VERSION "dbc-export 1 2026.26.6.5"

NS_ :

BS_:

BU_: APB APP APS DAS EPAS3S ESP GTW IBST PARK RADC RCM TPMS TRCM USM

BO_ 921 DAS_status: 8 DAS
 SG_ DAS_autopilotState : 0|4@1+ (1,0) [0|14] "" Vector__XXX
 SG_ DAS_blindSpotRearLeft : 4|2@1+ (1,0) [0|2] "" Vector__XXX
 SG_ DAS_blindSpotRearRight : 6|2@1+ (1,0) [0|2] "" Vector__XXX
 SG_ DAS_fusedSpeedLimit : 8|5@1+ (5,0) [5|150] "kph/mph" Vector__XXX
 SG_ DAS_suppressSpeedWarning : 13|1@1+ (1,0) [0|1] "" Vector__XXX
 SG_ DAS_summonObstacle : 14|1@1+ (1,0) [0|1] "" Vector__XXX
 SG_ DAS_summonClearedGate : 15|1@1+ (1,0) [0|1] "" Vector__XXX
 SG_ DAS_visionOnlySpeedLimit : 16|5@1+ (5,0) [5|150] "kph/mph" Vector__XXX
 SG_ DAS_heaterState : 21|1@1+ (1,0) [0|1] "" Vector__XXX
 SG_ DAS_forwardCollisionWarning : 22|2@1+ (1,0) [0|2] "" Vector__XXX
 SG_ DAS_autoparkReady : 24|1@1+ (1,0) [0|1] "" Vector__XXX
 SG_ DAS_autoParked : 25|1@1+ (1,0) [0|1] "" Vector__XXX
 SG_ DAS_autoparkActive : 26|1@1+ (1,0) [0|1] "" Vector__XXX
 SG_ DAS_summonFwdLeashReached : 27|1@1+ (1,0) [0|1] "" Vector__XXX
 SG_ DAS_summonRvsLeashReached : 28|1@1+ (1,0) [0|1] "" Vector__XXX
 SG_ DAS_lssState : 29|3@1+ (1,0) [0|7] "" Vector__XXX
 SG_ DAS_sideCollisionAvoid : 32|2@1+ (1,0) [0|2] "" Vector__XXX
 SG_ DAS_sideCollisionWarning : 34|2@1+ (1,0) [0|3] "" Vector__XXX
 SG_ DAS_sideCollisionInhibit : 36|1@1+ (1,0) [0|1] "" Vector__XXX
 SG_ DAS_laneDepartureWarning : 37|3@1+ (1,0) [0|7] "" Vector__XXX
 SG_ DAS_fleetSpeedState : 40|2@1+ (1,0) [0|3] "" Vector__XXX
 SG_ DAS_autopilotHandsOnState : 42|4@1+ (1,0) [0|14] "" Vector__XXX
 SG_ DAS_autoLaneChangeState : 46|5@1+ (1,0) [0|30] "" Vector__XXX
 SG_ DAS_summonAvailable : 51|1@1+ (1,0) [0|1] "" Vector__XXX
 SG_ DAS_statusCounter : 52|4@1+ (1,0) [0|15] "" Vector__XXX
 SG_ DAS_statusChecksum : 56|8@1+ (1,0) [0|255] "" Vector__XXX

BO_ 905 DAS_status2: 8 DAS
 SG_ DAS_accSpeedLimit : 0|9@1+ (0.4,0) [0|200] "mph" Vector__XXX
 SG_ DAS_versionIdentifier : 9|1@1+ (1,0) [0|1] "" Vector__XXX
 SG_ DAS_pmmObstacleSeverity : 10|3@1+ (1,0) [0|6] "" Vector__XXX
 SG_ DAS_pmmLoggingRequest : 13|1@1+ (1,0) [0|1] "" Vector__XXX
 SG_ DAS_activationFailureStatus : 14|2@1+ (1,0) [0|3] "" Vector__XXX
 SG_ DAS_pmmUltrasonicsFaultReason : 16|3@1+ (1,0) [0|7] "" Vector__XXX
 SG_ DAS_pmmRadarFaultReason : 19|2@1+ (1,0) [0|3] "" Vector__XXX
 SG_ DAS_pmmSysFaultReason : 21|3@1+ (1,0) [0|7] "" Vector__XXX
 SG_ DAS_pmmCameraFaultReason : 24|2@1+ (1,0) [0|3] "" Vector__XXX
 SG_ DAS_ACC_report : 26|5@1+ (1,0) [0|31] "" Vector__XXX
 SG_ DAS_relaxCruiseLimits : 31|1@1+ (1,0) [0|1] "" Vector__XXX
 SG_ DAS_csaState : 32|2@1+ (1,0) [0|3] "" Vector__XXX
 SG_ DAS_radarTelemetry : 34|2@1+ (1,0) [0|3] "" Vector__XXX
 SG_ DAS_robState : 36|2@1+ (1,0) [0|3] "" Vector__XXX
 SG_ DAS_driverInteractionLevel : 38|2@1+ (1,0) [0|3] "" Vector__XXX
 SG_ DAS_ppOffsetDesiredRamp : 40|8@1+ (0.01,-1.28) [-1.28|1.27] "m" Vector__XXX
 SG_ DAS_longCollisionWarning : 48|4@1+ (1,0) [0|14] "" Vector__XXX
 SG_ DAS_status2Counter : 52|4@1+ (1,0) [0|15] "" Vector__XXX
 SG_ DAS_status2Checksum : 56|8@1+ (1,0) [0|255] "" Vector__XXX

BO_ 586 DAS_visualDebug: 8 DAS
 SG_ DAS_autosteerVehiclesUsage : 4|2@1+ (1,0) [0|3] "" Vector__XXX
 SG_ DAS_autosteerHPPUsage : 6|2@1+ (1,0) [0|3] "" Vector__XXX
 SG_ DAS_autosteerNavigationUsage : 8|2@1+ (1,0) [0|3] "" Vector__XXX
 SG_ DAS_autosteerModelUsage : 10|2@1+ (1,0) [0|3] "" Vector__XXX
 SG_ DAS_autosteerBottsDotsUsage : 12|2@1+ (1,0) [0|3] "" Vector__XXX
 SG_ DAS_offsetSide : 14|2@1+ (1,0) [0|3] "" Vector__XXX
 SG_ DAS_roadSurfaceType : 16|2@1+ (1,0) [1|3] "" Vector__XXX
 SG_ DAS_autosteerHealthAnomalyLevel : 18|3@1+ (1,0) [0|7] "" Vector__XXX
 SG_ DAS_autosteerHealthState : 21|3@1+ (1,0) [0|7] "" Vector__XXX
 SG_ DAS_lastLinePreferenceReason : 24|4@1+ (1,0) [0|15] "" Vector__XXX
 SG_ DAS_plannerState : 28|4@1+ (1,0) [0|15] "" Vector__XXX
 SG_ DAS_lastAutosteerAbortReason : 32|6@1+ (1,0) [0|63] "" Vector__XXX
 SG_ DAS_devAppInterfaceEnabled : 38|1@1+ (1,0) [0|1] "" Vector__XXX
 SG_ DAS_navAvailable : 39|1@1+ (1,0) [0|1] "" Vector__XXX
 SG_ DAS_navDistance : 40|8@1+ (100,0) [0|25500] "km" Vector__XXX
 SG_ DAS_accSmartSpeedActive : 48|1@1+ (1,0) [0|1] "" Vector__XXX
 SG_ DAS_accSmartSpeedState : 49|3@1+ (1,0) [0|6] "" Vector__XXX
 SG_ DAS_ulcInProgress : 52|1@1+ (1,0) [0|1] "" Vector__XXX
 SG_ DAS_trafficAwareSetSpeedInUse : 53|1@1+ (1,0) [0|1] "" Vector__XXX
 SG_ DAS_isaSystemState : 54|2@1+ (1,0) [0|3] "" Vector__XXX
 SG_ DAS_behaviorType : 56|2@1+ (1,0) [0|3] "" Vector__XXX
 SG_ DAS_ulcType : 58|2@1+ (1,0) [0|3] "" Vector__XXX
 SG_ DAS_rearVehDetectedThisCycle : 60|1@1+ (1,0) [0|1] "" Vector__XXX
 SG_ DAS_rearLeftVehDetectedCurrent : 61|1@1+ (1,0) [0|1] "" Vector__XXX
 SG_ DAS_rearRightVehDetectedTrip : 62|1@1+ (1,0) [0|1] "" Vector__XXX
 SG_ DAS_rearLeftVehDetectedTrip : 63|1@1+ (1,0) [0|1] "" Vector__XXX

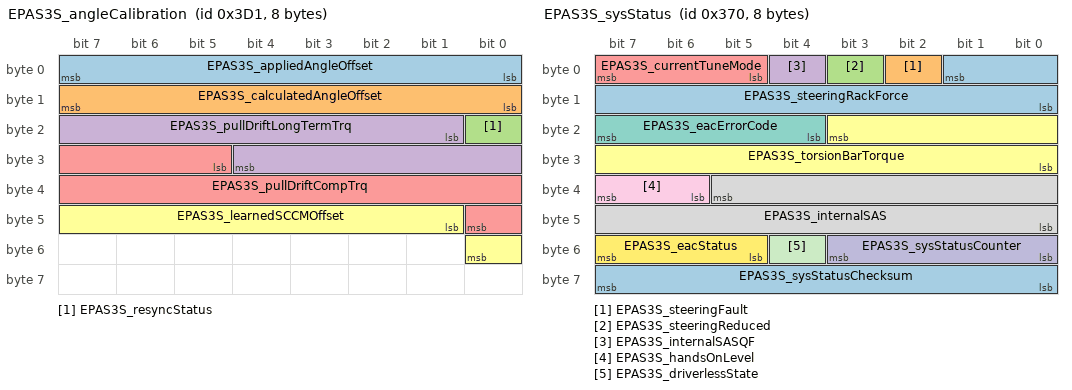
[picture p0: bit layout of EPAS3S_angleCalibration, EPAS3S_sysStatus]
BO_ 977 EPAS3S_angleCalibration: 8 EPAS3S
 SG_ EPAS3S_appliedAngleOffset : 0|8@1+ (0.1,-12.8) [-12.8|12.7] "deg" Vector__XXX
 SG_ EPAS3S_calculatedAngleOffset : 8|8@1+ (0.1,-12.8) [-12.8|12.7] "deg" Vector__XXX
 SG_ EPAS3S_resyncStatus : 16|1@1+ (1,0) [0|1] "" Vector__XXX
 SG_ EPAS3S_pullDriftLongTermTrq : 17|12@1+ (0.01,-10) [-10|10] "Nm" Vector__XXX
 SG_ EPAS3S_pullDriftCompTrq : 29|12@1+ (0.01,-10) [-10|10] "Nm" Vector__XXX
 SG_ EPAS3S_learnedSCCMOffset : 41|8@1+ (0.1,-12.8) [-12.8|12.7] "deg" Vector__XXX

BO_ 785 EPAS3S_info: 8 EPAS3S
 SG_ EPAS3S_infoIndex M : 0|8@1+ (1,0) [0|255] "" Vector__XXX
 SG_ EPAS3S_infoBuildType m10 : 8|8@1+ (1,0) [0|255] "" Vector__XXX
 SG_ EPAS3S_infoComponentID m10 : 48|16@1+ (1,0) [0|65535] "" Vector__XXX
 SG_ EPAS3S_infoPcbaID m11 : 16|8@1+ (1,0) [0|255] "" Vector__XXX
 SG_ EPAS3S_infoAssemblyID m11 : 24|8@1+ (1,0) [0|255] "" Vector__XXX
 SG_ EPAS3S_infoUsageID m11 : 32|16@1+ (1,0) [0|65535] "" Vector__XXX
 SG_ EPAS3S_infoApplicationCRC m13 : 32|32@1+ (1,0) [0|4294967295] "" Vector__XXX
 SG_ EPAS3S_infoBootUdsProtoVersion m20 : 8|8@1+ (1,0) [0|255] "" Vector__XXX
 SG_ EPAS3S_infoBootloaderCRC m20 : 32|32@1+ (1,0) [0|4294967295] "" Vector__XXX
 SG_ EPAS3S_infoSubcomponent2 m23 : 32|32@1+ (1,0) [0|4294967295] "" Vector__XXX

BO_ 880 EPAS3S_sysStatus: 8 EPAS3S
 SG_ EPAS3S_steeringRackForce : 1|10@0+ (50,-25575) [-25575|25525] "N" Vector__XXX
 SG_ EPAS3S_steeringFault : 2|1@1+ (1,0) [0|1] "" Vector__XXX
 SG_ EPAS3S_steeringReduced : 3|1@1+ (1,0) [0|1] "" Vector__XXX
 SG_ EPAS3S_internalSASQF : 4|1@1+ (1,0) [0|1] "" Vector__XXX
 SG_ EPAS3S_currentTuneMode : 5|3@1+ (1,0) [0|7] "" Vector__XXX
 SG_ EPAS3S_torsionBarTorque : 19|12@0+ (0.01,-20.5) [-20.5|20.44] "Nm" Vector__XXX
 SG_ EPAS3S_eacErrorCode : 20|4@1+ (1,0) [0|14] "" Vector__XXX
 SG_ EPAS3S_internalSAS : 37|14@0+ (0.1,-819.2) [-819.2|819] "deg" Vector__XXX
 SG_ EPAS3S_handsOnLevel : 38|2@1+ (1,0) [0|3] "" Vector__XXX
 SG_ EPAS3S_sysStatusCounter : 48|4@1+ (1,0) [0|15] "" Vector__XXX
 SG_ EPAS3S_driverlessState : 52|1@1+ (1,0) [0|1] "" Vector__XXX
 SG_ EPAS3S_eacStatus : 53|3@1+ (1,0) [0|7] "" Vector__XXX
 SG_ EPAS3S_sysStatusChecksum : 56|8@1+ (1,0) [0|255] "" Vector__XXX

BO_ 805 ESP_info: 8 ESP
 SG_ ESP_infoIndex M : 0|8@1+ (1,0) [0|255] "" Vector__XXX
 SG_ ESP_infoBuildType m10 : 8|8@1+ (1,0) [0|255] "" Vector__XXX
 SG_ ESP_infoComponentID m10 : 48|16@1+ (1,0) [0|65535] "" Vector__XXX
 SG_ ESP_infoPcbaID m11 : 16|8@1+ (1,0) [0|255] "" Vector__XXX
 SG_ ESP_infoAssemblyID m11 : 24|8@1+ (1,0) [0|255] "" Vector__XXX
 SG_ ESP_infoUsageID m11 : 32|16@1+ (1,0) [0|65535] "" Vector__XXX
 SG_ ESP_infoSubUsageID m11 : 48|16@1+ (1,0) [0|65535] "" Vector__XXX
 SG_ ESP_infoApplicationCRC m13 : 39|32@0+ (1,0) [0|4294967295] "" Vector__XXX
 SG_ ESP_infoVehicleVariant m16 : 16|8@1+ (1,0) [0|255] "" Vector__XXX
 SG_ ESP_infoSubcomponent1 m16 : 32|32@1+ (1,0) [0|4294967295] "" Vector__XXX
 SG_ ESP_infoBootUdsProtoVersion m20 : 8|8@1+ (1,0) [0|255] "" Vector__XXX
 SG_ ESP_infoBootloaderCRC m20 : 32|32@1+ (1,0) [0|4294967295] "" Vector__XXX
 SG_ ESP_infoVariantCRC m22 : 39|32@0+ (1,0) [0|4294967295] "" Vector__XXX

BO_ 813 IBST_info: 8 IBST
 SG_ IBST_infoIndex M : 0|8@1+ (1,0) [0|255] "" Vector__XXX
 SG_ IBST_infoBuildType m10 : 8|8@1+ (1,0) [0|255] "" Vector__XXX
 SG_ IBST_infoComponentID m10 : 55|16@0+ (1,0) [0|65535] "" Vector__XXX
 SG_ IBST_infoPcbaID m11 : 16|8@1+ (1,0) [0|255] "" Vector__XXX
 SG_ IBST_infoAssemblyID m11 : 24|8@1+ (1,0) [0|255] "" Vector__XXX
 SG_ IBST_infoUsageID m11 : 32|16@1+ (1,0) [0|65535] "" Vector__XXX
 SG_ IBST_infoSubUsageID m11 : 48|16@1+ (1,0) [0|65535] "" Vector__XXX
 SG_ IBST_infoApplicationCRC m13 : 32|32@1+ (1,0) [0|4294967295] "" Vector__XXX
 SG_ IBST_infoBootUdsProtoVersion m20 : 8|8@1+ (1,0) [0|255] "" Vector__XXX
 SG_ IBST_infoBootloaderCRC m20 : 32|32@1+ (1,0) [0|4294967295] "" Vector__XXX
 SG_ IBST_infoVariantCRC m22 : 32|32@1+ (1,0) [0|4294967295] "" Vector__XXX

BO_ 806 PARK_info: 8 PARK
 SG_ PARK_infoIndex M : 0|8@1+ (1,0) [0|255] "" Vector__XXX
 SG_ PARK_infoBuildType m10 : 8|8@1+ (1,0) [0|255] "" Vector__XXX
 SG_ PARK_infoComponentID m10 : 48|16@1+ (1,0) [0|65535] "" Vector__XXX
 SG_ PARK_infoPcbaID m11 : 16|8@1+ (1,0) [0|255] "" Vector__XXX
 SG_ PARK_infoAssemblyID m11 : 24|8@1+ (1,0) [0|255] "" Vector__XXX
 SG_ PARK_infoUsageID m11 : 32|16@1+ (1,0) [0|65535] "" Vector__XXX
 SG_ PARK_infoApplicationCRC m13 : 32|32@1+ (1,0) [0|4294967295] "" Vector__XXX
 SG_ PARK_infoBootUdsProtoVersion m20 : 8|8@1+ (1,0) [0|255] "" Vector__XXX
 SG_ PARK_infoBootloaderCRC m20 : 32|32@1+ (1,0) [0|4294967295] "" Vector__XXX

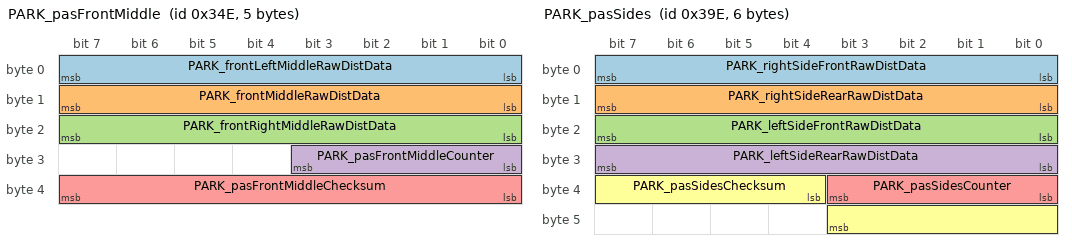
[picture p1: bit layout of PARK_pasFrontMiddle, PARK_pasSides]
BO_ 846 PARK_pasFrontMiddle: 5 PARK
 SG_ PARK_frontLeftMiddleRawDistData : 0|8@1+ (1,0) [0|254] "cm" Vector__XXX
 SG_ PARK_frontMiddleRawDistData : 8|8@1+ (1,0) [0|254] "cm" Vector__XXX
 SG_ PARK_frontRightMiddleRawDistData : 16|8@1+ (1,0) [0|254] "cm" Vector__XXX
 SG_ PARK_pasFrontMiddleCounter : 24|4@1+ (1,0) [0|15] "" Vector__XXX
 SG_ PARK_pasFrontMiddleChecksum : 32|8@1+ (1,0) [0|255] "" Vector__XXX

BO_ 926 PARK_pasSides: 6 PARK
 SG_ PARK_rightSideFrontRawDistData : 0|8@1+ (1,0) [0|254] "cm" Vector__XXX
 SG_ PARK_rightSideRearRawDistData : 8|8@1+ (1,0) [0|254] "cm" Vector__XXX
 SG_ PARK_leftSideFrontRawDistData : 16|8@1+ (1,0) [0|254] "cm" Vector__XXX
 SG_ PARK_leftSideRearRawDistData : 24|8@1+ (1,0) [0|254] "cm" Vector__XXX
 SG_ PARK_pasSidesCounter : 32|4@1+ (1,0) [0|15] "" Vector__XXX
 SG_ PARK_pasSidesChecksum : 36|8@1+ (1,0) [0|255] "" Vector__XXX

BO_ 606 PARK_pscEnvSlot: 8 PARK
 SG_ PARK_pscEnvSlotType M : 0|2@1+ (1,0) [0|3] "" Vector__XXX
 SG_ PARK_pscLeftParallelObj1X m0 : 3|11@1+ (2,-2048) [-2048|2044] "cm" Vector__XXX
 SG_ PARK_pscLeftParallelObj1Y m0 : 14|11@1+ (2,-2048) [-2048|2044] "cm" Vector__XXX
 SG_ PARK_pscLeftParallelObj1Alpha m0 : 25|7@1+ (2,-128) [-128|124] "deg" Vector__XXX
 SG_ PARK_pscLeftParallelObj2Y m0 : 35|11@1+ (2,-2048) [-2048|2044] "cm" Vector__XXX
 SG_ PARK_pscLeftParallelObj2X m0 : 46|11@1+ (2,-2048) [-2048|2044] "cm" Vector__XXX
 SG_ PARK_pscLeftParallelObj2Alpha m0 : 57|7@1+ (2,-128) [-128|124] "deg" Vector__XXX
 SG_ PARK_pscLeftCrossObj1X m1 : 3|11@1+ (2,-2048) [-2048|2044] "cm" Vector__XXX
 SG_ PARK_pscLeftCrossObj1Y m1 : 14|11@1+ (2,-2048) [-2048|2044] "cm" Vector__XXX
 SG_ PARK_pscLeftCrossObj1Alpha m1 : 25|7@1+ (2,-128) [-128|124] "deg" Vector__XXX
 SG_ PARK_pscLeftCrossObj2Y m1 : 35|11@1+ (2,-2048) [-2048|2044] "cm" Vector__XXX
 SG_ PARK_pscLeftCrossObj2X m1 : 46|11@1+ (2,-2048) [-2048|2044] "cm" Vector__XXX
 SG_ PARK_pscLeftCrossObj2Alpha m1 : 57|7@1+ (2,-128) [-128|124] "deg" Vector__XXX
 SG_ PARK_pscRightParallelObj1X m2 : 3|11@1+ (2,-2048) [-2048|2044] "cm" Vector__XXX
 SG_ PARK_pscRightParallelObj1Y m2 : 14|11@1+ (2,-2048) [-2048|2044] "cm" Vector__XXX
 SG_ PARK_pscRightParallelObj1Alpha m2 : 25|7@1+ (2,-128) [-128|124] "deg" Vector__XXX
 SG_ PARK_pscRightParallelObj2Y m2 : 35|11@1+ (2,-2048) [-2048|2044] "cm" Vector__XXX
 SG_ PARK_pscRightParallelObj2X m2 : 46|11@1+ (2,-2048) [-2048|2044] "cm" Vector__XXX
 SG_ PARK_pscRightParallelObj2Alpha m2 : 57|7@1+ (2,-128) [-128|124] "deg" Vector__XXX
 SG_ PARK_pscRightCrossObj1X m3 : 3|11@1+ (2,-2048) [-2048|2044] "cm" Vector__XXX
 SG_ PARK_pscRightCrossObj1Y m3 : 14|11@1+ (2,-2048) [-2048|2044] "cm" Vector__XXX
 SG_ PARK_pscRightCrossObj1Alpha m3 : 25|7@1+ (2,-128) [-128|124] "deg" Vector__XXX
 SG_ PARK_pscRightCrossObj2Y m3 : 35|11@1+ (2,-2048) [-2048|2044] "cm" Vector__XXX
 SG_ PARK_pscRightCrossObj2X m3 : 46|11@1+ (2,-2048) [-2048|2044] "cm" Vector__XXX
 SG_ PARK_pscRightCrossObj2Alpha m3 : 57|7@1+ (2,-128) [-128|124] "deg" Vector__XXX

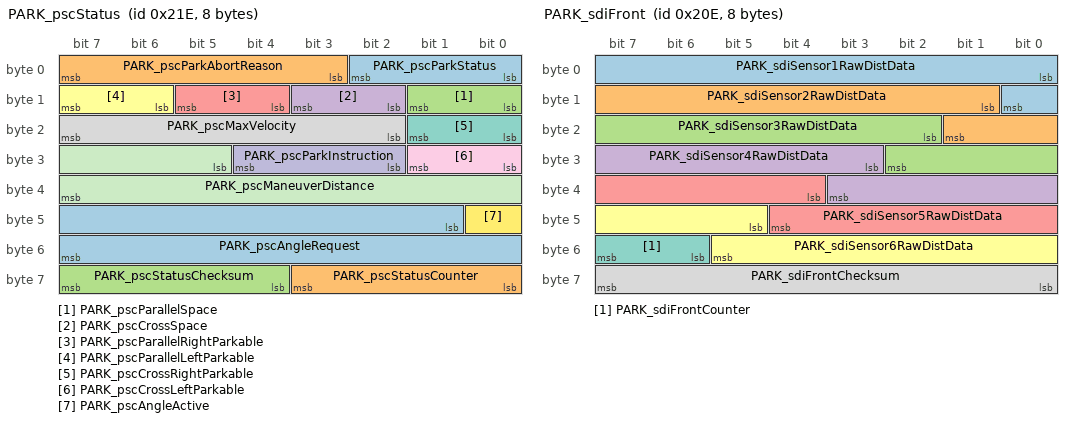
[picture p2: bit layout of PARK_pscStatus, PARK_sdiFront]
BO_ 542 PARK_pscStatus: 8 PARK
 SG_ PARK_pscParkStatus : 0|3@1+ (1,0) [0|6] "" Vector__XXX
 SG_ PARK_pscParkAbortReason : 3|5@1+ (1,0) [0|30] "" Vector__XXX
 SG_ PARK_pscParallelSpace : 8|2@1+ (1,0) [0|3] "" Vector__XXX
 SG_ PARK_pscCrossSpace : 10|2@1+ (1,0) [0|3] "" Vector__XXX
 SG_ PARK_pscParallelRightParkable : 12|2@1+ (1,0) [0|2] "" Vector__XXX
 SG_ PARK_pscParallelLeftParkable : 14|2@1+ (1,0) [0|2] "" Vector__XXX
 SG_ PARK_pscCrossRightParkable : 16|2@1+ (1,0) [0|2] "" Vector__XXX
 SG_ PARK_pscMaxVelocity : 18|6@1+ (0.1,0) [0|6.2] "kph" Vector__XXX
 SG_ PARK_pscCrossLeftParkable : 24|2@1+ (1,0) [0|2] "" Vector__XXX
 SG_ PARK_pscParkInstruction : 26|3@1+ (1,0) [0|6] "" Vector__XXX
 SG_ PARK_pscManeuverDistance : 29|11@1+ (1,0) [0|2046] "cm" Vector__XXX
 SG_ PARK_pscAngleActive : 40|1@1+ (1,0) [0|1] "" Vector__XXX
 SG_ PARK_pscAngleRequest : 41|15@1+ (0.1,-1638.4) [-1638.4|1638.3] "deg" Vector__XXX
 SG_ PARK_pscStatusCounter : 56|4@1+ (1,0) [0|15] "" Vector__XXX
 SG_ PARK_pscStatusChecksum : 60|4@1+ (1,0) [0|15] "" Vector__XXX

BO_ 590 PARK_pscVehSlot: 8 PARK
 SG_ PARK_pscVehSlotType M : 0|2@1+ (1,0) [0|3] "" Vector__XXX
 SG_ PARK_pscLeftParallelVehX m0 : 5|11@1+ (2,-2048) [-2048|2044] "cm" Vector__XXX
 SG_ PARK_pscLeftParallelVehY m0 : 16|11@1+ (2,-2048) [-2048|2044] "cm" Vector__XXX
 SG_ PARK_pscLeftParallelPsi m0 : 32|13@1+ (0.0009765625,0) [0|7.998046875] "radians" Vector__XXX
 SG_ PARK_pscLeftParallelSizeX m0 : 48|8@1+ (4,0) [0|1016] "cm" Vector__XXX
 SG_ PARK_pscLeftParallelSizeY m0 : 56|8@1+ (4,0) [0|1016] "cm" Vector__XXX
 SG_ PARK_pscLeftCrossVehX m1 : 5|11@1+ (2,-2048) [-2048|2044] "cm" Vector__XXX
 SG_ PARK_pscLeftCrossVehY m1 : 16|11@1+ (2,-2048) [-2048|2044] "cm" Vector__XXX
 SG_ PARK_pscLeftCrossPsi m1 : 32|13@1+ (0.0009765625,0) [0|7.998046875] "radians" Vector__XXX
 SG_ PARK_pscLeftCrossSizeX m1 : 48|8@1+ (4,0) [0|1016] "cm" Vector__XXX
 SG_ PARK_pscLeftCrossSizeY m1 : 56|8@1+ (4,0) [0|1016] "cm" Vector__XXX
 SG_ PARK_pscRightParallelVehX m2 : 5|11@1+ (2,-2048) [-2048|2044] "cm" Vector__XXX
 SG_ PARK_pscRightParallelVehY m2 : 16|11@1+ (2,-2048) [-2048|2044] "cm" Vector__XXX
 SG_ PARK_pscRightParallelPsi m2 : 32|13@1+ (0.0009765625,0) [0|7.998046875] "radians" Vector__XXX
 SG_ PARK_pscRightParallelSizeX m2 : 48|8@1+ (4,0) [0|1016] "cm" Vector__XXX
 SG_ PARK_pscRightParallelSizeY m2 : 56|8@1+ (4,0) [0|1016] "cm" Vector__XXX
 SG_ PARK_pscRightCrossVehX m3 : 5|11@1+ (2,-2048) [-2048|2044] "cm" Vector__XXX
 SG_ PARK_pscRightCrossVehY m3 : 16|11@1+ (2,-2048) [-2048|2044] "cm" Vector__XXX
 SG_ PARK_pscRightCrossPsi m3 : 32|13@1+ (0.0009765625,0) [0|7.998046875] "radians" Vector__XXX
 SG_ PARK_pscRightCrossSizeX m3 : 48|8@1+ (4,0) [0|1016] "cm" Vector__XXX
 SG_ PARK_pscRightCrossSizeY m3 : 56|8@1+ (4,0) [0|1016] "cm" Vector__XXX

BO_ 526 PARK_sdiFront: 8 PARK
 SG_ PARK_sdiSensor1RawDistData : 0|9@1+ (1,0) [0|510] "cm" Vector__XXX
 SG_ PARK_sdiSensor2RawDistData : 9|9@1+ (1,0) [0|510] "cm" Vector__XXX
 SG_ PARK_sdiSensor3RawDistData : 18|9@1+ (1,0) [0|510] "cm" Vector__XXX
 SG_ PARK_sdiSensor4RawDistData : 27|9@1+ (1,0) [0|510] "cm" Vector__XXX
 SG_ PARK_sdiSensor5RawDistData : 36|9@1+ (1,0) [0|510] "cm" Vector__XXX
 SG_ PARK_sdiSensor6RawDistData : 45|9@1+ (1,0) [0|510] "cm" Vector__XXX
 SG_ PARK_sdiFrontCounter : 54|2@1+ (1,0) [0|3] "" Vector__XXX
 SG_ PARK_sdiFrontChecksum : 56|8@1+ (1,0) [0|255] "" Vector__XXX

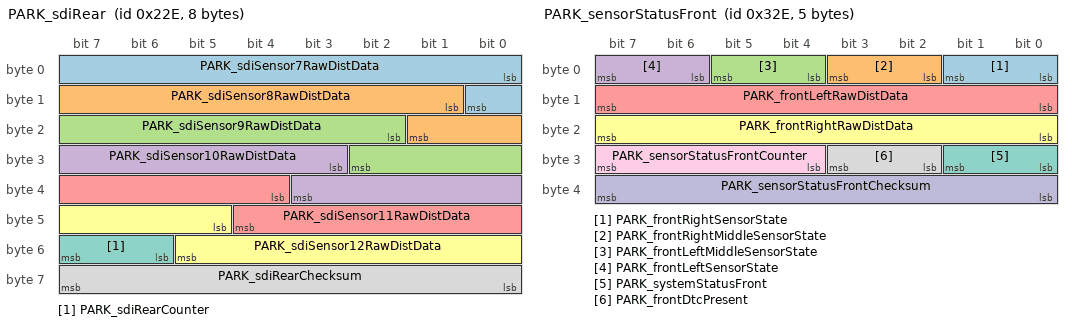
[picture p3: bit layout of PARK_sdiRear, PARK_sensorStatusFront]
BO_ 558 PARK_sdiRear: 8 PARK
 SG_ PARK_sdiSensor7RawDistData : 0|9@1+ (1,0) [0|510] "cm" Vector__XXX
 SG_ PARK_sdiSensor8RawDistData : 9|9@1+ (1,0) [0|510] "cm" Vector__XXX
 SG_ PARK_sdiSensor9RawDistData : 18|9@1+ (1,0) [0|510] "cm" Vector__XXX
 SG_ PARK_sdiSensor10RawDistData : 27|9@1+ (1,0) [0|510] "cm" Vector__XXX
 SG_ PARK_sdiSensor11RawDistData : 36|9@1+ (1,0) [0|510] "cm" Vector__XXX
 SG_ PARK_sdiSensor12RawDistData : 45|9@1+ (1,0) [0|510] "cm" Vector__XXX
 SG_ PARK_sdiRearCounter : 54|2@1+ (1,0) [0|3] "" Vector__XXX
 SG_ PARK_sdiRearChecksum : 56|8@1+ (1,0) [0|255] "" Vector__XXX

BO_ 814 PARK_sensorStatusFront: 5 PARK
 SG_ PARK_frontRightSensorState : 0|2@1+ (1,0) [0|2] "" Vector__XXX
 SG_ PARK_frontRightMiddleSensorState : 2|2@1+ (1,0) [0|2] "" Vector__XXX
 SG_ PARK_frontLeftMiddleSensorState : 4|2@1+ (1,0) [0|2] "" Vector__XXX
 SG_ PARK_frontLeftSensorState : 6|2@1+ (1,0) [0|2] "" Vector__XXX
 SG_ PARK_frontLeftRawDistData : 8|8@1+ (1,0) [0|254] "cm" Vector__XXX
 SG_ PARK_frontRightRawDistData : 16|8@1+ (1,0) [0|254] "cm" Vector__XXX
 SG_ PARK_systemStatusFront : 24|2@1+ (1,0) [0|2] "" Vector__XXX
 SG_ PARK_frontDtcPresent : 26|2@1+ (1,0) [0|2] "" Vector__XXX
 SG_ PARK_sensorStatusFrontCounter : 28|4@1+ (1,0) [0|15] "" Vector__XXX
 SG_ PARK_sensorStatusFrontChecksum : 32|8@1+ (1,0) [0|255] "" Vector__XXX

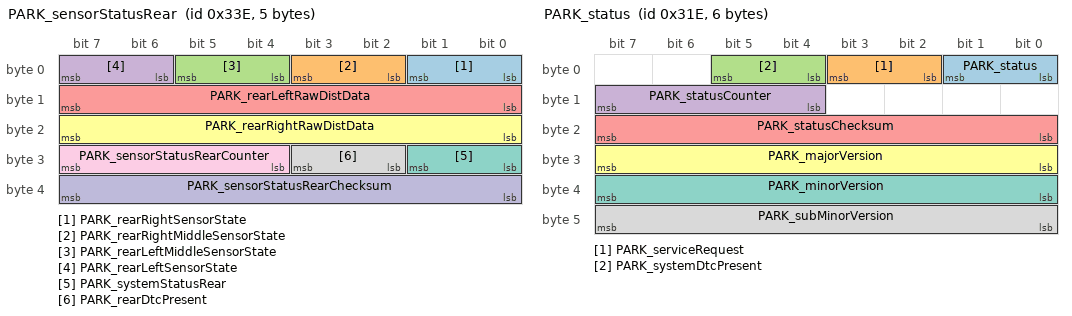
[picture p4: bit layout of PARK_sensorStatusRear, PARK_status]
BO_ 830 PARK_sensorStatusRear: 5 PARK
 SG_ PARK_rearRightSensorState : 0|2@1+ (1,0) [0|2] "" Vector__XXX
 SG_ PARK_rearRightMiddleSensorState : 2|2@1+ (1,0) [0|2] "" Vector__XXX
 SG_ PARK_rearLeftMiddleSensorState : 4|2@1+ (1,0) [0|2] "" Vector__XXX
 SG_ PARK_rearLeftSensorState : 6|2@1+ (1,0) [0|2] "" Vector__XXX
 SG_ PARK_rearLeftRawDistData : 8|8@1+ (1,0) [0|254] "cm" Vector__XXX
 SG_ PARK_rearRightRawDistData : 16|8@1+ (1,0) [0|254] "cm" Vector__XXX
 SG_ PARK_systemStatusRear : 24|2@1+ (1,0) [0|2] "" Vector__XXX
 SG_ PARK_rearDtcPresent : 26|2@1+ (1,0) [0|2] "" Vector__XXX
 SG_ PARK_sensorStatusRearCounter : 28|4@1+ (1,0) [0|15] "" Vector__XXX
 SG_ PARK_sensorStatusRearChecksum : 32|8@1+ (1,0) [0|255] "" Vector__XXX

BO_ 798 PARK_status: 6 PARK
 SG_ PARK_status : 0|2@1+ (1,0) [0|2] "" Vector__XXX
 SG_ PARK_serviceRequest : 2|2@1+ (1,0) [0|2] "" Vector__XXX
 SG_ PARK_systemDtcPresent : 4|2@1+ (1,0) [0|2] "" Vector__XXX
 SG_ PARK_statusCounter : 12|4@1+ (1,0) [0|15] "" Vector__XXX
 SG_ PARK_statusChecksum : 16|8@1+ (1,0) [0|255] "" Vector__XXX
 SG_ PARK_majorVersion : 24|8@1+ (1,0) [0|254] "" Vector__XXX
 SG_ PARK_minorVersion : 32|8@1+ (1,0) [0|254] "" Vector__XXX
 SG_ PARK_subMinorVersion : 40|8@1+ (1,0) [0|254] "" Vector__XXX

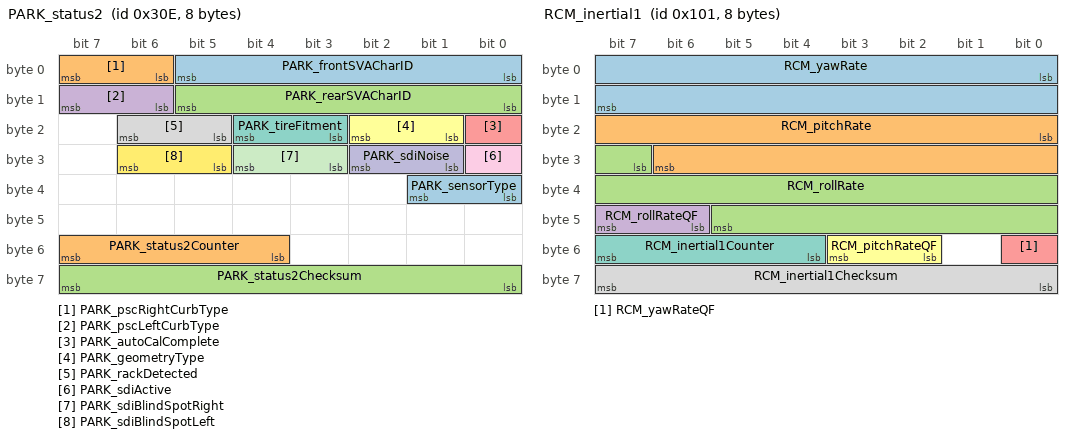
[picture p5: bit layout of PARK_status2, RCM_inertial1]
BO_ 782 PARK_status2: 8 PARK
 SG_ PARK_frontSVACharID : 0|6@1+ (1,0) [0|63] "" Vector__XXX
 SG_ PARK_pscRightCurbType : 6|2@1+ (1,0) [0|3] "" Vector__XXX
 SG_ PARK_rearSVACharID : 8|6@1+ (1,0) [0|63] "" Vector__XXX
 SG_ PARK_pscLeftCurbType : 14|2@1+ (1,0) [0|3] "" Vector__XXX
 SG_ PARK_autoCalComplete : 16|1@1+ (1,0) [0|1] "" Vector__XXX
 SG_ PARK_geometryType : 17|2@1+ (1,0) [0|3] "" Vector__XXX
 SG_ PARK_tireFitment : 19|2@1+ (1,0) [0|2] "" Vector__XXX
 SG_ PARK_rackDetected : 21|2@1+ (1,0) [0|2] "" Vector__XXX
 SG_ PARK_sdiActive : 24|1@1+ (1,0) [0|1] "" Vector__XXX
 SG_ PARK_sdiNoise : 25|2@1+ (1,0) [0|2] "" Vector__XXX
 SG_ PARK_sdiBlindSpotRight : 27|2@1+ (1,0) [0|2] "" Vector__XXX
 SG_ PARK_sdiBlindSpotLeft : 29|2@1+ (1,0) [0|2] "" Vector__XXX
 SG_ PARK_sensorType : 32|2@1+ (1,0) [0|2] "" Vector__XXX
 SG_ PARK_status2Counter : 52|4@1+ (1,0) [0|15] "" Vector__XXX
 SG_ PARK_status2Checksum : 56|8@1+ (1,0) [0|255] "" Vector__XXX

BO_ 1329 RADC_info: 8 RADC
 SG_ RADC_infoIndex M : 0|8@1+ (1,0) [0|255] "" Vector__XXX
 SG_ RADC_infoBuildType m10 : 8|8@1+ (1,0) [0|255] "" Vector__XXX
 SG_ RADC_infoBuildConfigID m10 : 16|16@1+ (1,0) [0|65535] "" Vector__XXX
 SG_ RADC_infoHardwareID m10 : 32|16@1+ (1,0) [0|65535] "" Vector__XXX
 SG_ RADC_infoComponentID m10 : 48|16@1+ (1,0) [0|65535] "" Vector__XXX
 SG_ RADC_infoPcbaID m11 : 16|8@1+ (1,0) [0|255] "" Vector__XXX
 SG_ RADC_infoAssemblyID m11 : 24|8@1+ (1,0) [0|255] "" Vector__XXX
 SG_ RADC_infoUsageID m11 : 32|16@1+ (1,0) [0|65535] "" Vector__XXX
 SG_ RADC_infoSubUsageID m11 : 48|16@1+ (1,0) [0|65535] "" Vector__XXX
 SG_ RADC_infoApplicationCRC m13 : 32|32@1+ (1,0) [0|4294967295] "" Vector__XXX
 SG_ RADC_infoPlatformType m19 : 8|8@1+ (1,0) [0|255] "" Vector__XXX
 SG_ RADC_infoMajorVersion m19 : 16|8@1+ (1,0) [0|255] "" Vector__XXX
 SG_ RADC_infoBranchOrigin m19 : 24|8@1+ (1,0) [0|255] "" Vector__XXX
 SG_ RADC_infoMaturity m19 : 32|8@1+ (1,0) [0|255] "" Vector__XXX
 SG_ RADC_infoHardwareRevision m19 : 40|8@1+ (1,0) [0|255] "" Vector__XXX
 SG_ RADC_infoBootUdsProtoVersion m20 : 8|8@1+ (1,0) [0|255] "" Vector__XXX
 SG_ RADC_infoBootloaderCRC m20 : 32|32@1+ (1,0) [0|4294967295] "" Vector__XXX

BO_ 257 RCM_inertial1: 8 RCM
 SG_ RCM_yawRate : 0|16@1- (0.0001,0) [-3.2766|3.2766] "rad/s" Vector__XXX
 SG_ RCM_pitchRate : 16|15@1- (0.00025,0) [-4.096|4.09575] "rad/s" Vector__XXX
 SG_ RCM_rollRate : 31|15@1- (0.00025,0) [-4.096|4.09575] "rad/s" Vector__XXX
 SG_ RCM_rollRateQF : 46|2@1+ (1,0) [0|3] "" Vector__XXX
 SG_ RCM_yawRateQF : 48|1@1+ (1,0) [0|1] "" Vector__XXX
 SG_ RCM_pitchRateQF : 50|2@1+ (1,0) [0|3] "" Vector__XXX
 SG_ RCM_inertial1Counter : 52|4@1+ (1,0) [0|15] "" Vector__XXX
 SG_ RCM_inertial1Checksum : 56|8@1+ (1,0) [0|255] "" Vector__XXX

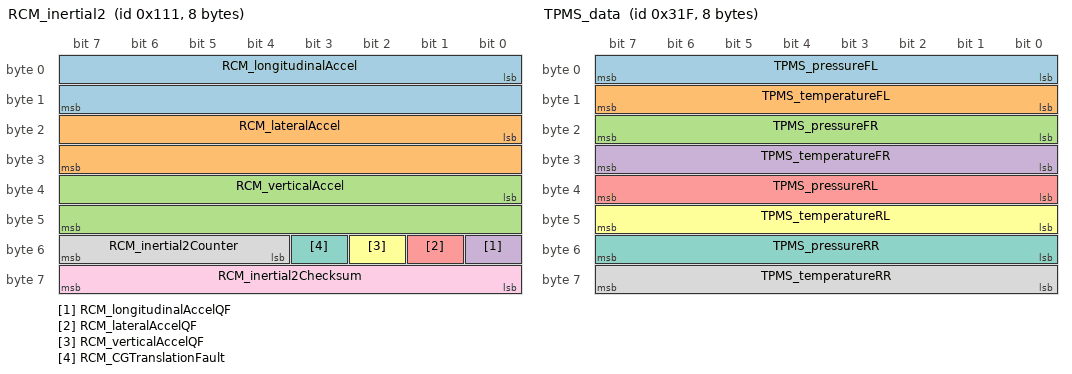
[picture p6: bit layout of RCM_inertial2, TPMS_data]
BO_ 273 RCM_inertial2: 8 RCM
 SG_ RCM_longitudinalAccel : 0|16@1- (0.00125,0) [-40.9575|40.9575] "m/s^2" Vector__XXX
 SG_ RCM_lateralAccel : 16|16@1- (0.00125,0) [-40.9575|40.9575] "m/s^2" Vector__XXX
 SG_ RCM_verticalAccel : 32|16@1- (0.00125,0) [-40.9575|39.2] "m/s^2" Vector__XXX
 SG_ RCM_longitudinalAccelQF : 48|1@1+ (1,0) [0|1] "" Vector__XXX
 SG_ RCM_lateralAccelQF : 49|1@1+ (1,0) [0|1] "" Vector__XXX
 SG_ RCM_verticalAccelQF : 50|1@1+ (1,0) [0|1] "" Vector__XXX
 SG_ RCM_CGTranslationFault : 51|1@1+ (1,0) [0|1] "" Vector__XXX
 SG_ RCM_inertial2Counter : 52|4@1+ (1,0) [0|15] "" Vector__XXX
 SG_ RCM_inertial2Checksum : 56|8@1+ (1,0) [0|255] "" Vector__XXX

BO_ 849 RCM_info: 8 RCM
 SG_ RCM_infoIndex M : 0|8@1+ (1,0) [0|255] "" Vector__XXX
 SG_ RCM_infoBuildType m10 : 8|8@1+ (1,0) [0|255] "" Vector__XXX
 SG_ RCM_infoComponentID m10 : 48|16@1+ (1,0) [0|65535] "" Vector__XXX
 SG_ RCM_infoPcbaID m11 : 16|8@1+ (1,0) [0|255] "" Vector__XXX
 SG_ RCM_infoAssemblyID m11 : 24|8@1+ (1,0) [0|255] "" Vector__XXX
 SG_ RCM_infoUsageID m11 : 32|16@1+ (1,0) [0|65535] "" Vector__XXX
 SG_ RCM_infoApplicationCRC m13 : 32|32@1+ (1,0) [0|4294967295] "" Vector__XXX
 SG_ RCM_infoBootUdsProtoVersion m20 : 8|8@1+ (1,0) [0|255] "" Vector__XXX
 SG_ RCM_infoBootloaderCRC m20 : 32|32@1+ (1,0) [0|4294967295] "" Vector__XXX
 SG_ RCM_infoAlgoCalID m22 : 8|8@1+ (1,0) [0|255] "" Vector__XXX
 SG_ RCM_infoVariantCRC m22 : 32|32@1+ (1,0) [0|4294967295] "" Vector__XXX

BO_ 529 RCM_status: 6 RCM
 SG_ RCM_statusChecksum : 0|8@1+ (1,0) [0|255] "" Vector__XXX
 SG_ RCM_statusCounter : 8|4@1+ (1,0) [0|15] "" Vector__XXX
 SG_ RCM_armStatus : 12|2@1+ (1,0) [0|2] "" Vector__XXX
 SG_ RCM_warningIndicatorState : 14|2@1+ (1,0) [0|2] "" Vector__XXX
 SG_ RCM_passAirbagIndicatorRequest : 16|2@1+ (1,0) [0|2] "" Vector__XXX
 SG_ RCM_airbagCutoffStatus : 18|2@1+ (1,0) [0|2] "" Vector__XXX
 SG_ RCM_alrSwitchStatus : 20|2@1+ (1,0) [0|2] "" Vector__XXX
 SG_ RCM_vinLearnFlag : 22|2@1+ (1,0) [0|2] "" Vector__XXX
 SG_ RCM_seatTrackPositionDrvr : 24|2@1+ (1,0) [0|2] "" Vector__XXX
 SG_ RCM_seatTrackPositionPass : 26|2@1+ (1,0) [0|2] "" Vector__XXX
 SG_ RCM_edr1State : 28|2@1+ (1,0) [0|3] "" Vector__XXX
 SG_ RCM_edr2State : 30|2@1+ (1,0) [0|3] "" Vector__XXX
 SG_ RCM_keepPowerReason : 32|4@1+ (1,0) [0|15] "" Vector__XXX
 SG_ RCM_imuOffsetLearnState : 36|2@1+ (1,0) [0|3] "" Vector__XXX
 SG_ RCM_edr3State : 38|2@1+ (1,0) [0|3] "" Vector__XXX
 SG_ RCM_driverOrientationInitStatus : 40|3@1+ (1,0) [0|6] "" Vector__XXX
 SG_ RCM_occupantClassificationSource : 43|1@1+ (1,0) [0|1] "" Vector__XXX
 SG_ RCM_pedProEDR1State : 44|2@1+ (1,0) [0|3] "" Vector__XXX
 SG_ RCM_pedProEDR2State : 46|2@1+ (1,0) [0|3] "" Vector__XXX

BO_ 879 TPMS_StatusC: 8 TPMS
 SG_ TPMS_c_globalHardWarning : 0|1@1+ (1,0) [0|1] "" Vector__XXX
 SG_ TPMS_c_globalSoftWarning : 1|1@1+ (1,0) [0|1] "" Vector__XXX
 SG_ TPMS_systemMalfunction : 2|1@1+ (1,0) [0|1] "" Vector__XXX
 SG_ TPMS_WA_version : 3|1@1+ (1,0) [0|1] "" Vector__XXX
 SG_ TPMS_globalDeltaPressure : 4|1@1+ (1,0) [0|1] "" Vector__XXX
 SG_ TPMS_newSensorLearnt : 5|3@1+ (1,0) [0|7] "" Vector__XXX
 SG_ TPMS_softWarningRR : 8|1@1+ (1,0) [0|1] "" Vector__XXX
 SG_ TPMS_hardWarningRR : 9|1@1+ (1,0) [0|1] "" Vector__XXX
 SG_ TPMS_softWarningRL : 10|1@1+ (1,0) [0|1] "" Vector__XXX
 SG_ TPMS_hardWarningRL : 11|1@1+ (1,0) [0|1] "" Vector__XXX
 SG_ TPMS_softWarningFR : 12|1@1+ (1,0) [0|1] "" Vector__XXX
 SG_ TPMS_hardWarningFR : 13|1@1+ (1,0) [0|1] "" Vector__XXX
 SG_ TPMS_softWarningFL : 14|1@1+ (1,0) [0|1] "" Vector__XXX
 SG_ TPMS_hardWarningFL : 15|1@1+ (1,0) [0|1] "" Vector__XXX
 SG_ TPMS_learningStatus : 16|2@1+ (1,0) [0|3] "" Vector__XXX
 SG_ TPMS_localisationStatus : 18|2@1+ (1,0) [0|3] "" Vector__XXX
 SG_ TPMS_deltaPressWarningFL : 20|1@1+ (1,0) [0|1] "" Vector__XXX
 SG_ TPMS_deltaPressWarningFR : 21|1@1+ (1,0) [0|1] "" Vector__XXX
 SG_ TPMS_deltaPressWarningRL : 22|1@1+ (1,0) [0|1] "" Vector__XXX
 SG_ TPMS_deltaPressWarningRR : 23|1@1+ (1,0) [0|1] "" Vector__XXX
 SG_ TPMS_sensorNoResponseFL : 24|1@1+ (1,0) [0|1] "" Vector__XXX
 SG_ TPMS_sensorNoResponseFR : 25|1@1+ (1,0) [0|1] "" Vector__XXX
 SG_ TPMS_sensorNoResponseRL : 26|1@1+ (1,0) [0|1] "" Vector__XXX
 SG_ TPMS_sensorNoResponseRR : 27|1@1+ (1,0) [0|1] "" Vector__XXX
 SG_ TPMS_sensorThermShutdownFL : 28|1@1+ (1,0) [0|1] "" Vector__XXX
 SG_ TPMS_sensorThermShutdownFR : 29|1@1+ (1,0) [0|1] "" Vector__XXX
 SG_ TPMS_sensorThermShutdownRL : 30|1@1+ (1,0) [0|1] "" Vector__XXX
 SG_ TPMS_sensorThermShutdownRR : 31|1@1+ (1,0) [0|1] "" Vector__XXX
 SG_ TPMS_sensorBatteryLowFL : 32|1@1+ (1,0) [0|1] "" Vector__XXX
 SG_ TPMS_sensorBatteryLowFR : 33|1@1+ (1,0) [0|1] "" Vector__XXX
 SG_ TPMS_sensorBatteryLowRL : 34|1@1+ (1,0) [0|1] "" Vector__XXX
 SG_ TPMS_sensorBatteryLowRR : 35|1@1+ (1,0) [0|1] "" Vector__XXX
 SG_ TPMS_sensorDefectiveFL : 36|1@1+ (1,0) [0|1] "" Vector__XXX
 SG_ TPMS_sensorDefectiveFR : 37|1@1+ (1,0) [0|1] "" Vector__XXX
 SG_ TPMS_sensorDefectiveRL : 38|1@1+ (1,0) [0|1] "" Vector__XXX
 SG_ TPMS_sensorDefectiveRR : 39|1@1+ (1,0) [0|1] "" Vector__XXX
 SG_ TPMS_ecuUnderVoltage : 40|1@1+ (1,0) [0|1] "" Vector__XXX
 SG_ TPMS_ecuOverVoltage : 41|1@1+ (1,0) [0|1] "" Vector__XXX
 SG_ TPMS_ecuRamRomNvMFail : 42|1@1+ (1,0) [0|1] "" Vector__XXX
 SG_ TPMS_rfReceiverFail : 43|1@1+ (1,0) [0|1] "" Vector__XXX
 SG_ TPMS_wheelPulseMissing : 44|1@1+ (1,0) [0|1] "" Vector__XXX
 SG_ TPMS_vehicleSpeedFail : 45|1@1+ (1,0) [0|1] "" Vector__XXX
 SG_ TPMS_externalTemperatureFail : 46|1@1+ (1,0) [0|1] "" Vector__XXX
 SG_ TPMS_eolNotCompleted : 47|1@1+ (1,0) [0|1] "" Vector__XXX
 SG_ TPMS_rcpFront : 48|8@1+ (0.025,0) [0|6.375] "bar" Vector__XXX
 SG_ TPMS_rcpRear : 56|8@1+ (0.025,0) [0|6.375] "bar" Vector__XXX

BO_ 799 TPMS_data: 8 TPMS
 SG_ TPMS_pressureFL : 0|8@1+ (0.025,0) [0|6.35] "bar" Vector__XXX
 SG_ TPMS_temperatureFL : 8|8@1+ (1,-40) [-40|214] "degC" Vector__XXX
 SG_ TPMS_pressureFR : 16|8@1+ (0.025,0) [0|6.35] "bar" Vector__XXX
 SG_ TPMS_temperatureFR : 24|8@1+ (1,-40) [-40|214] "degC" Vector__XXX
 SG_ TPMS_pressureRL : 32|8@1+ (0.025,0) [0|6.35] "bar" Vector__XXX
 SG_ TPMS_temperatureRL : 40|8@1+ (1,-40) [-40|214] "degC" Vector__XXX
 SG_ TPMS_pressureRR : 48|8@1+ (0.025,0) [0|6.35] "bar" Vector__XXX
 SG_ TPMS_temperatureRR : 56|8@1+ (1,-40) [-40|214] "degC" Vector__XXX

BO_ 1519 TPMS_info: 8 TPMS
 SG_ TPMS_infoIndex M : 0|8@1+ (1,0) [0|255] "" Vector__XXX
 SG_ TPMS_infoComponentID m10 : 48|16@1+ (1,0) [0|65535] "" Vector__XXX
 SG_ TPMS_infoPcbaID m11 : 16|8@1+ (1,0) [0|255] "" Vector__XXX
 SG_ TPMS_infoAssemblyID m11 : 24|8@1+ (1,0) [0|255] "" Vector__XXX
 SG_ TPMS_infoUsageID m11 : 32|16@1+ (1,0) [0|65535] "" Vector__XXX
 SG_ TPMS_infoApplicationCRC m13 : 32|32@1+ (1,0) [0|4294967295] "" Vector__XXX
 SG_ TPMS_infoBootUdsProtoVersion m20 : 8|8@1+ (1,0) [0|255] "" Vector__XXX
 SG_ TPMS_infoBootloaderCRC m20 : 32|32@1+ (1,0) [0|4294967295] "" Vector__XXX

BO_ 850 TRCM_info: 8 TRCM
 SG_ TRCM_infoIndex M : 0|8@1+ (1,0) [0|255] "" Vector__XXX
 SG_ TRCM_infoBuildType m10 : 8|8@1+ (1,0) [0|255] "" Vector__XXX
 SG_ TRCM_infoBuildConfigId m10 : 16|16@1+ (1,0) [0|65535] "" Vector__XXX
 SG_ TRCM_infoHardwareId m10 : 32|16@1+ (1,0) [0|65535] "" Vector__XXX
 SG_ TRCM_infoComponentId m10 : 48|16@1+ (1,0) [0|65535] "" Vector__XXX
 SG_ TRCM_infoPcbaId m11 : 8|8@1+ (1,0) [0|255] "" Vector__XXX
 SG_ TRCM_infoAssemblyId m11 : 16|8@1+ (1,0) [0|254] "" Vector__XXX
 SG_ TRCM_infoUsageId m11 : 24|16@1+ (1,0) [0|65535] "" Vector__XXX
 SG_ TRCM_infoSubUsageId m11 : 40|16@1+ (1,0) [0|65535] "" Vector__XXX
 SG_ TRCM_infoAppCrc m13 : 8|32@1+ (1,0) [0|4294967295] "" Vector__XXX
 SG_ TRCM_infoAppGitHash m17 : 8|56@1+ (1,0) [0|7.20575940379e+16] "" Vector__XXX
 SG_ TRCM_infoBootGitHash m18 : 8|56@1+ (1,0) [0|7.20575940379e+16] "" Vector__XXX
 SG_ TRCM_infoBootUdsProtoVersion m20 : 8|8@1+ (1,0) [0|255] "" Vector__XXX
 SG_ TRCM_infoBootCrc m20 : 24|32@1+ (1,0) [0|4294967295] "" Vector__XXX

BO_ 1021 UI_autopilotControl: 8 GTW
 SG_ UI_autopilotControlIndex M : 0|3@1+ (1,0) [0|7] "" Vector__XXX
 SG_ UI_hovEnabled m0 : 3|1@1+ (1,0) [0|1] "" Vector__XXX
 SG_ UI_smartSetSpeedOffset m0 : 25|6@1+ (1,-30) [-30|33] "%" Vector__XXX
 SG_ UI_smartSetSpeedOffsetType m0 : 31|1@1+ (1,0) [0|1] "" Vector__XXX
 SG_ UI_fsdStopsControlEnabled m0 : 38|1@1+ (1,0) [0|1] "" Vector__XXX
 SG_ UI_smartSetSpeed m0 : 40|1@1+ (1,0) [0|1] "" Vector__XXX
 SG_ UI_automaticSetSpeedOffset m0 : 41|1@1+ (1,0) [0|1] "" Vector__XXX
 SG_ UI_enableFullSelfDriving m0 : 46|1@1+ (1,0) [0|1] "" Vector__XXX
 SG_ UI_hasFullSelfDriving m0 : 47|1@1+ (1,0) [0|1] "" Vector__XXX
 SG_ UI_autosteerActivation m0 : 48|1@1+ (1,0) [0|1] "" Vector__XXX
 SG_ UI_fsdBetaRequest m0 : 51|1@1+ (1,0) [0|1] "" Vector__XXX
 SG_ UI_fullSelfDrivingSuspended m0 : 52|1@1+ (1,0) [0|1] "" Vector__XXX
 SG_ UI_disableOptionalLaneChanges m0 : 53|1@1+ (1,0) [0|1] "" Vector__XXX
 SG_ UI_applyADDWWarnings m0 : 62|1@1+ (1,0) [0|1] "" Vector__XXX
 SG_ UI_selectableCameraRequest m1 : 8|4@1+ (1,0) [0|14] "" Vector__XXX
 SG_ UI_driverMonitorConfirmation m1 : 17|1@1+ (1,0) [0|1] "" Vector__XXX
 SG_ UI_parkAssistUseVision m1 : 18|1@1+ (1,0) [0|1] "" Vector__XXX
 SG_ UI_noStalkConfirmAlertHaptic m1 : 32|1@1+ (1,0) [0|1] "" Vector__XXX
 SG_ UI_noStalkConfirmAlertChime m1 : 37|1@1+ (1,0) [0|1] "" Vector__XXX
 SG_ UI_factorySummonEnable m1 : 39|1@1+ (1,0) [0|1] "" Vector__XXX
 SG_ UI_enableCabinCamera m1 : 43|1@1+ (1,0) [0|1] "" Vector__XXX
 SG_ UI_enableAutopilotStopWarning m1 : 44|1@1+ (1,0) [0|1] "" Vector__XXX
 SG_ UI_enableVisionSpeedControl m1 : 49|1@1+ (1,0) [0|1] "" Vector__XXX
 SG_ UI_enableTeslaAutopark m1 : 51|1@1+ (1,0) [0|1] "" Vector__XXX
 SG_ UI_autoTurnSignalMode m1 : 52|1@1+ (1,0) [0|1] "" Vector__XXX
 SG_ UI_enableCabinAudioRecording m1 : 59|1@1+ (1,0) [0|1] "" Vector__XXX
 SG_ UI_autopilotDrivingProfile m2 : 60|3@1+ (1,0) [0|7] "" Vector__XXX

BO_ 659 UI_chassisControl: 8 GTW
 SG_ UI_steeringTuneRequest : 0|2@1+ (1,0) [0|3] "" Vector__XXX
 SG_ UI_tractionControlMode : 2|3@1+ (1,0) [0|7] "" Vector__XXX
 SG_ UI_parkBrakeRequest : 5|2@1+ (1,0) [0|2] "" Vector__XXX
 SG_ UI_winchModeRequest : 8|2@1+ (1,0) [0|3] "" Vector__XXX
 SG_ UI_trailerMode : 12|1@1+ (1,0) [0|1] "" Vector__XXX
 SG_ UI_accOvertakeEnable : 16|2@1+ (1,0) [0|2] "" Vector__XXX
 SG_ UI_aebEnable : 18|2@1+ (1,0) [0|2] "" Vector__XXX
 SG_ UI_aesEnable : 20|2@1+ (1,0) [0|2] "" Vector__XXX
 SG_ UI_ahlbEnable : 22|2@1+ (1,0) [0|2] "" Vector__XXX
 SG_ UI_autoLaneChangeEnable : 24|2@1+ (1,0) [0|2] "" Vector__XXX
 SG_ UI_winchProxUserOverride : 26|1@1+ (1,0) [0|1] "" Vector__XXX
 SG_ UI_autoParkRequest : 28|4@1+ (1,0) [0|14] "" Vector__XXX
 SG_ UI_bsdEnable : 32|2@1+ (1,0) [0|2] "" Vector__XXX
 SG_ UI_fcwEnable : 34|2@1+ (1,0) [0|2] "" Vector__XXX
 SG_ UI_fcwSensitivity : 36|2@1+ (1,0) [0|2] "" Vector__XXX
 SG_ UI_latControlEnable : 38|2@1+ (1,0) [0|2] "" Vector__XXX
 SG_ UI_ldwEnable : 40|2@1+ (1,0) [0|2] "" Vector__XXX

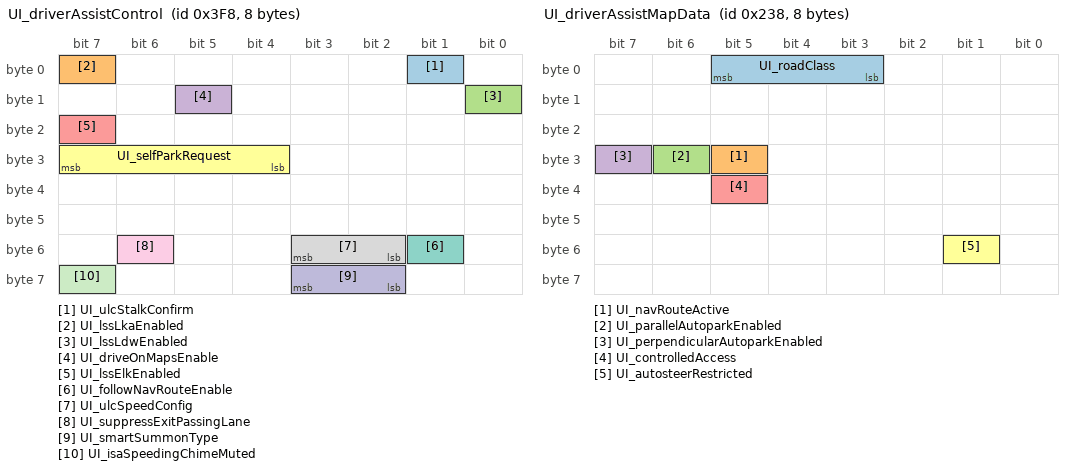
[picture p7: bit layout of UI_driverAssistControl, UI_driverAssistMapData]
BO_ 1016 UI_driverAssistControl: 8 GTW
 SG_ UI_ulcStalkConfirm : 1|1@1+ (1,0) [0|1] "" Vector__XXX
 SG_ UI_lssLkaEnabled : 7|1@1+ (1,0) [0|1] "" Vector__XXX
 SG_ UI_lssLdwEnabled : 8|1@1+ (1,0) [0|1] "" Vector__XXX
 SG_ UI_driveOnMapsEnable : 13|1@1+ (1,0) [0|1] "" Vector__XXX
 SG_ UI_lssElkEnabled : 23|1@1+ (1,0) [0|1] "" Vector__XXX
 SG_ UI_selfParkRequest : 28|4@1+ (1,0) [0|14] "" Vector__XXX
 SG_ UI_followNavRouteEnable : 49|1@1+ (1,0) [0|1] "" Vector__XXX
 SG_ UI_ulcSpeedConfig : 50|2@1+ (1,0) [0|3] "" Vector__XXX
 SG_ UI_suppressExitPassingLane : 54|1@1+ (1,0) [0|1] "" Vector__XXX
 SG_ UI_smartSummonType : 58|2@1+ (1,0) [0|3] "" Vector__XXX
 SG_ UI_isaSpeedingChimeMuted : 63|1@1+ (1,0) [0|1] "" Vector__XXX

BO_ 568 UI_driverAssistMapData: 8 GTW
 SG_ UI_roadClass : 3|3@1+ (1,0) [1|7] "" Vector__XXX
 SG_ UI_navRouteActive : 29|1@1+ (1,0) [0|1] "" Vector__XXX
 SG_ UI_parallelAutoparkEnabled : 30|1@1+ (1,0) [0|1] "" Vector__XXX
 SG_ UI_perpendicularAutoparkEnabled : 31|1@1+ (1,0) [0|1] "" Vector__XXX
 SG_ UI_controlledAccess : 37|1@1+ (1,0) [0|1] "" Vector__XXX
 SG_ UI_autosteerRestricted : 49|1@1+ (1,0) [0|1] "" Vector__XXX

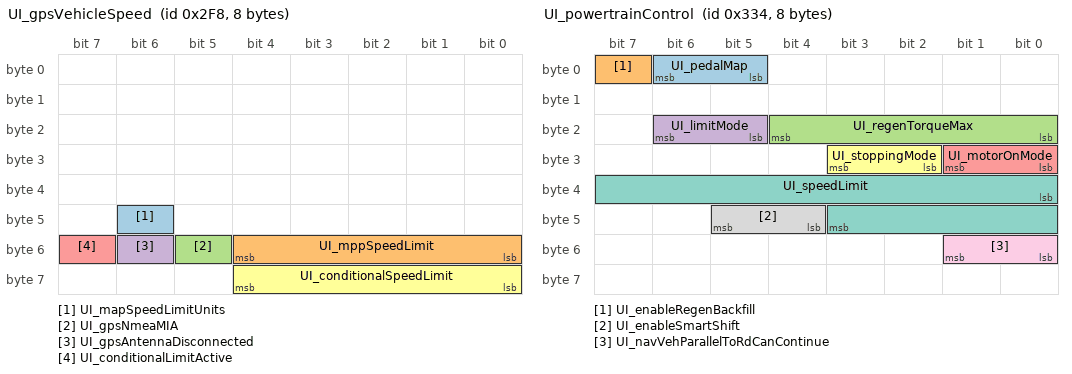
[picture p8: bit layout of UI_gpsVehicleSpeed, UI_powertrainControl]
BO_ 760 UI_gpsVehicleSpeed: 8 GTW
 SG_ UI_mapSpeedLimitUnits : 46|1@1+ (1,0) [0|1] "" Vector__XXX
 SG_ UI_mppSpeedLimit : 48|5@1+ (5,0) [0|155] "kph/mph" Vector__XXX
 SG_ UI_gpsNmeaMIA : 53|1@1+ (1,0) [0|1] "" Vector__XXX
 SG_ UI_gpsAntennaDisconnected : 54|1@1+ (1,0) [0|1] "" Vector__XXX
 SG_ UI_conditionalLimitActive : 55|1@1+ (1,0) [0|1] "" Vector__XXX
 SG_ UI_conditionalSpeedLimit : 56|5@1+ (5,0) [0|150] "kph/mph" Vector__XXX

BO_ 1011 UI_odo: 3 GTW
 SG_ UI_odometer : 0|24@1+ (0.1,0) [0|1677721.4] "km" Vector__XXX

BO_ 820 UI_powertrainControl: 8 GTW
 SG_ UI_pedalMap : 5|2@1+ (1,0) [0|3] "" Vector__XXX
 SG_ UI_enableRegenBackfill : 7|1@1+ (1,0) [0|1] "" Vector__XXX
 SG_ UI_regenTorqueMax : 16|5@1+ (5,0) [0|100] "%" Vector__XXX
 SG_ UI_limitMode : 21|2@1+ (1,0) [0|3] "" Vector__XXX
 SG_ UI_motorOnMode : 24|2@1+ (1,0) [0|3] "" Vector__XXX
 SG_ UI_stoppingMode : 26|2@1+ (1,0) [0|3] "" Vector__XXX
 SG_ UI_speedLimit : 32|12@1+ (0.1,0) [0|335] "kph" Vector__XXX
 SG_ UI_enableSmartShift : 44|2@1+ (1,0) [0|3] "" Vector__XXX
 SG_ UI_navVehParallelToRdCanContinue : 48|2@1+ (1,0) [1|3] "" Vector__XXX

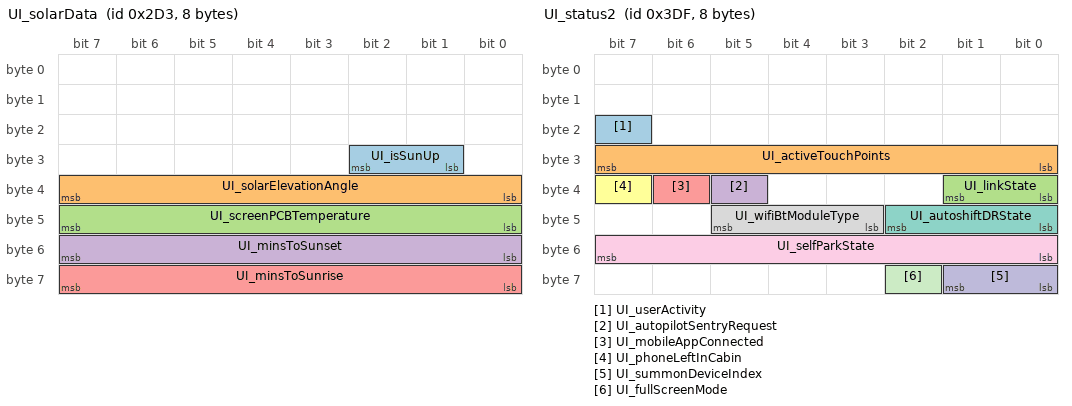
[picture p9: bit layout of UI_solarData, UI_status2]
BO_ 723 UI_solarData: 8 GTW
 SG_ UI_isSunUp : 25|2@1+ (1,0) [0|2] "" Vector__XXX
 SG_ UI_solarElevationAngle : 32|8@1- (1,0) [-128|126] "degrees" Vector__XXX
 SG_ UI_screenPCBTemperature : 40|8@1- (0.5,40) [-20|100] "degC" Vector__XXX
 SG_ UI_minsToSunset : 48|8@1+ (10,0) [0|2550] "min" Vector__XXX
 SG_ UI_minsToSunrise : 56|8@1+ (10,0) [0|2550] "min" Vector__XXX

BO_ 851 UI_status: 8 GTW
 SG_ UI_touchActive : 0|1@1+ (1,0) [0|1] "" Vector__XXX
 SG_ UI_audioActive : 1|1@1+ (1,0) [0|1] "" Vector__XXX
 SG_ UI_cellActive : 3|1@1+ (1,0) [0|1] "" Vector__XXX
 SG_ UI_displayReady : 4|1@1+ (1,0) [0|1] "" Vector__XXX
 SG_ UI_displayOn : 5|1@1+ (1,0) [0|1] "" Vector__XXX
 SG_ UI_wifiActive : 6|1@1+ (1,0) [0|1] "" Vector__XXX
 SG_ UI_wifiConnected : 7|1@1+ (1,0) [0|1] "" Vector__XXX
 SG_ UI_readyForDrive : 9|1@1+ (1,0) [0|1] "" Vector__XXX
 SG_ UI_cellConnected : 10|1@1+ (1,0) [0|1] "" Vector__XXX
 SG_ UI_vpnActive : 11|1@1+ (1,0) [0|1] "" Vector__XXX
 SG_ UI_factoryReset : 14|2@1+ (1,0) [1|3] "" Vector__XXX
 SG_ UI_gpsActive : 16|1@1+ (1,0) [0|1] "" Vector__XXX
 SG_ UI_cellNetworkTechnology : 19|4@1+ (1,0) [0|14] "" Vector__XXX
 SG_ UI_falseTouchCounter : 32|8@1+ (1,0) [0|255] "1" Vector__XXX
 SG_ UI_cellSignalBars : 42|3@1+ (1,0) [0|6] "" Vector__XXX
 SG_ UI_trailerModeTelltale : 45|2@1+ (1,0) [0|3] "" Vector__XXX
 SG_ UI_pcbTemperature : 48|8@1- (1,40) [-20|100] "degC" Vector__XXX
 SG_ UI_cpuTemperature : 56|8@1- (1,40) [-20|100] "degC" Vector__XXX

BO_ 991 UI_status2: 8 GTW
 SG_ UI_userActivity : 23|1@1+ (1,0) [0|1] "" Vector__XXX
 SG_ UI_activeTouchPoints : 24|8@1+ (1,0) [0|255] "1" Vector__XXX
 SG_ UI_linkState : 32|2@1+ (1,0) [0|3] "" Vector__XXX
 SG_ UI_autopilotSentryRequest : 37|1@1+ (1,0) [0|1] "" Vector__XXX
 SG_ UI_mobileAppConnected : 38|1@1+ (1,0) [0|1] "" Vector__XXX
 SG_ UI_phoneLeftInCabin : 39|1@1+ (1,0) [0|1] "" Vector__XXX
 SG_ UI_autoshiftDRState : 40|3@1+ (1,0) [0|7] "" Vector__XXX
 SG_ UI_wifiBtModuleType : 43|3@1+ (1,0) [0|7] "" Vector__XXX
 SG_ UI_selfParkState : 48|8@1+ (1,0) [0|254] "" Vector__XXX
 SG_ UI_summonDeviceIndex : 56|2@1+ (1,0) [0|3] "" Vector__XXX
 SG_ UI_fullScreenMode : 58|1@1+ (1,0) [0|1] "" Vector__XXX

BO_ 952 UI_tpmsRCPsetting: 4 GTW
 SG_ UI_sendCalibrateTireRequest : 7|1@1+ (1,0) [0|1] "" Vector__XXX

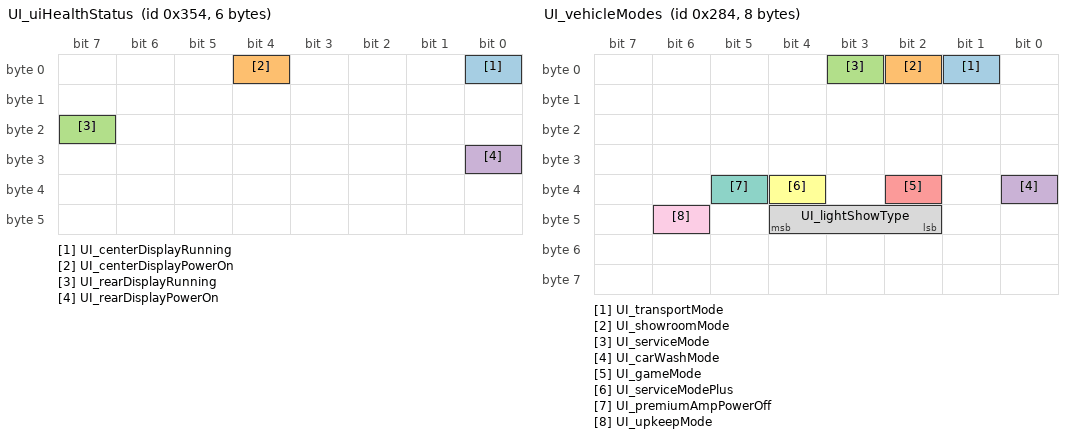
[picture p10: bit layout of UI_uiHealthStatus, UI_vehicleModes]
BO_ 852 UI_uiHealthStatus: 6 GTW
 SG_ UI_centerDisplayRunning : 0|1@1+ (1,0) [0|1] "" Vector__XXX
 SG_ UI_centerDisplayPowerOn : 4|1@1+ (1,0) [0|1] "" Vector__XXX
 SG_ UI_rearDisplayRunning : 23|1@1+ (1,0) [0|1] "" Vector__XXX
 SG_ UI_rearDisplayPowerOn : 24|1@1+ (1,0) [0|1] "" Vector__XXX

BO_ 947 UI_vehicleControl2: 8 GTW
 SG_ UI_gloveboxRequest : 0|1@1+ (1,0) [0|1] "" Vector__XXX
 SG_ UI_trunkRequest : 1|1@1+ (1,0) [0|1] "" Vector__XXX
 SG_ UI_PINToDriveEnabled : 6|1@1+ (1,0) [0|1] "" Vector__XXX
 SG_ UI_PINToDrivePassed : 7|1@1+ (1,0) [0|1] "" Vector__XXX
 SG_ UI_disableMirrorAutoDim : 8|1@1+ (1,0) [0|1] "" Vector__XXX
 SG_ UI_lightSwitch : 9|3@1+ (1,0) [0|7] "" Vector__XXX
 SG_ UI_readyToAddKey : 12|1@1+ (1,0) [0|1] "" Vector__XXX
 SG_ UI_alarmTriggerRequest : 13|1@1+ (1,0) [0|1] "" Vector__XXX
 SG_ UI_displayOnForUser : 18|1@1+ (1,0) [0|1] "" Vector__XXX
 SG_ UI_BLEPushNotificationRequest : 20|1@1+ (1,0) [0|1] "" Vector__XXX
 SG_ UI_keepAutopilotAwake : 22|1@1+ (1,0) [0|1] "" Vector__XXX
 SG_ UI_batteryPreconditioningRequest : 23|1@1+ (1,0) [0|1] "" Vector__XXX
 SG_ UI_autopilotPowerStateRequest : 25|2@1+ (1,0) [0|3] "" Vector__XXX
 SG_ UI_autoRollWindowsOnLockEnable : 29|1@1+ (1,0) [0|1] "" Vector__XXX
 SG_ UI_steeringWheelHeatReq : 33|1@1+ (1,0) [0|1] "" Vector__XXX
 SG_ UI_disableHorn : 34|1@1+ (1,0) [0|1] "" Vector__XXX
 SG_ UI_frontLeftSeatFanReq : 37|2@1+ (1,0) [0|3] "" Vector__XXX
 SG_ UI_frontRightSeatAutoClimateReq : 39|1@1+ (1,0) [0|1] "" Vector__XXX
 SG_ UI_frontRightSeatFanReq : 40|2@1+ (1,0) [0|3] "" Vector__XXX
 SG_ UI_frontLeftSeatAutoClimateReq : 56|1@1+ (1,0) [0|1] "" Vector__XXX
 SG_ UI_wiperHeaterReq : 57|1@1+ (1,0) [0|1] "" Vector__XXX
 SG_ UI_silentAlarm : 61|1@1+ (1,0) [0|1] "" Vector__XXX

BO_ 644 UI_vehicleModes: 8 GTW
 SG_ UI_transportMode : 1|1@1+ (1,0) [0|1] "" Vector__XXX
 SG_ UI_showroomMode : 2|1@1+ (1,0) [0|1] "" Vector__XXX
 SG_ UI_serviceMode : 3|1@1+ (1,0) [0|1] "" Vector__XXX
 SG_ UI_carWashMode : 32|1@1+ (1,0) [0|1] "" Vector__XXX
 SG_ UI_gameMode : 34|1@1+ (1,0) [0|1] "" Vector__XXX
 SG_ UI_serviceModePlus : 36|1@1+ (1,0) [0|1] "" Vector__XXX
 SG_ UI_premiumAmpPowerOff : 37|1@1+ (1,0) [0|1] "" Vector__XXX
 SG_ UI_lightShowType : 42|3@1+ (1,0) [0|7] "" Vector__XXX
 SG_ UI_upkeepMode : 46|1@1+ (1,0) [0|1] "" Vector__XXX

BO_ 807 USM_info: 8 USM
 SG_ USM_infoIndex M : 0|8@1+ (1,0) [0|255] "" Vector__XXX
 SG_ USM_infoBuildType m10 : 8|3@1+ (1,0) [0|7] "" Vector__XXX
 SG_ USM_infoBuildConfigId m10 : 16|16@1+ (1,0) [0|65535] "" Vector__XXX
 SG_ USM_infoHardwareId m10 : 32|16@1+ (1,0) [0|65535] "" Vector__XXX
 SG_ USM_infoComponentId m10 : 48|16@1+ (1,0) [0|65535] "" Vector__XXX
 SG_ USM_infoPcbaId m11 : 8|8@1+ (1,0) [0|255] "" Vector__XXX
 SG_ USM_infoAssemblyId m11 : 16|8@1+ (1,0) [0|254] "" Vector__XXX
 SG_ USM_infoUsageId m11 : 24|16@1+ (1,0) [0|65535] "" Vector__XXX
 SG_ USM_infoSubUsageId m11 : 40|16@1+ (1,0) [0|65535] "" Vector__XXX
 SG_ USM_infoAppCrc m13 : 8|32@1+ (1,0) [0|4294967295] "" Vector__XXX

BO_TX_BU_ 921 : DAS;
BO_TX_BU_ 905 : DAS;
BO_TX_BU_ 586 : DAS;
BO_TX_BU_ 977 : EPAS3S;
BO_TX_BU_ 785 : EPAS3S;
BO_TX_BU_ 880 : EPAS3S;
BO_TX_BU_ 805 : ESP;
BO_TX_BU_ 813 : IBST;
BO_TX_BU_ 806 : PARK;
BO_TX_BU_ 846 : PARK;
BO_TX_BU_ 926 : PARK;
BO_TX_BU_ 606 : PARK;
BO_TX_BU_ 542 : PARK;
BO_TX_BU_ 590 : PARK;
BO_TX_BU_ 526 : PARK;
BO_TX_BU_ 558 : PARK;
BO_TX_BU_ 814 : PARK;
BO_TX_BU_ 830 : PARK;
BO_TX_BU_ 798 : PARK;
BO_TX_BU_ 782 : PARK;
BO_TX_BU_ 1329 : RADC;
BO_TX_BU_ 257 : RCM;
BO_TX_BU_ 273 : RCM;
BO_TX_BU_ 849 : RCM;
BO_TX_BU_ 529 : RCM;
BO_TX_BU_ 879 : TPMS;
BO_TX_BU_ 799 : TPMS;
BO_TX_BU_ 1519 : TPMS;
BO_TX_BU_ 850 : TRCM;
BO_TX_BU_ 1021 : GTW;
BO_TX_BU_ 659 : GTW;
BO_TX_BU_ 1016 : GTW;
BO_TX_BU_ 568 : GTW;
BO_TX_BU_ 760 : GTW;
BO_TX_BU_ 1011 : GTW;
BO_TX_BU_ 820 : GTW;
BO_TX_BU_ 723 : GTW;
BO_TX_BU_ 851 : GTW;
BO_TX_BU_ 991 : GTW;
BO_TX_BU_ 952 : GTW;
BO_TX_BU_ 852 : GTW;
BO_TX_BU_ 947 : GTW;
BO_TX_BU_ 644 : GTW;
BO_TX_BU_ 807 : USM;
CM_ BO_ 921 "Driver assistance computer message: status";
CM_ SG_ 921 DAS_autopilotState "Reports the high level autopilot state.; raw 15 = signal not available (SNA)";
CM_ SG_ 921 DAS_blindSpotRearLeft "Reports rear left blind spot warning level.; raw 3 = signal not available (SNA)";
CM_ SG_ 921 DAS_blindSpotRearRight "Reports rear right blind spot warning level.; raw 3 = signal not available (SNA)";
CM_ SG_ 921 DAS_fusedSpeedLimit "Driver assistance computer: fused speed limit; raw 0 = signal not available (SNA)";
CM_ SG_ 921 DAS_suppressSpeedWarning "Driver assistance computer: suppress speed warning";
CM_ SG_ 921 DAS_summonObstacle "Driver assistance computer: summon obstacle";
CM_ SG_ 921 DAS_summonClearedGate "Driver assistance computer: summon cleared gate";
CM_ SG_ 921 DAS_visionOnlySpeedLimit "Driver assistance computer: vision only speed limit; raw 0 = signal not available (SNA)";
CM_ SG_ 921 DAS_heaterState "The state of the app which runs the front glass heater.; raw 0 = signal not available (SNA)";
CM_ SG_ 921 DAS_forwardCollisionWarning "Driver assistance computer: forward collision warning; raw 3 = signal not available (SNA)";
CM_ SG_ 921 DAS_autoparkReady "Indicates if all the conditions for Autopark are met.";
CM_ SG_ 921 DAS_autoParked "Driver assistance computer: auto parked";
CM_ SG_ 921 DAS_autoparkActive "Reports whether Autopark is currently active.";
CM_ SG_ 921 DAS_summonFwdLeashReached "Driver assistance computer: summon fwd leash reached";
CM_ SG_ 921 DAS_summonRvsLeashReached "Driver assistance computer: summon rvs leash reached";
CM_ SG_ 921 DAS_lssState "Tracks lane support system state and whether it is controlling steering angle requests for LKA / ELKA.";
CM_ SG_ 921 DAS_sideCollisionAvoid "Reports if the side collision avoidance function is active on the left or right.; raw 3 = signal not available (SNA)";
CM_ SG_ 921 DAS_sideCollisionWarning "Reports if the side collision warning function is active in the left or right.";
CM_ SG_ 921 DAS_sideCollisionInhibit "Driver assistance computer: side collision inhibit";
CM_ SG_ 921 DAS_laneDepartureWarning "Driver assistance computer: lane departure warning; raw 5 = signal not available (SNA)";
CM_ SG_ 921 DAS_fleetSpeedState "The state of the fleet speed algorithm.";
CM_ SG_ 921 DAS_autopilotHandsOnState "Reports the state of the hands on state machine.; raw 15 = signal not available (SNA)";
CM_ SG_ 921 DAS_autoLaneChangeState "Reports the legacy Automatic Lane Change (ALC) state used to drive the instrument cluster User Interface (UI).; raw 31 = signal not available (SNA)";
CM_ SG_ 921 DAS_summonAvailable "Driver assistance computer: summon available";
CM_ SG_ 921 DAS_statusCounter "Driver assistance computer: status counter";
CM_ SG_ 921 DAS_statusChecksum "Driver assistance computer: status checksum";
CM_ BO_ 905 "Driver assistance computer message: status2";
CM_ SG_ 905 DAS_accSpeedLimit "Reports the Adaptive Cruise Control (ACC) speed limit, which is derived from speed limits embedded in maps.; raw 511 = signal not available (SNA)";
CM_ SG_ 905 DAS_versionIdentifier "Driver assistance computer: version identifier";
CM_ SG_ 905 DAS_pmmObstacleSeverity "Detects the output of the Pedal Misapplication Mitigation (PMM) function, which limits torque or applies the brake.; raw 7 = signal not available (SNA)";
CM_ SG_ 905 DAS_pmmLoggingRequest "Driver assistance computer: pmm logging request";
CM_ SG_ 905 DAS_activationFailureStatus "Driver assistance computer: activation failure status";
CM_ SG_ 905 DAS_pmmUltrasonicsFaultReason "Reports if there is a reason Pedal Misapplication Mitigation (PMM) is disabled due to a condition with the ultrasonics.";
CM_ SG_ 905 DAS_pmmRadarFaultReason "Reports if there is a reason Pedal Misapplication Mitigation (PMM) is disabled due to a radar issue.";
CM_ SG_ 905 DAS_pmmSysFaultReason "Reports if there is a reason Pedal Misapplication Mitigation (PMM) is disabled due to a system malfunction.";
CM_ SG_ 905 DAS_pmmCameraFaultReason "Reports if there is a reason Pedal Misapplication Mitigation (PMM) is disabled due to camera issues.";
CM_ SG_ 905 DAS_ACC_report "Indicates what control target Traffic-Aware Cruise Control (TACC) is controlling for. Only relevant during TACC (not Autosteer).";
CM_ SG_ 905 DAS_relaxCruiseLimits "Indicates whether DI should relax accel limits";
CM_ SG_ 905 DAS_csaState "Reports the state of the curve speed adaption algorithm.";
CM_ SG_ 905 DAS_radarTelemetry "Driver assistance computer: radar telemetry";
CM_ SG_ 905 DAS_robState "Driver assistance computer: rob state";
CM_ SG_ 905 DAS_driverInteractionLevel "Driver assistance computer: driver interaction level";
CM_ SG_ 905 DAS_ppOffsetDesiredRamp "Driver assistance computer: pp offset desired ramp";
CM_ SG_ 905 DAS_longCollisionWarning "Driver assistance computer: long collision warning; raw 15 = signal not available (SNA)";
CM_ SG_ 905 DAS_status2Counter "Driver assistance computer: status2 counter";
CM_ SG_ 905 DAS_status2Checksum "Driver assistance computer: status2 checksum";
CM_ BO_ 586 "Driver assistance computer message: visual debug";
CM_ SG_ 586 DAS_autosteerVehiclesUsage "Driver assistance computer: autosteer vehicles usage";
CM_ SG_ 586 DAS_autosteerHPPUsage "Driver assistance computer: autosteer HPP usage";
CM_ SG_ 586 DAS_autosteerNavigationUsage "Driver assistance computer: autosteer navigation usage";
CM_ SG_ 586 DAS_autosteerModelUsage "Driver assistance computer: autosteer model usage";
CM_ SG_ 586 DAS_autosteerBottsDotsUsage "Driver assistance computer: autosteer botts dots usage";
CM_ SG_ 586 DAS_offsetSide "Driver assistance computer: offset side";
CM_ SG_ 586 DAS_roadSurfaceType "Driver assistance computer: road surface type; raw 0 = signal not available (SNA)";
CM_ SG_ 586 DAS_autosteerHealthAnomalyLevel "Driver assistance computer: autosteer health anomaly level";
CM_ SG_ 586 DAS_autosteerHealthState "Driver assistance computer: autosteer health state";
CM_ SG_ 586 DAS_lastLinePreferenceReason "Driver assistance computer: last line preference reason";
CM_ SG_ 586 DAS_plannerState "Driver assistance computer: planner state";
CM_ SG_ 586 DAS_lastAutosteerAbortReason "Driver assistance computer: last autosteer abort reason";
CM_ SG_ 586 DAS_devAppInterfaceEnabled "Driver assistance computer: dev app interface enabled";
CM_ SG_ 586 DAS_navAvailable "Driver assistance computer: nav available";
CM_ SG_ 586 DAS_navDistance "Driver assistance computer: nav distance";
CM_ SG_ 586 DAS_accSmartSpeedActive "Driver assistance computer: acc smart speed active";
CM_ SG_ 586 DAS_accSmartSpeedState "Driver assistance computer: acc smart speed state; raw 7 = signal not available (SNA)";
CM_ SG_ 586 DAS_ulcInProgress "Reports active lane changes that were not commanded.";
CM_ SG_ 586 DAS_trafficAwareSetSpeedInUse "Indicates that autopilot is using cruise set speed based on flow of traffic";
CM_ SG_ 586 DAS_isaSystemState "ISA system state";
CM_ SG_ 586 DAS_behaviorType "Driver assistance computer: behavior type";
CM_ SG_ 586 DAS_ulcType "Reports the underlying reason for the uncommanded lane change, whether for speed or route.";
CM_ SG_ 586 DAS_rearVehDetectedThisCycle "Driver assistance computer: rear veh detected this cycle";
CM_ SG_ 586 DAS_rearLeftVehDetectedCurrent "Driver assistance computer: rear left veh detected current";
CM_ SG_ 586 DAS_rearRightVehDetectedTrip "Driver assistance computer: rear right veh detected trip";
CM_ SG_ 586 DAS_rearLeftVehDetectedTrip "Driver assistance computer: rear left veh detected trip";
CM_ BO_ 977 "Electric power steering (secondary) message: angle calibration";
CM_ SG_ 977 EPAS3S_appliedAngleOffset "This represents the angle delta between the absolute steering angle reference and what EPAS estimates to be straight ahead. The steering angle offset can change up to 5deg at the beginning of each drive cycle.";
CM_ SG_ 977 EPAS3S_calculatedAngleOffset "Reports the calculated steering angle offset learned between the Steering Column Control Module (SCCM) and the Electronic Power Assist Steering (EPAS) steering angle.";
CM_ SG_ 977 EPAS3S_resyncStatus "Electric power steering (secondary): resync status";
CM_ SG_ 977 EPAS3S_pullDriftLongTermTrq "The learned, long term pull drift or road crown compensation torque that the rack is applying to the steering wheel.";
CM_ SG_ 977 EPAS3S_pullDriftCompTrq "The current pull drift or road crown compensation torque that the rack is applying to the steering wheel.";
CM_ SG_ 977 EPAS3S_learnedSCCMOffset "Electric power steering (secondary): learned SCCM offset";
CM_ BO_ 785 "Electric power steering (secondary) message: info";
CM_ SG_ 785 EPAS3S_infoIndex "Electric power steering (secondary): info index";
CM_ SG_ 785 EPAS3S_infoBuildType "Electric power steering (secondary): info build type";
CM_ SG_ 785 EPAS3S_infoComponentID "Electric power steering (secondary): info component ID";
CM_ SG_ 785 EPAS3S_infoPcbaID "Electric power steering (secondary): info pcba ID";
CM_ SG_ 785 EPAS3S_infoAssemblyID "Electric power steering (secondary): info assembly ID";
CM_ SG_ 785 EPAS3S_infoUsageID "Electric power steering (secondary): info usage ID";
CM_ SG_ 785 EPAS3S_infoApplicationCRC "Electric power steering (secondary): info application CRC";
CM_ SG_ 785 EPAS3S_infoBootUdsProtoVersion "Electric power steering (secondary): info boot uds proto version";
CM_ SG_ 785 EPAS3S_infoBootloaderCRC "Electric power steering (secondary): info bootloader CRC";
CM_ SG_ 785 EPAS3S_infoSubcomponent2 "Electric power steering (secondary): info subcomponent2";
CM_ BO_ 880 "Electric power steering (secondary) message: sys status";
CM_ SG_ 880 EPAS3S_steeringRackForce "The real time, estimated force applied by the steering rack to the tie rods.; raw 1023 = signal not available (SNA)";
CM_ SG_ 880 EPAS3S_steeringFault "Electric power steering (secondary): steering fault";
CM_ SG_ 880 EPAS3S_steeringReduced "Electric power steering (secondary): steering reduced";
CM_ SG_ 880 EPAS3S_internalSASQF "This signal identifies the validity of the EPAS3P_internalSAS signal.";
CM_ SG_ 880 EPAS3S_currentTuneMode "Electric power steering (secondary): current tune mode";
CM_ SG_ 880 EPAS3S_torsionBarTorque "The measurement of the steering wheel torque input. If the value is positive the steering wheel torque is applied in the clockwise direction.; raw 4095 = signal not available (SNA)";
CM_ SG_ 880 EPAS3S_eacErrorCode "Electric power steering (secondary): eac error code; raw 15 = signal not available (SNA)";
CM_ SG_ 880 EPAS3S_internalSAS "The measurement of the steering wheel angle that is calculated by electronic power steering assist steering. Clockwise positive.";
CM_ SG_ 880 EPAS3S_handsOnLevel "Electric power steering (secondary): hands on level";
CM_ SG_ 880 EPAS3S_sysStatusCounter "Electric power steering (secondary): sys status counter";
CM_ SG_ 880 EPAS3S_driverlessState "Electric power steering (secondary): driverless state";
CM_ SG_ 880 EPAS3S_eacStatus "Electric power steering (secondary): eac status";
CM_ SG_ 880 EPAS3S_sysStatusChecksum "Electric power steering (secondary): sys status checksum";
CM_ BO_ 805 "Electronic stability control message: info";
CM_ SG_ 805 ESP_infoIndex "Electronic stability control: info index";
CM_ SG_ 805 ESP_infoBuildType "Electronic stability control: info build type";
CM_ SG_ 805 ESP_infoComponentID "Electronic stability control: info component ID";
CM_ SG_ 805 ESP_infoPcbaID "Electronic stability control: info pcba ID";
CM_ SG_ 805 ESP_infoAssemblyID "Electronic stability control: info assembly ID";
CM_ SG_ 805 ESP_infoUsageID "Electronic stability control: info usage ID";
CM_ SG_ 805 ESP_infoSubUsageID "Electronic stability control: info sub usage ID";
CM_ SG_ 805 ESP_infoApplicationCRC "Indicating the Application CRC value of firmware running in system.";
CM_ SG_ 805 ESP_infoVehicleVariant "Electronic stability control: info vehicle variant";
CM_ SG_ 805 ESP_infoSubcomponent1 "Electronic stability control: info subcomponent1";
CM_ SG_ 805 ESP_infoBootUdsProtoVersion "Electronic stability control: info boot uds proto version";
CM_ SG_ 805 ESP_infoBootloaderCRC "Electronic stability control: info bootloader CRC";
CM_ SG_ 805 ESP_infoVariantCRC "Indicating the Calibration CRC value of firmware running in system.";
CM_ BO_ 813 "Electric brake booster message: info";
CM_ SG_ 813 IBST_infoIndex "Electric brake booster: info index";
CM_ SG_ 813 IBST_infoBuildType "Electric brake booster: info build type";
CM_ SG_ 813 IBST_infoComponentID "Electric brake booster: info component ID";
CM_ SG_ 813 IBST_infoPcbaID "Electric brake booster: info pcba ID";
CM_ SG_ 813 IBST_infoAssemblyID "Electric brake booster: info assembly ID";
CM_ SG_ 813 IBST_infoUsageID "Electric brake booster: info usage ID";
CM_ SG_ 813 IBST_infoSubUsageID "Electric brake booster: info sub usage ID";
CM_ SG_ 813 IBST_infoApplicationCRC "Indicating the Application CRC value of firmware running in system.";
CM_ SG_ 813 IBST_infoBootUdsProtoVersion "Electric brake booster: info boot uds proto version";
CM_ SG_ 813 IBST_infoBootloaderCRC "Electric brake booster: info bootloader CRC";
CM_ SG_ 813 IBST_infoVariantCRC "Indicating the Calibration CRC value of firmware running in system.";
CM_ BO_ 806 "Parking assist sensors message: info";
CM_ SG_ 806 PARK_infoIndex "Parking assist sensors: info index";
CM_ SG_ 806 PARK_infoBuildType "Parking assist sensors: info build type";
CM_ SG_ 806 PARK_infoComponentID "Parking assist sensors: info component ID";
CM_ SG_ 806 PARK_infoPcbaID "Parking assist sensors: info pcba ID";
CM_ SG_ 806 PARK_infoAssemblyID "Parking assist sensors: info assembly ID";
CM_ SG_ 806 PARK_infoUsageID "Parking assist sensors: info usage ID";
CM_ SG_ 806 PARK_infoApplicationCRC "Parking assist sensors: info application CRC";
CM_ SG_ 806 PARK_infoBootUdsProtoVersion "Parking assist sensors: info boot uds proto version";
CM_ SG_ 806 PARK_infoBootloaderCRC "Parking assist sensors: info bootloader CRC";
CM_ BO_ 846 "Parking assist sensors message: pas front middle";
CM_ SG_ 846 PARK_frontLeftMiddleRawDistData "Zone defined as -38 degrees -> +12 degrees, distance to object in units of centimeters.; raw 255 = signal not available (SNA)";
CM_ SG_ 846 PARK_frontMiddleRawDistData "Zone defined as -12 degrees to +12 degrees, distance to object in units of centimeters.; raw 255 = signal not available (SNA)";
CM_ SG_ 846 PARK_frontRightMiddleRawDistData "Zone defined +12 degrees to +38 degreees, distance to object in units of centimeters.; raw 255 = signal not available (SNA)";
CM_ SG_ 846 PARK_pasFrontMiddleCounter "Parking assist sensors: pas front middle counter";
CM_ SG_ 846 PARK_pasFrontMiddleChecksum "Parking assist sensors: pas front middle checksum";
CM_ BO_ 926 "Parking assist sensors message: pas sides";
CM_ SG_ 926 PARK_rightSideFrontRawDistData "Right side (from inside the car) towards the front of the car (split evenly between axles).; raw 255 = signal not available (SNA)";
CM_ SG_ 926 PARK_rightSideRearRawDistData "Right side (from inside the car) towards the rear of the car (split evenly between axles).; raw 255 = signal not available (SNA)";
CM_ SG_ 926 PARK_leftSideFrontRawDistData "Left side (from inside the car) towards the front of the car (split evenly between axles).; raw 255 = signal not available (SNA)";
CM_ SG_ 926 PARK_leftSideRearRawDistData "Left side (from inside the car) towards the rear of the car (split evenly between axles).; raw 255 = signal not available (SNA)";
CM_ SG_ 926 PARK_pasSidesCounter "Parking assist sensors: pas sides counter";
CM_ SG_ 926 PARK_pasSidesChecksum "Parking assist sensors: pas sides checksum";
CM_ BO_ 606 "Parking assist sensors message: psc env slot";
CM_ SG_ 606 PARK_pscEnvSlotType "Parking assist sensors: psc env slot type";
CM_ SG_ 606 PARK_pscLeftParallelObj1X "Parking assist sensors: psc left parallel obj1 x; raw 2047 = signal not available (SNA)";
CM_ SG_ 606 PARK_pscLeftParallelObj1Y "Parking assist sensors: psc left parallel obj1 y; raw 2047 = signal not available (SNA)";
CM_ SG_ 606 PARK_pscLeftParallelObj1Alpha "Parking assist sensors: psc left parallel obj1 alpha; raw 127 = signal not available (SNA)";
CM_ SG_ 606 PARK_pscLeftParallelObj2Y "Parking assist sensors: psc left parallel obj2 y; raw 2047 = signal not available (SNA)";
CM_ SG_ 606 PARK_pscLeftParallelObj2X "Parking assist sensors: psc left parallel obj2 x; raw 2047 = signal not available (SNA)";
CM_ SG_ 606 PARK_pscLeftParallelObj2Alpha "Parking assist sensors: psc left parallel obj2 alpha; raw 127 = signal not available (SNA)";
CM_ SG_ 606 PARK_pscLeftCrossObj1X "Parking assist sensors: psc left cross obj1 x; raw 2047 = signal not available (SNA)";
CM_ SG_ 606 PARK_pscLeftCrossObj1Y "Parking assist sensors: psc left cross obj1 y; raw 2047 = signal not available (SNA)";
CM_ SG_ 606 PARK_pscLeftCrossObj1Alpha "Parking assist sensors: psc left cross obj1 alpha; raw 127 = signal not available (SNA)";
CM_ SG_ 606 PARK_pscLeftCrossObj2Y "Parking assist sensors: psc left cross obj2 y; raw 2047 = signal not available (SNA)";
CM_ SG_ 606 PARK_pscLeftCrossObj2X "Parking assist sensors: psc left cross obj2 x; raw 2047 = signal not available (SNA)";
CM_ SG_ 606 PARK_pscLeftCrossObj2Alpha "Parking assist sensors: psc left cross obj2 alpha; raw 127 = signal not available (SNA)";
CM_ SG_ 606 PARK_pscRightParallelObj1X "Parking assist sensors: psc right parallel obj1 x; raw 2047 = signal not available (SNA)";
CM_ SG_ 606 PARK_pscRightParallelObj1Y "Parking assist sensors: psc right parallel obj1 y; raw 2047 = signal not available (SNA)";
CM_ SG_ 606 PARK_pscRightParallelObj1Alpha "Parking assist sensors: psc right parallel obj1 alpha; raw 127 = signal not available (SNA)";
CM_ SG_ 606 PARK_pscRightParallelObj2Y "Parking assist sensors: psc right parallel obj2 y; raw 2047 = signal not available (SNA)";
CM_ SG_ 606 PARK_pscRightParallelObj2X "Parking assist sensors: psc right parallel obj2 x; raw 2047 = signal not available (SNA)";
CM_ SG_ 606 PARK_pscRightParallelObj2Alpha "Parking assist sensors: psc right parallel obj2 alpha; raw 127 = signal not available (SNA)";
CM_ SG_ 606 PARK_pscRightCrossObj1X "Parking assist sensors: psc right cross obj1 x; raw 2047 = signal not available (SNA)";
CM_ SG_ 606 PARK_pscRightCrossObj1Y "Parking assist sensors: psc right cross obj1 y; raw 2047 = signal not available (SNA)";
CM_ SG_ 606 PARK_pscRightCrossObj1Alpha "Parking assist sensors: psc right cross obj1 alpha; raw 127 = signal not available (SNA)";
CM_ SG_ 606 PARK_pscRightCrossObj2Y "Parking assist sensors: psc right cross obj2 y; raw 2047 = signal not available (SNA)";
CM_ SG_ 606 PARK_pscRightCrossObj2X "Parking assist sensors: psc right cross obj2 x; raw 2047 = signal not available (SNA)";
CM_ SG_ 606 PARK_pscRightCrossObj2Alpha "Parking assist sensors: psc right cross obj2 alpha; raw 127 = signal not available (SNA)";
CM_ BO_ 542 "Parking assist sensors message: psc status";
CM_ SG_ 542 PARK_pscParkStatus "Parking assist sensors: psc park status; raw 7 = signal not available (SNA)";
CM_ SG_ 542 PARK_pscParkAbortReason "Parking assist sensors: psc park abort reason; raw 31 = signal not available (SNA)";
CM_ SG_ 542 PARK_pscParallelSpace "The existence and type of a parallel parking slot identified by the ultrasonics.";
CM_ SG_ 542 PARK_pscCrossSpace "The type and existence of perpendicular parking slot identified through the ultrasonics";
CM_ SG_ 542 PARK_pscParallelRightParkable "Whether or not there is a valid path into a parallel parking slot on the right.; raw 3 = signal not available (SNA)";
CM_ SG_ 542 PARK_pscParallelLeftParkable "Whether or not there is a valid path into a parallel parking slot on the left.; raw 3 = signal not available (SNA)";
CM_ SG_ 542 PARK_pscCrossRightParkable "Parking assist sensors: psc cross right parkable; raw 3 = signal not available (SNA)";
CM_ SG_ 542 PARK_pscMaxVelocity "Parking assist sensors: psc max velocity; raw 63 = signal not available (SNA)";
CM_ SG_ 542 PARK_pscCrossLeftParkable "Parking assist sensors: psc cross left parkable; raw 3 = signal not available (SNA)";
CM_ SG_ 542 PARK_pscParkInstruction "The control request from PARK ECU during autopark manuever.; raw 7 = signal not available (SNA)";
CM_ SG_ 542 PARK_pscManeuverDistance "Real time updated path length from center of vehicle reference frame to desired center of vehicle at end of current parking manuever.; raw 2047 = signal not available (SNA)";
CM_ SG_ 542 PARK_pscAngleActive "Parking assist sensors: psc angle active";
CM_ SG_ 542 PARK_pscAngleRequest "Parking assist sensors: psc angle request";
CM_ SG_ 542 PARK_pscStatusCounter "Parking assist sensors: psc status counter";
CM_ SG_ 542 PARK_pscStatusChecksum "Parking assist sensors: psc status checksum";
CM_ BO_ 590 "Parking assist sensors message: psc veh slot";
CM_ SG_ 590 PARK_pscVehSlotType "Parking assist sensors: psc veh slot type";
CM_ SG_ 590 PARK_pscLeftParallelVehX "Parking assist sensors: psc left parallel veh x; raw 2047 = signal not available (SNA)";
CM_ SG_ 590 PARK_pscLeftParallelVehY "Parking assist sensors: psc left parallel veh y; raw 2047 = signal not available (SNA)";
CM_ SG_ 590 PARK_pscLeftParallelPsi "Parking assist sensors: psc left parallel psi; raw 8191 = signal not available (SNA)";
CM_ SG_ 590 PARK_pscLeftParallelSizeX "Parking assist sensors: psc left parallel size x; raw 255 = signal not available (SNA)";
CM_ SG_ 590 PARK_pscLeftParallelSizeY "Parking assist sensors: psc left parallel size y; raw 255 = signal not available (SNA)";
CM_ SG_ 590 PARK_pscLeftCrossVehX "Parking assist sensors: psc left cross veh x; raw 2047 = signal not available (SNA)";
CM_ SG_ 590 PARK_pscLeftCrossVehY "Parking assist sensors: psc left cross veh y; raw 2047 = signal not available (SNA)";
CM_ SG_ 590 PARK_pscLeftCrossPsi "Parking assist sensors: psc left cross psi; raw 8191 = signal not available (SNA)";
CM_ SG_ 590 PARK_pscLeftCrossSizeX "Parking assist sensors: psc left cross size x; raw 255 = signal not available (SNA)";
CM_ SG_ 590 PARK_pscLeftCrossSizeY "Parking assist sensors: psc left cross size y; raw 255 = signal not available (SNA)";
CM_ SG_ 590 PARK_pscRightParallelVehX "Parking assist sensors: psc right parallel veh x; raw 2047 = signal not available (SNA)";
CM_ SG_ 590 PARK_pscRightParallelVehY "Parking assist sensors: psc right parallel veh y; raw 2047 = signal not available (SNA)";
CM_ SG_ 590 PARK_pscRightParallelPsi "Parking assist sensors: psc right parallel psi; raw 8191 = signal not available (SNA)";
CM_ SG_ 590 PARK_pscRightParallelSizeX "Parking assist sensors: psc right parallel size x; raw 255 = signal not available (SNA)";
CM_ SG_ 590 PARK_pscRightParallelSizeY "Parking assist sensors: psc right parallel size y; raw 255 = signal not available (SNA)";
CM_ SG_ 590 PARK_pscRightCrossVehX "Parking assist sensors: psc right cross veh x; raw 2047 = signal not available (SNA)";
CM_ SG_ 590 PARK_pscRightCrossVehY "Parking assist sensors: psc right cross veh y; raw 2047 = signal not available (SNA)";
CM_ SG_ 590 PARK_pscRightCrossPsi "Parking assist sensors: psc right cross psi; raw 8191 = signal not available (SNA)";
CM_ SG_ 590 PARK_pscRightCrossSizeX "Parking assist sensors: psc right cross size x; raw 255 = signal not available (SNA)";
CM_ SG_ 590 PARK_pscRightCrossSizeY "Parking assist sensors: psc right cross size y; raw 255 = signal not available (SNA)";
CM_ BO_ 526 "Parking assist sensors message: sdi front";
CM_ SG_ 526 PARK_sdiSensor1RawDistData "Parking assist sensors: sdi sensor1 raw dist data; raw 511 = signal not available (SNA)";
CM_ SG_ 526 PARK_sdiSensor2RawDistData "Parking assist sensors: sdi sensor2 raw dist data; raw 511 = signal not available (SNA)";
CM_ SG_ 526 PARK_sdiSensor3RawDistData "Parking assist sensors: sdi sensor3 raw dist data; raw 511 = signal not available (SNA)";
CM_ SG_ 526 PARK_sdiSensor4RawDistData "Parking assist sensors: sdi sensor4 raw dist data; raw 511 = signal not available (SNA)";
CM_ SG_ 526 PARK_sdiSensor5RawDistData "Parking assist sensors: sdi sensor5 raw dist data; raw 511 = signal not available (SNA)";
CM_ SG_ 526 PARK_sdiSensor6RawDistData "Parking assist sensors: sdi sensor6 raw dist data; raw 511 = signal not available (SNA)";
CM_ SG_ 526 PARK_sdiFrontCounter "Parking assist sensors: sdi front counter";
CM_ SG_ 526 PARK_sdiFrontChecksum "Parking assist sensors: sdi front checksum";
CM_ BO_ 558 "Parking assist sensors message: sdi rear";
CM_ SG_ 558 PARK_sdiSensor7RawDistData "Parking assist sensors: sdi sensor7 raw dist data; raw 511 = signal not available (SNA)";
CM_ SG_ 558 PARK_sdiSensor8RawDistData "Parking assist sensors: sdi sensor8 raw dist data; raw 511 = signal not available (SNA)";
CM_ SG_ 558 PARK_sdiSensor9RawDistData "Parking assist sensors: sdi sensor9 raw dist data; raw 511 = signal not available (SNA)";
CM_ SG_ 558 PARK_sdiSensor10RawDistData "Parking assist sensors: sdi sensor10 raw dist data; raw 511 = signal not available (SNA)";
CM_ SG_ 558 PARK_sdiSensor11RawDistData "Parking assist sensors: sdi sensor11 raw dist data; raw 511 = signal not available (SNA)";
CM_ SG_ 558 PARK_sdiSensor12RawDistData "Parking assist sensors: sdi sensor12 raw dist data; raw 511 = signal not available (SNA)";
CM_ SG_ 558 PARK_sdiRearCounter "Parking assist sensors: sdi rear counter";
CM_ SG_ 558 PARK_sdiRearChecksum "Parking assist sensors: sdi rear checksum";
CM_ BO_ 814 "Parking assist sensors message: sensor status front";
CM_ SG_ 814 PARK_frontRightSensorState "Reports the state of the front right ultrasonic sensor.; raw 3 = signal not available (SNA)";
CM_ SG_ 814 PARK_frontRightMiddleSensorState "Reports the state of the front right middle ultrasonic sensor.; raw 3 = signal not available (SNA)";
CM_ SG_ 814 PARK_frontLeftMiddleSensorState "Reports the state of the front left middle ultrasonic sensor.; raw 3 = signal not available (SNA)";
CM_ SG_ 814 PARK_frontLeftSensorState "Reports the state of the front left ultrasonic sensor.; raw 3 = signal not available (SNA)";
CM_ SG_ 814 PARK_frontLeftRawDistData "Zone defined as -90 degrees -> -38 degrees, distance to object in units of centimeters.; raw 255 = signal not available (SNA)";
CM_ SG_ 814 PARK_frontRightRawDistData "Zone defined as +38 degrees -> +90 degrees, distance to object in units of centimeters.; raw 255 = signal not available (SNA)";
CM_ SG_ 814 PARK_systemStatusFront "Parking assist sensors: system status front; raw 3 = signal not available (SNA)";
CM_ SG_ 814 PARK_frontDtcPresent "Parking assist sensors: front dtc present; raw 3 = signal not available (SNA)";
CM_ SG_ 814 PARK_sensorStatusFrontCounter "Parking assist sensors: sensor status front counter";
CM_ SG_ 814 PARK_sensorStatusFrontChecksum "Parking assist sensors: sensor status front checksum";
CM_ BO_ 830 "Parking assist sensors message: sensor status rear";
CM_ SG_ 830 PARK_rearRightSensorState "Reports the state of the rear right ultrasonic sensor.; raw 3 = signal not available (SNA)";
CM_ SG_ 830 PARK_rearRightMiddleSensorState "Reports the state of the rear right middle ultrasonic sensor.; raw 3 = signal not available (SNA)";
CM_ SG_ 830 PARK_rearLeftMiddleSensorState "Reports the state of the rear left middle ultrasonic sensor.; raw 3 = signal not available (SNA)";
CM_ SG_ 830 PARK_rearLeftSensorState "Reports the state of the rear left ultrasonic sensor.; raw 3 = signal not available (SNA)";
CM_ SG_ 830 PARK_rearLeftRawDistData "Zone defined as -90 degrees to -125 degrees, distance to object in units of centimeters.; raw 255 = signal not available (SNA)";
CM_ SG_ 830 PARK_rearRightRawDistData "Zone defined as +125 degrees to +90 degrees, distance to object in units of centimeters.; raw 255 = signal not available (SNA)";
CM_ SG_ 830 PARK_systemStatusRear "Parking assist sensors: system status rear; raw 3 = signal not available (SNA)";
CM_ SG_ 830 PARK_rearDtcPresent "Parking assist sensors: rear dtc present; raw 3 = signal not available (SNA)";
CM_ SG_ 830 PARK_sensorStatusRearCounter "Parking assist sensors: sensor status rear counter";
CM_ SG_ 830 PARK_sensorStatusRearChecksum "Parking assist sensors: sensor status rear checksum";
CM_ BO_ 798 "Parking assist sensors message: status";
CM_ SG_ 798 PARK_status "Indicates status of park assist function; raw 3 = signal not available (SNA)";
CM_ SG_ 798 PARK_serviceRequest "Indicates whether or not PARK sensors/ECU require service; raw 3 = signal not available (SNA)";
CM_ SG_ 798 PARK_systemDtcPresent "Boolean indicating whether or not there is a DTC present; raw 3 = signal not available (SNA)";
CM_ SG_ 798 PARK_statusCounter "Parking assist sensors: status counter";
CM_ SG_ 798 PARK_statusChecksum "Parking assist sensors: status checksum";
CM_ SG_ 798 PARK_majorVersion "Parking assist sensors: major version; raw 255 = signal not available (SNA)";
CM_ SG_ 798 PARK_minorVersion "Parking assist sensors: minor version; raw 255 = signal not available (SNA)";
CM_ SG_ 798 PARK_subMinorVersion "Parking assist sensors: sub minor version; raw 255 = signal not available (SNA)";
CM_ BO_ 782 "Parking assist sensors message: status2";
CM_ SG_ 782 PARK_frontSVACharID "Parking assist sensors: front SVA char ID";
CM_ SG_ 782 PARK_pscRightCurbType "The type of curb for the parallel parking slot on the right side.";
CM_ SG_ 782 PARK_rearSVACharID "Parking assist sensors: rear SVA char ID";
CM_ SG_ 782 PARK_pscLeftCurbType "The type of curb identified for a parallel parking space on the left.";
CM_ SG_ 782 PARK_autoCalComplete "Parking assist sensors: auto cal complete";
CM_ SG_ 782 PARK_geometryType "Parking assist sensors: geometry type";
CM_ SG_ 782 PARK_tireFitment "Parking assist sensors: tire fitment; raw 3 = signal not available (SNA)";
CM_ SG_ 782 PARK_rackDetected "Parking assist sensors: rack detected; raw 3 = signal not available (SNA)";
CM_ SG_ 782 PARK_sdiActive "Whether or not the raw sensor measurements from the ultrasonics are present and valid";
CM_ SG_ 782 PARK_sdiNoise "The output of the noise detection algorithm for raw sensor measurements, indicates if the measurements are degraded due to ambient noise.; raw 3 = signal not available (SNA)";
CM_ SG_ 782 PARK_sdiBlindSpotRight "The output of the PARK ECU blindspot algorithm on the right side of the car, indicates the presence of a vehicle.; raw 3 = signal not available (SNA)";
CM_ SG_ 782 PARK_sdiBlindSpotLeft "The output of the PARK ECU blindspot algorithm on the left side of the car, indicates the presence of a vehicle.; raw 3 = signal not available (SNA)";
CM_ SG_ 782 PARK_sensorType "Parking assist sensors: sensor type; raw 3 = signal not available (SNA)";
CM_ SG_ 782 PARK_status2Counter "Parking assist sensors: status2 counter";
CM_ SG_ 782 PARK_status2Checksum "Parking assist sensors: status2 checksum";
CM_ BO_ 1329 "Radar message: info";
CM_ SG_ 1329 RADC_infoIndex "Radar: info index";
CM_ SG_ 1329 RADC_infoBuildType "Radar: info build type";
CM_ SG_ 1329 RADC_infoBuildConfigID "Radar: info build config ID";
CM_ SG_ 1329 RADC_infoHardwareID "Radar: info hardware ID";
CM_ SG_ 1329 RADC_infoComponentID "Radar: info component ID";
CM_ SG_ 1329 RADC_infoPcbaID "Radar: info pcba ID";
CM_ SG_ 1329 RADC_infoAssemblyID "Radar: info assembly ID";
CM_ SG_ 1329 RADC_infoUsageID "Radar: info usage ID";
CM_ SG_ 1329 RADC_infoSubUsageID "Radar: info sub usage ID";
CM_ SG_ 1329 RADC_infoApplicationCRC "Radar: info application CRC";
CM_ SG_ 1329 RADC_infoPlatformType "Radar: info platform type";
CM_ SG_ 1329 RADC_infoMajorVersion "Radar: info major version";
CM_ SG_ 1329 RADC_infoBranchOrigin "Radar: info branch origin";
CM_ SG_ 1329 RADC_infoMaturity "Radar: info maturity";
CM_ SG_ 1329 RADC_infoHardwareRevision "Radar: info hardware revision";
CM_ SG_ 1329 RADC_infoBootUdsProtoVersion "Radar: info boot uds proto version";
CM_ SG_ 1329 RADC_infoBootloaderCRC "Radar: info bootloader CRC";
CM_ BO_ 257 "Restraint control module message: inertial1";
CM_ SG_ 257 RCM_yawRate "Offset compensated yaw rate measured by the airbag ECU. ISO axis convention (Positive during left turn); raw 32768 = signal not available (SNA)";
CM_ SG_ 257 RCM_pitchRate "Offset compensated pitch rate measured by the airbag ECU. ISO axis convention (positive when the nose pitches down); raw 16384 = signal not available (SNA)";
CM_ SG_ 257 RCM_rollRate "Offset compensated roll rate measured by the airbag ECU. ISO axis convention (positive during left turn); raw 16384 = signal not available (SNA)";
CM_ SG_ 257 RCM_rollRateQF "Restraint control module: roll rate QF";
CM_ SG_ 257 RCM_yawRateQF "Restraint control module: yaw rate QF";
CM_ SG_ 257 RCM_pitchRateQF "Restraint control module: pitch rate QF";
CM_ SG_ 257 RCM_inertial1Counter "Restraint control module: inertial1 counter";
CM_ SG_ 257 RCM_inertial1Checksum "Restraint control module: inertial1 checksum";
CM_ BO_ 273 "Restraint control module message: inertial2";
CM_ SG_ 273 RCM_longitudinalAccel "Offset compensated longitudinal acceleration measured by the airbag ECU. ISO axis convention (positive during forward acceleration); raw 32768 = signal not available (SNA)";
CM_ SG_ 273 RCM_lateralAccel "Reports offset compensated lateral acceleration measured by the airbag ECU. Follows ISO axis convention that measurements are positive during left turns and negative during right turns.; raw 32768 = signal not available (SNA)";
CM_ SG_ 273 RCM_verticalAccel "Offset compensated vertical acceleration measured by the airbag ECU. ISO axis convention (positive up); raw 32768 = signal not available (SNA)";
CM_ SG_ 273 RCM_longitudinalAccelQF "Restraint control module: longitudinal accel QF";
CM_ SG_ 273 RCM_lateralAccelQF "Restraint control module: lateral accel QF";
CM_ SG_ 273 RCM_verticalAccelQF "Restraint control module: vertical accel QF";
CM_ SG_ 273 RCM_CGTranslationFault "Restraint control module: CG translation fault";
CM_ SG_ 273 RCM_inertial2Counter "Restraint control module: inertial2 counter";
CM_ SG_ 273 RCM_inertial2Checksum "Restraint control module: inertial2 checksum";
CM_ BO_ 849 "Restraint control module message: info";
CM_ SG_ 849 RCM_infoIndex "Restraint control module: info index";
CM_ SG_ 849 RCM_infoBuildType "Restraint control module: info build type";
CM_ SG_ 849 RCM_infoComponentID "Restraint control module: info component ID";
CM_ SG_ 849 RCM_infoPcbaID "Reports the Restraint Control Module (RCM) Printed Circuit Board Assembly (PCBA) identifier.";
CM_ SG_ 849 RCM_infoAssemblyID "Restraint control module: info assembly ID";
CM_ SG_ 849 RCM_infoUsageID "Reports the Restraint Control Module (RCM) usage identification.";
CM_ SG_ 849 RCM_infoApplicationCRC "Reports the Restraint Control Module (RCM) application Cyclic Redundancy Check (CRC).";
CM_ SG_ 849 RCM_infoBootUdsProtoVersion "Reports the Restraint Control Module (RCM) boot Unified Diagnostic Services (UDS) protocol version.";
CM_ SG_ 849 RCM_infoBootloaderCRC "Reports the Restraint Control Module (RCM) bootloader Cyclic Redundancy Check (CRC).";
CM_ SG_ 849 RCM_infoAlgoCalID "Reports the Restraint Control Module (RCM) algorithm calibration identification.";
CM_ SG_ 849 RCM_infoVariantCRC "Reports the Restraint Control Module (RCM) variant Cyclic Redundancy Check (CRC).";
CM_ BO_ 529 "Restraint control module message: status";
CM_ SG_ 529 RCM_statusChecksum "Restraint control module: status checksum";
CM_ SG_ 529 RCM_statusCounter "Restraint control module: status counter";
CM_ SG_ 529 RCM_armStatus "Reports the arm status of the Restraint Control Module (RCM).; raw 3 = signal not available (SNA)";
CM_ SG_ 529 RCM_warningIndicatorState "Reports whether the Restraint Control Module (RCM) warning indicator is present on the User Interface (UI).; raw 3 = signal not available (SNA)";
CM_ SG_ 529 RCM_passAirbagIndicatorRequest "Reports status of the Front Passenger Airbag Off telltale.; raw 3 = signal not available (SNA)";
CM_ SG_ 529 RCM_airbagCutoffStatus "Reports the front passenger airbag enabled or disabled status.; raw 3 = signal not available (SNA)";
CM_ SG_ 529 RCM_alrSwitchStatus "Reports status of the front passenger automatic locking seat belt retractor.; raw 3 = signal not available (SNA)";
CM_ SG_ 529 RCM_vinLearnFlag "Reports whether the Vehicle Identification Number has been learned.; raw 3 = signal not available (SNA)";
CM_ SG_ 529 RCM_seatTrackPositionDrvr "Driver seat track position status; raw 3 = signal not available (SNA)";
CM_ SG_ 529 RCM_seatTrackPositionPass "Passenger seat track position status; raw 3 = signal not available (SNA)";
CM_ SG_ 529 RCM_edr1State "Reports status of Restraint Control Module (RCM) Event Data Recorder (EDR) memory slot 1.";
CM_ SG_ 529 RCM_edr2State "Reports status of Restraint Control Module (RCM) Event Data Recorder (EDR) memory slot 2.";
CM_ SG_ 529 RCM_keepPowerReason "Restraint Control Module request to maintain power; raw 8 = signal not available (SNA)";
CM_ SG_ 529 RCM_imuOffsetLearnState "Restraint control module: imu offset learn state";
CM_ SG_ 529 RCM_edr3State "Reports status of Restraint Control Module (RCM) Event Data Recorder (EDR) memory slot 3.";
CM_ SG_ 529 RCM_driverOrientationInitStatus "Restraint control module: driver orientation init status; raw 7 = signal not available (SNA)";
CM_ SG_ 529 RCM_occupantClassificationSource "Indicates whether the occupant classification source is the Right Vehicle Controller (VCRIGHT) or the Occupancy Classification System - 1st Row Passenger (OCS1P).";
CM_ SG_ 529 RCM_pedProEDR1State "Reports status of the PedPro Event Data Recorder (EDR) memory slot 1.";
CM_ SG_ 529 RCM_pedProEDR2State "Reports status of the PedPro Event Data Recorder (EDR) memory slot 2.";
CM_ BO_ 879 "Tire pressure monitoring message: status c";
CM_ SG_ 879 TPMS_c_globalHardWarning "Tire pressure monitoring: c global hard warning";
CM_ SG_ 879 TPMS_c_globalSoftWarning "Tire pressure monitoring: c global soft warning";
CM_ SG_ 879 TPMS_systemMalfunction "Tire pressure monitoring: system malfunction";
CM_ SG_ 879 TPMS_WA_version "Tire pressure monitoring: WA version";
CM_ SG_ 879 TPMS_globalDeltaPressure "Tire pressure monitoring: global delta pressure";
CM_ SG_ 879 TPMS_newSensorLearnt "Tire pressure monitoring: new sensor learnt";
CM_ SG_ 879 TPMS_softWarningRR "Tire pressure monitoring: soft warning RR";
CM_ SG_ 879 TPMS_hardWarningRR "Tire pressure monitoring: hard warning RR";
CM_ SG_ 879 TPMS_softWarningRL "Tire pressure monitoring: soft warning RL";
CM_ SG_ 879 TPMS_hardWarningRL "Tire pressure monitoring: hard warning RL";
CM_ SG_ 879 TPMS_softWarningFR "Tire pressure monitoring: soft warning FR";
CM_ SG_ 879 TPMS_hardWarningFR "Tire pressure monitoring: hard warning FR";
CM_ SG_ 879 TPMS_softWarningFL "Tire pressure monitoring: soft warning FL";
CM_ SG_ 879 TPMS_hardWarningFL "Tire pressure monitoring: hard warning FL";
CM_ SG_ 879 TPMS_learningStatus "Monitors Tire Pressure Monitoring System (TPMS) Learn Status and evaluates issues.";
CM_ SG_ 879 TPMS_localisationStatus "Monitors Tire Pressure Monitoring System (TPMS) Localization Status and evaluates issues.";
CM_ SG_ 879 TPMS_deltaPressWarningFL "Tire pressure monitoring: delta press warning FL";
CM_ SG_ 879 TPMS_deltaPressWarningFR "Tire pressure monitoring: delta press warning FR";
CM_ SG_ 879 TPMS_deltaPressWarningRL "Tire pressure monitoring: delta press warning RL";
CM_ SG_ 879 TPMS_deltaPressWarningRR "Tire pressure monitoring: delta press warning RR";
CM_ SG_ 879 TPMS_sensorNoResponseFL "Count of times Front Left sensor did not respond to message";
CM_ SG_ 879 TPMS_sensorNoResponseFR "Count of times Front Right sensor did not respond to message";
CM_ SG_ 879 TPMS_sensorNoResponseRL "Count of times Rear Left sensor did not respond to message";
CM_ SG_ 879 TPMS_sensorNoResponseRR "Count of times Rear Right sensor did not respond to message";
CM_ SG_ 879 TPMS_sensorThermShutdownFL "Tire pressure monitoring: sensor therm shutdown FL";
CM_ SG_ 879 TPMS_sensorThermShutdownFR "Tire pressure monitoring: sensor therm shutdown FR";
CM_ SG_ 879 TPMS_sensorThermShutdownRL "Tire pressure monitoring: sensor therm shutdown RL";
CM_ SG_ 879 TPMS_sensorThermShutdownRR "Tire pressure monitoring: sensor therm shutdown RR";
CM_ SG_ 879 TPMS_sensorBatteryLowFL "Tracks near end of life sensor batteries in the fleet.";
CM_ SG_ 879 TPMS_sensorBatteryLowFR "Tracks near end of life sensor batteries in the fleet.";
CM_ SG_ 879 TPMS_sensorBatteryLowRL "Tracks near end of life sensor batteries in the fleet.";
CM_ SG_ 879 TPMS_sensorBatteryLowRR "Tracks near end of life sensor batteries in the fleet.";
CM_ SG_ 879 TPMS_sensorDefectiveFL "Tracks malfunctioning sensors in the fleet.";
CM_ SG_ 879 TPMS_sensorDefectiveFR "Tracks malfunctioning sensors in the fleet.";
CM_ SG_ 879 TPMS_sensorDefectiveRL "Tracks malfunctioning sensors in the fleet.";
CM_ SG_ 879 TPMS_sensorDefectiveRR "Tracks malfunctioning sensors in the fleet.";
CM_ SG_ 879 TPMS_ecuUnderVoltage "Tire pressure monitoring: ecu under voltage";
CM_ SG_ 879 TPMS_ecuOverVoltage "Tire pressure monitoring: ecu over voltage";
CM_ SG_ 879 TPMS_ecuRamRomNvMFail "Tire pressure monitoring: ecu ram rom nv m fail";
CM_ SG_ 879 TPMS_rfReceiverFail "Tire pressure monitoring: rf receiver fail";
CM_ SG_ 879 TPMS_wheelPulseMissing "Tire pressure monitoring: wheel pulse missing";
CM_ SG_ 879 TPMS_vehicleSpeedFail "Tire pressure monitoring: vehicle speed fail";
CM_ SG_ 879 TPMS_externalTemperatureFail "Tire pressure monitoring: external temperature fail";
CM_ SG_ 879 TPMS_eolNotCompleted "Monitors sensor completion of End of Line (EOL) routine.";
CM_ SG_ 879 TPMS_rcpFront "Front tire recommended cold pressure";
CM_ SG_ 879 TPMS_rcpRear "Rear tire recommended cold pressure";
CM_ BO_ 799 "Tire pressure monitoring message: data";
CM_ SG_ 799 TPMS_pressureFL "front left tire pressure; raw 255 = signal not available (SNA)";
CM_ SG_ 799 TPMS_temperatureFL "front left tire temperature; raw 255 = signal not available (SNA)";
CM_ SG_ 799 TPMS_pressureFR "front right tire pressure; raw 255 = signal not available (SNA)";
CM_ SG_ 799 TPMS_temperatureFR "front right tire temperature; raw 255 = signal not available (SNA)";
CM_ SG_ 799 TPMS_pressureRL "rear left tire pressure; raw 255 = signal not available (SNA)";
CM_ SG_ 799 TPMS_temperatureRL "rear left tire temperature; raw 255 = signal not available (SNA)";
CM_ SG_ 799 TPMS_pressureRR "rear right tire pressure; raw 255 = signal not available (SNA)";
CM_ SG_ 799 TPMS_temperatureRR "rear right tire temperature; raw 255 = signal not available (SNA)";
CM_ BO_ 1519 "Tire pressure monitoring message: info";
CM_ SG_ 1519 TPMS_infoIndex "Tire pressure monitoring: info index";
CM_ SG_ 1519 TPMS_infoComponentID "Tire pressure monitoring: info component ID";
CM_ SG_ 1519 TPMS_infoPcbaID "Tire pressure monitoring: info pcba ID";
CM_ SG_ 1519 TPMS_infoAssemblyID "Tire pressure monitoring: info assembly ID";
CM_ SG_ 1519 TPMS_infoUsageID "Tire pressure monitoring: info usage ID";
CM_ SG_ 1519 TPMS_infoApplicationCRC "Tire pressure monitoring: info application CRC";
CM_ SG_ 1519 TPMS_infoBootUdsProtoVersion "Tire pressure monitoring: info boot uds proto version";
CM_ SG_ 1519 TPMS_infoBootloaderCRC "Tire pressure monitoring: info bootloader CRC";
CM_ BO_ 850 "TRCM ECU message: info";
CM_ SG_ 850 TRCM_infoIndex "TRCM ECU: info index";
CM_ SG_ 850 TRCM_infoBuildType "TRCM ECU: info build type";
CM_ SG_ 850 TRCM_infoBuildConfigId "TRCM ECU: info build config id";
CM_ SG_ 850 TRCM_infoHardwareId "TRCM ECU: info hardware id";
CM_ SG_ 850 TRCM_infoComponentId "TRCM ECU: info component id";
CM_ SG_ 850 TRCM_infoPcbaId "TRCM ECU: info pcba id";
CM_ SG_ 850 TRCM_infoAssemblyId "TRCM ECU: info assembly id; raw 255 = signal not available (SNA)";
CM_ SG_ 850 TRCM_infoUsageId "TRCM ECU: info usage id";
CM_ SG_ 850 TRCM_infoSubUsageId "TRCM ECU: info sub usage id";
CM_ SG_ 850 TRCM_infoAppCrc "TRCM ECU: info app crc";
CM_ SG_ 850 TRCM_infoAppGitHash "TRCM ECU: info app git hash";
CM_ SG_ 850 TRCM_infoBootGitHash "TRCM ECU: info boot git hash";
CM_ SG_ 850 TRCM_infoBootUdsProtoVersion "TRCM ECU: info boot uds proto version";
CM_ SG_ 850 TRCM_infoBootCrc "TRCM ECU: info boot crc";
CM_ BO_ 1021 "Touchscreen user interface computer message: autopilot control; forwarded onto this bus by the gateway";
CM_ SG_ 1021 UI_autopilotControlIndex "Touchscreen user interface computer: autopilot control index";
CM_ SG_ 1021 UI_hovEnabled "UI HOV routes enabled";
CM_ SG_ 1021 UI_smartSetSpeedOffset "TACC will apply this offset over the speed limit";
CM_ SG_ 1021 UI_smartSetSpeedOffsetType "Offset applied will be a percentage or fixed value based on this setting";
CM_ SG_ 1021 UI_fsdStopsControlEnabled "Indicates if autopilot control for traffic lights and stops signs has been enabled by the driver";
CM_ SG_ 1021 UI_smartSetSpeed "TACC will use speed limit + offset as user set speed when enabled";
CM_ SG_ 1021 UI_automaticSetSpeedOffset "Maximum set speed offset would be determined automatically when this option is enabled";
CM_ SG_ 1021 UI_enableFullSelfDriving "Indicates if the driver has enabled FSD behaviors";
CM_ SG_ 1021 UI_hasFullSelfDriving "Indicates if the vehicle hardware, software, and dependencies allow FSD";
CM_ SG_ 1021 UI_autosteerActivation "User-selected autosteer activation method";
CM_ SG_ 1021 UI_fsdBetaRequest "User accepted disclaimer and requested FSD (Supervised) builds";
CM_ SG_ 1021 UI_fullSelfDrivingSuspended "Full self driving is suspended";
CM_ SG_ 1021 UI_disableOptionalLaneChanges "Disable optional lane changes while FSD is controlling";
CM_ SG_ 1021 UI_applyADDWWarnings "ADDW warnings are enabled on this vehicle";
CM_ SG_ 1021 UI_selectableCameraRequest "Infotainment selectable camera state request from AP signal; raw 15 = signal not available (SNA)";
CM_ SG_ 1021 UI_driverMonitorConfirmation "Driver attentiveness confirmation";
CM_ SG_ 1021 UI_parkAssistUseVision "Reports if the vehicle should use vision park assist.";
CM_ SG_ 1021 UI_noStalkConfirmAlertHaptic "Detects if alert haptic feedback should trigger.";
CM_ SG_ 1021 UI_noStalkConfirmAlertChime "Detects if alert chime should trigger.";
CM_ SG_ 1021 UI_factorySummonEnable "Controls Factory Summon.";
CM_ SG_ 1021 UI_enableCabinCamera "Indicates if autopilot can enable cabin camera";
CM_ SG_ 1021 UI_enableAutopilotStopWarning "Enables the Autopilot active red light warning function.";
CM_ SG_ 1021 UI_enableVisionSpeedControl "Indicates if autopilot can enable vision speed control";
CM_ SG_ 1021 UI_enableTeslaAutopark "Indicates if autopilot can enable Telsa Autopark control";
CM_ SG_ 1021 UI_autoTurnSignalMode "Turn signal activation mode";
CM_ SG_ 1021 UI_enableCabinAudioRecording "Indicates if autopilot can record cabin audio";
CM_ SG_ 1021 UI_autopilotDrivingProfile "Driving profile for autopilot control";
CM_ BO_ 659 "Touchscreen user interface computer message: chassis control; forwarded onto this bus by the gateway";
CM_ SG_ 659 UI_steeringTuneRequest "UI customer level request for steering feel. MS had comfort, normal, sport. M3 intent is Normal, sport see SW-95934";
CM_ SG_ 659 UI_tractionControlMode "Transport user selected traction control modes";
CM_ SG_ 659 UI_parkBrakeRequest "User selection for Park brake; raw 3 = signal not available (SNA)";
CM_ SG_ 659 UI_winchModeRequest "Winch mode (towing) request";
CM_ SG_ 659 UI_trailerMode "Indicates whether trailer mode is selected. To be used when towing a trailer.";
CM_ SG_ 659 UI_accOvertakeEnable "Enable ACC Overtake assistance (reduce follow distance when the turn signal is on), UI firmware only sets datavalue to True; raw 3 = signal not available (SNA)";
CM_ SG_ 659 UI_aebEnable "Enable Autonomous Emergency Brakes; raw 3 = signal not available (SNA)";
CM_ SG_ 659 UI_aesEnable "Enable Automatic Emergency Steering (associated datavalue set to true and never changed by UI firmware); raw 3 = signal not available (SNA)";
CM_ SG_ 659 UI_ahlbEnable "Enable Automatic High/Low Beams; raw 3 = signal not available (SNA)";
CM_ SG_ 659 UI_autoLaneChangeEnable "Enable Automatic Lane Change; raw 3 = signal not available (SNA)";
CM_ SG_ 659 UI_winchProxUserOverride "User feedback from tow mode panel confirming that charge cable is disconnected when vehicle is unable to determine cable status";
CM_ SG_ 659 UI_autoParkRequest "Request Automatic Parking; raw 15 = signal not available (SNA)";
CM_ SG_ 659 UI_bsdEnable "Enable Blind Spot Detection (datavalue defaults to true and not changed by UI firmware); raw 3 = signal not available (SNA)";
CM_ SG_ 659 UI_fcwEnable "Enable Forward Collision Warning; raw 3 = signal not available (SNA)";
CM_ SG_ 659 UI_fcwSensitivity "Forward Collision Warning Level; raw 3 = signal not available (SNA)";
CM_ SG_ 659 UI_latControlEnable "Enable Lateral Control (lane centering, lane keeping, lane changing); raw 3 = signal not available (SNA)";
CM_ SG_ 659 UI_ldwEnable "Enable Lane Departure Warning; raw 3 = signal not available (SNA)";
CM_ BO_ 1016 "Touchscreen user interface computer message: driver assist control; forwarded onto this bus by the gateway";
CM_ SG_ 1016 UI_ulcStalkConfirm "Drive on autopilot stalk confirmation mode (set by feature config).";
CM_ SG_ 1016 UI_lssLkaEnabled "User setting for lane keep assist";
CM_ SG_ 1016 UI_lssLdwEnabled "User setting for lane departure warning";
CM_ SG_ 1016 UI_driveOnMapsEnable "Drive on Autopilot enabled";
CM_ SG_ 1016 UI_lssElkEnabled "User setting for emergency lane keep";
CM_ SG_ 1016 UI_selfParkRequest "Self park request; raw 15 = signal not available (SNA)";
CM_ SG_ 1016 UI_followNavRouteEnable "Following route with Drive on Autopilot";
CM_ SG_ 1016 UI_ulcSpeedConfig "Drive on autopilot speed base lane changes mode.";
CM_ SG_ 1016 UI_suppressExitPassingLane "Navigate on Autopilot will not suggest lane changes out of the passing lane";
CM_ SG_ 1016 UI_smartSummonType "Type of smart summon session (Find Me, Pin Drop, Smart Autopark)";
CM_ SG_ 1016 UI_isaSpeedingChimeMuted "Reports the user input of Intelligent Speed Assist (ISA) speed chime alert option.";
CM_ BO_ 568 "Touchscreen user interface computer message: driver assist map data; forwarded onto this bus by the gateway";
CM_ SG_ 568 UI_roadClass "Autopilot map road class; raw 0 = signal not available (SNA)";
CM_ SG_ 568 UI_navRouteActive "Navigation route is active";
CM_ SG_ 568 UI_parallelAutoparkEnabled "Autopilot map parallel park enabled.";
CM_ SG_ 568 UI_perpendicularAutoparkEnabled "Autopilot map perpendicular park enabled.";
CM_ SG_ 568 UI_controlledAccess "DAS map controlled access segment.";
CM_ SG_ 568 UI_autosteerRestricted "Autopilot map is autostreer restricted.";
CM_ BO_ 760 "Touchscreen user interface computer message: gps vehicle speed; forwarded onto this bus by the gateway";
CM_ SG_ 760 UI_mapSpeedLimitUnits "Autopilot map speed limit units.";
CM_ SG_ 760 UI_mppSpeedLimit "Autopilot map speed limit";
CM_ SG_ 760 UI_gpsNmeaMIA "GPS NMEA data MIA";
CM_ SG_ 760 UI_gpsAntennaDisconnected "GPS antenna state";
CM_ SG_ 760 UI_conditionalLimitActive "Conditional speed limit condition is currently active";
CM_ SG_ 760 UI_conditionalSpeedLimit "Conditional speed limit value; raw 31 = signal not available (SNA)";
CM_ BO_ 1011 "Touchscreen user interface computer message: odo; forwarded onto this bus by the gateway";
CM_ SG_ 1011 UI_odometer "Odometer; raw 16777215 = signal not available (SNA)";
CM_ BO_ 820 "Touchscreen user interface computer message: powertrain control; forwarded onto this bus by the gateway";
CM_ SG_ 820 UI_pedalMap "Switch between various platform specific pedal maps";
CM_ SG_ 820 UI_enableRegenBackfill "Indicates if regenerative braking backfill has been enabled by the driver";
CM_ SG_ 820 UI_regenTorqueMax "Maximum regen torque from UI - reports different value when in track mode";
CM_ SG_ 820 UI_limitMode "Commands limited drive inverter capabilities based on special vehicle modes";
CM_ SG_ 820 UI_motorOnMode "Request from the UI to selectively enable or disable a drive unit (dev-only)";
CM_ SG_ 820 UI_stoppingMode "Low-speed behavior when no pedal is pressed (stopping/rolling/creeping)";
CM_ SG_ 820 UI_speedLimit "Maximum allowed speed enforced at vehicle level.; raw 511 = signal not available (SNA)";
CM_ SG_ 820 UI_enableSmartShift "Stalkless convenience feature that allows unparking with only a firm press of brake pedal";
CM_ SG_ 820 UI_navVehParallelToRdCanContinue "Whether the vehicle is parallel parked on a public road; raw 0 = signal not available (SNA)";
CM_ BO_ 723 "Touchscreen user interface computer message: solar data; forwarded onto this bus by the gateway";
CM_ SG_ 723 UI_isSunUp "is sun up; raw 3 = signal not available (SNA)";
CM_ SG_ 723 UI_solarElevationAngle "Solar Elevation Angle; raw 127 = signal not available (SNA)";
CM_ SG_ 723 UI_screenPCBTemperature "Temperature of display PCB";
CM_ SG_ 723 UI_minsToSunset "time until to sunset";
CM_ SG_ 723 UI_minsToSunrise "time until to sunrise";
CM_ BO_ 851 "Touchscreen user interface computer message: status; forwarded onto this bus by the gateway";
CM_ SG_ 851 UI_touchActive "No touchscreen errors";
CM_ SG_ 851 UI_audioActive "Audio system is ready.";
CM_ SG_ 851 UI_cellActive "Cell is powered";
CM_ SG_ 851 UI_displayReady "UI is ready (GUI_allReady) and display is ok (GUI_displayHardwareOK)";
CM_ SG_ 851 UI_displayOn "UI display on/off status";
CM_ SG_ 851 UI_wifiActive "WiFi active.";
CM_ SG_ 851 UI_wifiConnected "WiFi Connected.";
CM_ SG_ 851 UI_readyForDrive "Ready for drive (UI ready or self park request)";
CM_ SG_ 851 UI_cellConnected "Detects if the cell is connected to a network.";
CM_ SG_ 851 UI_vpnActive "VPN connected.";
CM_ SG_ 851 UI_factoryReset "UI request for factory reset; raw 0 = signal not available (SNA)";
CM_ SG_ 851 UI_gpsActive "GPS has valid fix";
CM_ SG_ 851 UI_cellNetworkTechnology "Describes the type of cellular network to which the car computer is connected: GPRS_2G(114Kbps) < EGDE_2G(368Kbps) < 3G(3Mbps) < HSDPA_3G(14Mbps) < HSPAplus_4Gg(168Mbps) < 4G_LTE(299Mbps); raw 15 = signal not available (SNA)";
CM_ SG_ 851 UI_falseTouchCounter "Count false touches after display is off.";
CM_ SG_ 851 UI_cellSignalBars "Number of cellular signal bars displayed on the UI, derived from cellSignalStrength; raw 7 = signal not available (SNA)";
CM_ SG_ 851 UI_trailerModeTelltale "Color of the trailer mode telltale";
CM_ SG_ 851 UI_pcbTemperature "PCB digital temp sensor reading in DegC";
CM_ SG_ 851 UI_cpuTemperature "Apollo Lake SOC temperature in DegC";
CM_ BO_ 991 "Touchscreen user interface computer message: status2; forwarded onto this bus by the gateway";
CM_ SG_ 991 UI_userActivity "Indicates user interaction with the center display";
CM_ SG_ 991 UI_activeTouchPoints "Quantity of active touch points on the Center Display";
CM_ SG_ 991 UI_linkState "Connectivity link state";
CM_ SG_ 991 UI_autopilotSentryRequest "whether AP sentry mode should be enabled";
CM_ SG_ 991 UI_mobileAppConnected "Reports if Web Real-Time Communication (WebRTC) connection is connected while summon screen is open on the mobile app.";
CM_ SG_ 991 UI_phoneLeftInCabin "Used for monitoring phone left behind feature";
CM_ SG_ 991 UI_autoshiftDRState "Reports the User Interface (UI) autoshift Drive/Reverse state.";
CM_ SG_ 991 UI_wifiBtModuleType "Reports the type of Wi-Fi and Bluetooth (BT) module.";
CM_ SG_ 991 UI_selfParkState "Reports the auto park state changes.; raw 255 = signal not available (SNA)";
CM_ SG_ 991 UI_summonDeviceIndex "Reports which device is being used to control summon.";
CM_ SG_ 991 UI_fullScreenMode "Aggregates all situations with which the UI is using the entire screen so stalkless gear controls are not present";
CM_ BO_ 952 "Touchscreen user interface computer message: tpms RC psetting; forwarded onto this bus by the gateway";
CM_ SG_ 952 UI_sendCalibrateTireRequest "Reports UI requests for PMDI to start the tire pressure calibration routine.";
CM_ BO_ 852 "Touchscreen user interface computer message: ui health status; forwarded onto this bus by the gateway";
CM_ SG_ 852 UI_centerDisplayRunning "is center display running";
CM_ SG_ 852 UI_centerDisplayPowerOn "center display power on";
CM_ SG_ 852 UI_rearDisplayRunning "is rear display running";
CM_ SG_ 852 UI_rearDisplayPowerOn "rear display power on";
CM_ BO_ 947 "Touchscreen user interface computer message: vehicle control2; forwarded onto this bus by the gateway";
CM_ SG_ 947 UI_gloveboxRequest "UI request to open the glovebox";
CM_ SG_ 947 UI_trunkRequest "Rear trunk request";
CM_ SG_ 947 UI_PINToDriveEnabled "UI customer level request to pin to drive enabled.";
CM_ SG_ 947 UI_PINToDrivePassed "UI customer level request to enable drive with pin passed.";
CM_ SG_ 947 UI_disableMirrorAutoDim "Request to disable side and rear-view mirror auto dim";
CM_ SG_ 947 UI_lightSwitch "Headlight mode; raw 4 = signal not available (SNA)";
CM_ SG_ 947 UI_readyToAddKey "Ready to add key";
CM_ SG_ 947 UI_alarmTriggerRequest "Alarm activation request from UI";
CM_ SG_ 947 UI_displayOnForUser "User is present";
CM_ SG_ 947 UI_BLEPushNotificationRequest "Reports that the User Interface (UI) wants to talk to a phone and Vehicle Controller Security (VCSEC) should let all connected phones know.";
CM_ SG_ 947 UI_keepAutopilotAwake "Reports the request for Vehicle Controller (VC) to keep autopilot awake.";
CM_ SG_ 947 UI_batteryPreconditioningRequest "Requests battery preconditioning.";
CM_ SG_ 947 UI_autopilotPowerStateRequest "Requests different power states from autopilot ECU depending on feature usage.";
CM_ SG_ 947 UI_autoRollWindowsOnLockEnable "UI customer level request to enable auto-roll windows on lock";
CM_ SG_ 947 UI_steeringWheelHeatReq "Request to enable steering wheel heater";
CM_ SG_ 947 UI_disableHorn "Request to disable horn";
CM_ SG_ 947 UI_frontLeftSeatFanReq "Request for front left seat ventilation";
CM_ SG_ 947 UI_frontRightSeatAutoClimateReq "UI setting to enable auto seat heating and cooling for front right seat";
CM_ SG_ 947 UI_frontRightSeatFanReq "Request for front left seat ventilation";
CM_ SG_ 947 UI_frontLeftSeatAutoClimateReq "UI setting to enable auto seat heating and cooling for front left seat";
CM_ SG_ 947 UI_wiperHeaterReq "UI request to enable the wiper heater";
CM_ SG_ 947 UI_silentAlarm "Signal indicating alarms should be silenced";
CM_ BO_ 644 "Touchscreen user interface computer message: vehicle modes; forwarded onto this bus by the gateway";
CM_ SG_ 644 UI_transportMode "Reports UI Transport mode. Distinct from GTW transport mode.";
CM_ SG_ 644 UI_showroomMode "Reports UI showroom mode.";
CM_ SG_ 644 UI_serviceMode "Service diagnostics mode active";
CM_ SG_ 644 UI_carWashMode "Car Wash Mode";
CM_ SG_ 644 UI_gameMode "Game mode";
CM_ SG_ 644 UI_serviceModePlus "Extended service diagnostics mode active";
CM_ SG_ 644 UI_premiumAmpPowerOff "Premium amplifier power off request";
CM_ SG_ 644 UI_lightShowType "Type of the light show to be run";
CM_ SG_ 644 UI_upkeepMode "Reports UI Upkeep Mode state.";
CM_ BO_ 807 "USM ECU message: info";
CM_ SG_ 807 USM_infoIndex "USM ECU: info index";
CM_ SG_ 807 USM_infoBuildType "USM ECU: info build type";
CM_ SG_ 807 USM_infoBuildConfigId "USM ECU: info build config id";
CM_ SG_ 807 USM_infoHardwareId "USM ECU: info hardware id";
CM_ SG_ 807 USM_infoComponentId "USM ECU: info component id";
CM_ SG_ 807 USM_infoPcbaId "USM ECU: info pcba id";
CM_ SG_ 807 USM_infoAssemblyId "USM ECU: info assembly id; raw 255 = signal not available (SNA)";
CM_ SG_ 807 USM_infoUsageId "USM ECU: info usage id";
CM_ SG_ 807 USM_infoSubUsageId "USM ECU: info sub usage id";
CM_ SG_ 807 USM_infoAppCrc "USM ECU: info app crc";
BA_DEF_ BO_ "GenMsgCycleTime" INT 0 3600000;
BA_DEF_ BO_ "GenMsgSendType" ENUM "Cyclic","NotUsed","NotUsed","NotUsed","NotUsed","NotUsed","NotUsed","IfActive","NoMsgSendType","NotUsed";
BA_DEF_ BO_ "VFrameFormat" ENUM "StandardCAN","ExtendedCAN","reserved","J1939PG","reserved","reserved","reserved","reserved","reserved","reserved","reserved","reserved","reserved","reserved","StandardCAN_FD","ExtendedCAN_FD";
BA_DEF_ BO_ "CANFD_BRS" ENUM "0","1";
BA_DEF_ SG_ "GenSigSNA" STRING;
BA_DEF_ SG_ "SystemSignalLongSymbol" STRING;
BA_DEF_ SG_ "Confidence" ENUM "validated","plausible","layout-only","contradicted";
BA_DEF_DEF_ "GenMsgCycleTime" 0;
BA_DEF_DEF_ "GenMsgSendType" "NoMsgSendType";
BA_DEF_DEF_ "VFrameFormat" "StandardCAN";
BA_DEF_DEF_ "CANFD_BRS" "1";
BA_DEF_DEF_ "GenSigSNA" "";
BA_DEF_DEF_ "SystemSignalLongSymbol" "";
BA_DEF_DEF_ "Confidence" "layout-only";
BA_ "GenMsgCycleTime" BO_ 921 500;
BA_ "GenMsgSendType" BO_ 921 0;
BA_ "GenMsgCycleTime" BO_ 905 500;
BA_ "GenMsgSendType" BO_ 905 0;
BA_ "GenMsgCycleTime" BO_ 586 100;
BA_ "GenMsgSendType" BO_ 586 0;
BA_ "GenMsgCycleTime" BO_ 977 1000;
BA_ "GenMsgSendType" BO_ 977 0;
BA_ "GenMsgCycleTime" BO_ 785 1000;
BA_ "GenMsgSendType" BO_ 785 0;
BA_ "GenMsgCycleTime" BO_ 880 10;
BA_ "GenMsgSendType" BO_ 880 0;
BA_ "GenMsgCycleTime" BO_ 805 10000;
BA_ "GenMsgSendType" BO_ 805 0;
BA_ "GenMsgCycleTime" BO_ 813 10000;
BA_ "GenMsgSendType" BO_ 813 0;
BA_ "GenMsgCycleTime" BO_ 806 1000;
BA_ "GenMsgSendType" BO_ 806 0;
BA_ "GenMsgCycleTime" BO_ 846 100;
BA_ "GenMsgSendType" BO_ 846 0;
BA_ "GenMsgCycleTime" BO_ 926 100;
BA_ "GenMsgSendType" BO_ 926 0;
BA_ "GenMsgCycleTime" BO_ 606 100;
BA_ "GenMsgSendType" BO_ 606 0;
BA_ "GenMsgCycleTime" BO_ 542 40;
BA_ "GenMsgSendType" BO_ 542 0;
BA_ "GenMsgCycleTime" BO_ 590 100;
BA_ "GenMsgSendType" BO_ 590 0;
BA_ "GenMsgCycleTime" BO_ 526 40;
BA_ "GenMsgSendType" BO_ 526 0;
BA_ "GenMsgCycleTime" BO_ 558 40;
BA_ "GenMsgSendType" BO_ 558 0;
BA_ "GenMsgCycleTime" BO_ 814 100;
BA_ "GenMsgSendType" BO_ 814 0;
BA_ "GenMsgCycleTime" BO_ 830 100;
BA_ "GenMsgSendType" BO_ 830 0;
BA_ "GenMsgCycleTime" BO_ 798 500;
BA_ "GenMsgSendType" BO_ 798 0;
BA_ "GenMsgCycleTime" BO_ 782 250;
BA_ "GenMsgSendType" BO_ 782 0;
BA_ "GenMsgCycleTime" BO_ 1329 1000;
BA_ "GenMsgSendType" BO_ 1329 0;
BA_ "GenMsgCycleTime" BO_ 257 20;
BA_ "GenMsgSendType" BO_ 257 0;
BA_ "GenMsgCycleTime" BO_ 273 20;
BA_ "GenMsgSendType" BO_ 273 0;
BA_ "GenMsgCycleTime" BO_ 849 2000;
BA_ "GenMsgSendType" BO_ 849 0;
BA_ "GenMsgCycleTime" BO_ 529 100;
BA_ "GenMsgSendType" BO_ 529 0;
BA_ "GenMsgCycleTime" BO_ 879 1000;
BA_ "GenMsgSendType" BO_ 879 0;
BA_ "GenMsgCycleTime" BO_ 799 1000;
BA_ "GenMsgSendType" BO_ 799 0;
BA_ "GenMsgCycleTime" BO_ 1519 1000;
BA_ "GenMsgSendType" BO_ 1519 0;
BA_ "GenMsgCycleTime" BO_ 850 1000;
BA_ "GenMsgSendType" BO_ 850 0;
BA_ "GenMsgCycleTime" BO_ 1021 500;
BA_ "GenMsgSendType" BO_ 1021 0;
BA_ "GenMsgCycleTime" BO_ 659 500;
BA_ "GenMsgSendType" BO_ 659 0;
BA_ "GenMsgCycleTime" BO_ 1016 1000;
BA_ "GenMsgSendType" BO_ 1016 0;
BA_ "GenMsgCycleTime" BO_ 568 500;
BA_ "GenMsgSendType" BO_ 568 0;
BA_ "GenMsgCycleTime" BO_ 760 1000;
BA_ "GenMsgSendType" BO_ 760 0;
BA_ "GenMsgCycleTime" BO_ 1011 1000;
BA_ "GenMsgSendType" BO_ 1011 0;
BA_ "GenMsgCycleTime" BO_ 820 500;
BA_ "GenMsgSendType" BO_ 820 0;
BA_ "GenMsgCycleTime" BO_ 723 1000;
BA_ "GenMsgSendType" BO_ 723 0;
BA_ "GenMsgCycleTime" BO_ 851 500;
BA_ "GenMsgSendType" BO_ 851 0;
BA_ "GenMsgCycleTime" BO_ 991 500;
BA_ "GenMsgSendType" BO_ 991 0;
BA_ "GenMsgCycleTime" BO_ 952 1000;
BA_ "GenMsgSendType" BO_ 952 0;
BA_ "GenMsgCycleTime" BO_ 852 500;
BA_ "GenMsgSendType" BO_ 852 0;
BA_ "GenMsgCycleTime" BO_ 947 500;
BA_ "GenMsgSendType" BO_ 947 0;
BA_ "GenMsgCycleTime" BO_ 644 500;
BA_ "GenMsgSendType" BO_ 644 0;
BA_ "GenMsgCycleTime" BO_ 807 1000;
BA_ "GenMsgSendType" BO_ 807 0;
BA_ "Confidence" SG_ 921 DAS_autopilotState 0;
BA_ "GenSigSNA" SG_ 921 DAS_autopilotState "15";
BA_ "Confidence" SG_ 921 DAS_blindSpotRearLeft 0;
BA_ "GenSigSNA" SG_ 921 DAS_blindSpotRearLeft "3";
BA_ "Confidence" SG_ 921 DAS_blindSpotRearRight 0;
BA_ "GenSigSNA" SG_ 921 DAS_blindSpotRearRight "3";
BA_ "Confidence" SG_ 921 DAS_fusedSpeedLimit 0;
BA_ "GenSigSNA" SG_ 921 DAS_fusedSpeedLimit "0";
BA_ "Confidence" SG_ 921 DAS_suppressSpeedWarning 0;
BA_ "Confidence" SG_ 921 DAS_summonObstacle 0;
BA_ "Confidence" SG_ 921 DAS_summonClearedGate 0;
BA_ "Confidence" SG_ 921 DAS_visionOnlySpeedLimit 0;
BA_ "GenSigSNA" SG_ 921 DAS_visionOnlySpeedLimit "0";
BA_ "Confidence" SG_ 921 DAS_heaterState 0;
BA_ "GenSigSNA" SG_ 921 DAS_heaterState "0";
BA_ "Confidence" SG_ 921 DAS_forwardCollisionWarning 0;
BA_ "GenSigSNA" SG_ 921 DAS_forwardCollisionWarning "3";
BA_ "Confidence" SG_ 921 DAS_autoparkReady 0;
BA_ "Confidence" SG_ 921 DAS_autoParked 0;
BA_ "Confidence" SG_ 921 DAS_autoparkActive 0;
BA_ "Confidence" SG_ 921 DAS_summonFwdLeashReached 0;
BA_ "Confidence" SG_ 921 DAS_summonRvsLeashReached 0;
BA_ "Confidence" SG_ 921 DAS_lssState 0;
BA_ "Confidence" SG_ 921 DAS_sideCollisionAvoid 0;
BA_ "GenSigSNA" SG_ 921 DAS_sideCollisionAvoid "3";
BA_ "Confidence" SG_ 921 DAS_sideCollisionWarning 0;
BA_ "Confidence" SG_ 921 DAS_sideCollisionInhibit 0;
BA_ "Confidence" SG_ 921 DAS_laneDepartureWarning 0;
BA_ "GenSigSNA" SG_ 921 DAS_laneDepartureWarning "5";
BA_ "Confidence" SG_ 921 DAS_fleetSpeedState 0;
BA_ "Confidence" SG_ 921 DAS_autopilotHandsOnState 0;
BA_ "GenSigSNA" SG_ 921 DAS_autopilotHandsOnState "15";
BA_ "Confidence" SG_ 921 DAS_autoLaneChangeState 0;
BA_ "GenSigSNA" SG_ 921 DAS_autoLaneChangeState "31";
BA_ "Confidence" SG_ 921 DAS_summonAvailable 0;
BA_ "Confidence" SG_ 921 DAS_statusCounter 0;
BA_ "Confidence" SG_ 921 DAS_statusChecksum 0;
BA_ "Confidence" SG_ 905 DAS_accSpeedLimit 0;
BA_ "GenSigSNA" SG_ 905 DAS_accSpeedLimit "511";
BA_ "Confidence" SG_ 905 DAS_versionIdentifier 0;
BA_ "Confidence" SG_ 905 DAS_pmmObstacleSeverity 0;
BA_ "GenSigSNA" SG_ 905 DAS_pmmObstacleSeverity "7";
BA_ "Confidence" SG_ 905 DAS_pmmLoggingRequest 0;
BA_ "Confidence" SG_ 905 DAS_activationFailureStatus 0;
BA_ "Confidence" SG_ 905 DAS_pmmUltrasonicsFaultReason 0;
BA_ "Confidence" SG_ 905 DAS_pmmRadarFaultReason 0;
BA_ "Confidence" SG_ 905 DAS_pmmSysFaultReason 0;
BA_ "Confidence" SG_ 905 DAS_pmmCameraFaultReason 0;
BA_ "Confidence" SG_ 905 DAS_ACC_report 0;
BA_ "Confidence" SG_ 905 DAS_relaxCruiseLimits 0;
BA_ "Confidence" SG_ 905 DAS_csaState 0;
BA_ "Confidence" SG_ 905 DAS_radarTelemetry 0;
BA_ "Confidence" SG_ 905 DAS_robState 0;
BA_ "Confidence" SG_ 905 DAS_driverInteractionLevel 0;
BA_ "Confidence" SG_ 905 DAS_ppOffsetDesiredRamp 0;
BA_ "Confidence" SG_ 905 DAS_longCollisionWarning 0;
BA_ "GenSigSNA" SG_ 905 DAS_longCollisionWarning "15";
BA_ "Confidence" SG_ 905 DAS_status2Counter 0;
BA_ "Confidence" SG_ 905 DAS_status2Checksum 0;
BA_ "Confidence" SG_ 586 DAS_autosteerVehiclesUsage 0;
BA_ "Confidence" SG_ 586 DAS_autosteerHPPUsage 0;
BA_ "Confidence" SG_ 586 DAS_autosteerNavigationUsage 0;
BA_ "Confidence" SG_ 586 DAS_autosteerModelUsage 0;
BA_ "Confidence" SG_ 586 DAS_autosteerBottsDotsUsage 0;
BA_ "Confidence" SG_ 586 DAS_offsetSide 0;
BA_ "Confidence" SG_ 586 DAS_roadSurfaceType 0;
BA_ "GenSigSNA" SG_ 586 DAS_roadSurfaceType "0";
BA_ "Confidence" SG_ 586 DAS_autosteerHealthAnomalyLevel 0;
BA_ "Confidence" SG_ 586 DAS_autosteerHealthState 0;
BA_ "Confidence" SG_ 586 DAS_lastLinePreferenceReason 0;
BA_ "Confidence" SG_ 586 DAS_plannerState 0;
BA_ "Confidence" SG_ 586 DAS_lastAutosteerAbortReason 0;
BA_ "Confidence" SG_ 586 DAS_devAppInterfaceEnabled 0;
BA_ "Confidence" SG_ 586 DAS_navAvailable 0;
BA_ "Confidence" SG_ 586 DAS_navDistance 0;
BA_ "Confidence" SG_ 586 DAS_accSmartSpeedActive 0;
BA_ "Confidence" SG_ 586 DAS_accSmartSpeedState 0;
BA_ "GenSigSNA" SG_ 586 DAS_accSmartSpeedState "7";
BA_ "Confidence" SG_ 586 DAS_ulcInProgress 0;
BA_ "Confidence" SG_ 586 DAS_trafficAwareSetSpeedInUse 0;
BA_ "Confidence" SG_ 586 DAS_isaSystemState 0;
BA_ "Confidence" SG_ 586 DAS_behaviorType 0;
BA_ "Confidence" SG_ 586 DAS_ulcType 0;
BA_ "Confidence" SG_ 586 DAS_rearVehDetectedThisCycle 0;
BA_ "Confidence" SG_ 586 DAS_rearLeftVehDetectedCurrent 0;
BA_ "Confidence" SG_ 586 DAS_rearRightVehDetectedTrip 0;
BA_ "Confidence" SG_ 586 DAS_rearLeftVehDetectedTrip 0;
BA_ "Confidence" SG_ 977 EPAS3S_appliedAngleOffset 0;
BA_ "Confidence" SG_ 977 EPAS3S_calculatedAngleOffset 0;
BA_ "Confidence" SG_ 977 EPAS3S_resyncStatus 0;
BA_ "Confidence" SG_ 977 EPAS3S_pullDriftLongTermTrq 0;
BA_ "Confidence" SG_ 977 EPAS3S_pullDriftCompTrq 0;
BA_ "Confidence" SG_ 977 EPAS3S_learnedSCCMOffset 0;
BA_ "Confidence" SG_ 785 EPAS3S_infoIndex 1;
BA_ "Confidence" SG_ 785 EPAS3S_infoBuildType 0;
BA_ "Confidence" SG_ 785 EPAS3S_infoComponentID 0;
BA_ "Confidence" SG_ 785 EPAS3S_infoPcbaID 0;
BA_ "Confidence" SG_ 785 EPAS3S_infoAssemblyID 0;
BA_ "Confidence" SG_ 785 EPAS3S_infoUsageID 0;
BA_ "Confidence" SG_ 785 EPAS3S_infoApplicationCRC 0;
BA_ "Confidence" SG_ 785 EPAS3S_infoBootUdsProtoVersion 0;
BA_ "Confidence" SG_ 785 EPAS3S_infoBootloaderCRC 0;
BA_ "Confidence" SG_ 785 EPAS3S_infoSubcomponent2 0;
BA_ "Confidence" SG_ 880 EPAS3S_steeringRackForce 1;
BA_ "GenSigSNA" SG_ 880 EPAS3S_steeringRackForce "1023";
BA_ "Confidence" SG_ 880 EPAS3S_steeringFault 1;
BA_ "Confidence" SG_ 880 EPAS3S_steeringReduced 1;
BA_ "Confidence" SG_ 880 EPAS3S_internalSASQF 1;
BA_ "Confidence" SG_ 880 EPAS3S_currentTuneMode 1;
BA_ "Confidence" SG_ 880 EPAS3S_torsionBarTorque 1;
BA_ "GenSigSNA" SG_ 880 EPAS3S_torsionBarTorque "4095";
BA_ "Confidence" SG_ 880 EPAS3S_eacErrorCode 1;
BA_ "GenSigSNA" SG_ 880 EPAS3S_eacErrorCode "15";
BA_ "Confidence" SG_ 880 EPAS3S_internalSAS 1;
BA_ "Confidence" SG_ 880 EPAS3S_handsOnLevel 1;
BA_ "Confidence" SG_ 880 EPAS3S_driverlessState 1;
BA_ "Confidence" SG_ 880 EPAS3S_eacStatus 1;
BA_ "Confidence" SG_ 805 ESP_infoIndex 1;
BA_ "Confidence" SG_ 805 ESP_infoBuildType 0;
BA_ "Confidence" SG_ 805 ESP_infoComponentID 0;
BA_ "Confidence" SG_ 805 ESP_infoPcbaID 0;
BA_ "Confidence" SG_ 805 ESP_infoAssemblyID 0;
BA_ "Confidence" SG_ 805 ESP_infoUsageID 0;
BA_ "Confidence" SG_ 805 ESP_infoSubUsageID 0;
BA_ "Confidence" SG_ 805 ESP_infoApplicationCRC 1;
BA_ "Confidence" SG_ 805 ESP_infoVehicleVariant 0;
BA_ "Confidence" SG_ 805 ESP_infoSubcomponent1 0;
BA_ "Confidence" SG_ 805 ESP_infoBootUdsProtoVersion 0;
BA_ "Confidence" SG_ 805 ESP_infoBootloaderCRC 0;
BA_ "Confidence" SG_ 805 ESP_infoVariantCRC 1;
BA_ "Confidence" SG_ 813 IBST_infoIndex 1;
BA_ "Confidence" SG_ 813 IBST_infoBuildType 0;
BA_ "Confidence" SG_ 813 IBST_infoPcbaID 0;
BA_ "Confidence" SG_ 813 IBST_infoAssemblyID 0;
BA_ "Confidence" SG_ 813 IBST_infoUsageID 0;
BA_ "Confidence" SG_ 813 IBST_infoSubUsageID 0;
BA_ "Confidence" SG_ 813 IBST_infoApplicationCRC 0;
BA_ "Confidence" SG_ 813 IBST_infoBootUdsProtoVersion 0;
BA_ "Confidence" SG_ 813 IBST_infoBootloaderCRC 0;
BA_ "Confidence" SG_ 813 IBST_infoVariantCRC 0;
BA_ "Confidence" SG_ 806 PARK_infoIndex 1;
BA_ "Confidence" SG_ 806 PARK_infoBuildType 0;
BA_ "Confidence" SG_ 806 PARK_infoComponentID 0;
BA_ "Confidence" SG_ 806 PARK_infoPcbaID 0;
BA_ "Confidence" SG_ 806 PARK_infoAssemblyID 0;
BA_ "Confidence" SG_ 806 PARK_infoUsageID 0;
BA_ "Confidence" SG_ 806 PARK_infoApplicationCRC 0;
BA_ "Confidence" SG_ 806 PARK_infoBootUdsProtoVersion 0;
BA_ "Confidence" SG_ 806 PARK_infoBootloaderCRC 0;
BA_ "Confidence" SG_ 846 PARK_frontLeftMiddleRawDistData 0;
BA_ "GenSigSNA" SG_ 846 PARK_frontLeftMiddleRawDistData "255";
BA_ "Confidence" SG_ 846 PARK_frontMiddleRawDistData 0;
BA_ "GenSigSNA" SG_ 846 PARK_frontMiddleRawDistData "255";
BA_ "Confidence" SG_ 846 PARK_frontRightMiddleRawDistData 0;
BA_ "GenSigSNA" SG_ 846 PARK_frontRightMiddleRawDistData "255";
BA_ "Confidence" SG_ 846 PARK_pasFrontMiddleCounter 0;
BA_ "Confidence" SG_ 846 PARK_pasFrontMiddleChecksum 0;
BA_ "Confidence" SG_ 926 PARK_rightSideFrontRawDistData 0;
BA_ "GenSigSNA" SG_ 926 PARK_rightSideFrontRawDistData "255";
BA_ "Confidence" SG_ 926 PARK_rightSideRearRawDistData 0;
BA_ "GenSigSNA" SG_ 926 PARK_rightSideRearRawDistData "255";
BA_ "Confidence" SG_ 926 PARK_leftSideFrontRawDistData 0;
BA_ "GenSigSNA" SG_ 926 PARK_leftSideFrontRawDistData "255";
BA_ "Confidence" SG_ 926 PARK_leftSideRearRawDistData 0;
BA_ "GenSigSNA" SG_ 926 PARK_leftSideRearRawDistData "255";
BA_ "Confidence" SG_ 926 PARK_pasSidesCounter 0;
BA_ "Confidence" SG_ 926 PARK_pasSidesChecksum 0;
BA_ "Confidence" SG_ 606 PARK_pscEnvSlotType 1;
BA_ "Confidence" SG_ 606 PARK_pscLeftParallelObj1X 0;
BA_ "GenSigSNA" SG_ 606 PARK_pscLeftParallelObj1X "2047";
BA_ "Confidence" SG_ 606 PARK_pscLeftParallelObj1Y 0;
BA_ "GenSigSNA" SG_ 606 PARK_pscLeftParallelObj1Y "2047";
BA_ "Confidence" SG_ 606 PARK_pscLeftParallelObj1Alpha 0;
BA_ "GenSigSNA" SG_ 606 PARK_pscLeftParallelObj1Alpha "127";
BA_ "Confidence" SG_ 606 PARK_pscLeftParallelObj2Y 0;
BA_ "GenSigSNA" SG_ 606 PARK_pscLeftParallelObj2Y "2047";
BA_ "Confidence" SG_ 606 PARK_pscLeftParallelObj2X 0;
BA_ "GenSigSNA" SG_ 606 PARK_pscLeftParallelObj2X "2047";
BA_ "Confidence" SG_ 606 PARK_pscLeftParallelObj2Alpha 0;
BA_ "GenSigSNA" SG_ 606 PARK_pscLeftParallelObj2Alpha "127";
BA_ "Confidence" SG_ 606 PARK_pscLeftCrossObj1X 0;
BA_ "GenSigSNA" SG_ 606 PARK_pscLeftCrossObj1X "2047";
BA_ "Confidence" SG_ 606 PARK_pscLeftCrossObj1Y 0;
BA_ "GenSigSNA" SG_ 606 PARK_pscLeftCrossObj1Y "2047";
BA_ "Confidence" SG_ 606 PARK_pscLeftCrossObj1Alpha 0;
BA_ "GenSigSNA" SG_ 606 PARK_pscLeftCrossObj1Alpha "127";
BA_ "Confidence" SG_ 606 PARK_pscLeftCrossObj2Y 0;
BA_ "GenSigSNA" SG_ 606 PARK_pscLeftCrossObj2Y "2047";
BA_ "Confidence" SG_ 606 PARK_pscLeftCrossObj2X 0;
BA_ "GenSigSNA" SG_ 606 PARK_pscLeftCrossObj2X "2047";
BA_ "Confidence" SG_ 606 PARK_pscLeftCrossObj2Alpha 0;
BA_ "GenSigSNA" SG_ 606 PARK_pscLeftCrossObj2Alpha "127";
BA_ "Confidence" SG_ 606 PARK_pscRightParallelObj1X 0;
BA_ "GenSigSNA" SG_ 606 PARK_pscRightParallelObj1X "2047";
BA_ "Confidence" SG_ 606 PARK_pscRightParallelObj1Y 0;
BA_ "GenSigSNA" SG_ 606 PARK_pscRightParallelObj1Y "2047";
BA_ "Confidence" SG_ 606 PARK_pscRightParallelObj1Alpha 0;
BA_ "GenSigSNA" SG_ 606 PARK_pscRightParallelObj1Alpha "127";
BA_ "Confidence" SG_ 606 PARK_pscRightParallelObj2Y 0;
BA_ "GenSigSNA" SG_ 606 PARK_pscRightParallelObj2Y "2047";
BA_ "Confidence" SG_ 606 PARK_pscRightParallelObj2X 0;
BA_ "GenSigSNA" SG_ 606 PARK_pscRightParallelObj2X "2047";
BA_ "Confidence" SG_ 606 PARK_pscRightParallelObj2Alpha 0;
BA_ "GenSigSNA" SG_ 606 PARK_pscRightParallelObj2Alpha "127";
BA_ "Confidence" SG_ 606 PARK_pscRightCrossObj1X 0;
BA_ "GenSigSNA" SG_ 606 PARK_pscRightCrossObj1X "2047";
BA_ "Confidence" SG_ 606 PARK_pscRightCrossObj1Y 0;
BA_ "GenSigSNA" SG_ 606 PARK_pscRightCrossObj1Y "2047";
BA_ "Confidence" SG_ 606 PARK_pscRightCrossObj1Alpha 0;
BA_ "GenSigSNA" SG_ 606 PARK_pscRightCrossObj1Alpha "127";
BA_ "Confidence" SG_ 606 PARK_pscRightCrossObj2Y 0;
BA_ "GenSigSNA" SG_ 606 PARK_pscRightCrossObj2Y "2047";
BA_ "Confidence" SG_ 606 PARK_pscRightCrossObj2X 0;
BA_ "GenSigSNA" SG_ 606 PARK_pscRightCrossObj2X "2047";
BA_ "Confidence" SG_ 606 PARK_pscRightCrossObj2Alpha 0;
BA_ "GenSigSNA" SG_ 606 PARK_pscRightCrossObj2Alpha "127";
BA_ "Confidence" SG_ 542 PARK_pscParkStatus 0;
BA_ "GenSigSNA" SG_ 542 PARK_pscParkStatus "7";
BA_ "Confidence" SG_ 542 PARK_pscParkAbortReason 0;
BA_ "GenSigSNA" SG_ 542 PARK_pscParkAbortReason "31";
BA_ "Confidence" SG_ 542 PARK_pscParallelSpace 0;
BA_ "Confidence" SG_ 542 PARK_pscCrossSpace 0;
BA_ "Confidence" SG_ 542 PARK_pscParallelRightParkable 0;
BA_ "GenSigSNA" SG_ 542 PARK_pscParallelRightParkable "3";
BA_ "Confidence" SG_ 542 PARK_pscParallelLeftParkable 0;
BA_ "GenSigSNA" SG_ 542 PARK_pscParallelLeftParkable "3";
BA_ "Confidence" SG_ 542 PARK_pscCrossRightParkable 0;
BA_ "GenSigSNA" SG_ 542 PARK_pscCrossRightParkable "3";
BA_ "Confidence" SG_ 542 PARK_pscMaxVelocity 0;
BA_ "GenSigSNA" SG_ 542 PARK_pscMaxVelocity "63";
BA_ "Confidence" SG_ 542 PARK_pscCrossLeftParkable 0;
BA_ "GenSigSNA" SG_ 542 PARK_pscCrossLeftParkable "3";
BA_ "Confidence" SG_ 542 PARK_pscParkInstruction 0;
BA_ "GenSigSNA" SG_ 542 PARK_pscParkInstruction "7";
BA_ "Confidence" SG_ 542 PARK_pscManeuverDistance 0;
BA_ "GenSigSNA" SG_ 542 PARK_pscManeuverDistance "2047";
BA_ "Confidence" SG_ 542 PARK_pscAngleActive 0;
BA_ "Confidence" SG_ 542 PARK_pscAngleRequest 0;
BA_ "Confidence" SG_ 542 PARK_pscStatusCounter 0;
BA_ "Confidence" SG_ 542 PARK_pscStatusChecksum 0;
BA_ "Confidence" SG_ 590 PARK_pscVehSlotType 1;
BA_ "Confidence" SG_ 590 PARK_pscLeftParallelVehX 0;
BA_ "GenSigSNA" SG_ 590 PARK_pscLeftParallelVehX "2047";
BA_ "Confidence" SG_ 590 PARK_pscLeftParallelVehY 0;
BA_ "GenSigSNA" SG_ 590 PARK_pscLeftParallelVehY "2047";
BA_ "Confidence" SG_ 590 PARK_pscLeftParallelPsi 0;
BA_ "GenSigSNA" SG_ 590 PARK_pscLeftParallelPsi "8191";
BA_ "Confidence" SG_ 590 PARK_pscLeftParallelSizeX 0;
BA_ "GenSigSNA" SG_ 590 PARK_pscLeftParallelSizeX "255";
BA_ "Confidence" SG_ 590 PARK_pscLeftParallelSizeY 0;
BA_ "GenSigSNA" SG_ 590 PARK_pscLeftParallelSizeY "255";
BA_ "Confidence" SG_ 590 PARK_pscLeftCrossVehX 0;
BA_ "GenSigSNA" SG_ 590 PARK_pscLeftCrossVehX "2047";
BA_ "Confidence" SG_ 590 PARK_pscLeftCrossVehY 0;
BA_ "GenSigSNA" SG_ 590 PARK_pscLeftCrossVehY "2047";
BA_ "Confidence" SG_ 590 PARK_pscLeftCrossPsi 0;
BA_ "GenSigSNA" SG_ 590 PARK_pscLeftCrossPsi "8191";
BA_ "Confidence" SG_ 590 PARK_pscLeftCrossSizeX 0;
BA_ "GenSigSNA" SG_ 590 PARK_pscLeftCrossSizeX "255";
BA_ "Confidence" SG_ 590 PARK_pscLeftCrossSizeY 0;
BA_ "GenSigSNA" SG_ 590 PARK_pscLeftCrossSizeY "255";
BA_ "Confidence" SG_ 590 PARK_pscRightParallelVehX 0;
BA_ "GenSigSNA" SG_ 590 PARK_pscRightParallelVehX "2047";
BA_ "Confidence" SG_ 590 PARK_pscRightParallelVehY 0;
BA_ "GenSigSNA" SG_ 590 PARK_pscRightParallelVehY "2047";
BA_ "Confidence" SG_ 590 PARK_pscRightParallelPsi 0;
BA_ "GenSigSNA" SG_ 590 PARK_pscRightParallelPsi "8191";
BA_ "Confidence" SG_ 590 PARK_pscRightParallelSizeX 0;
BA_ "GenSigSNA" SG_ 590 PARK_pscRightParallelSizeX "255";
BA_ "Confidence" SG_ 590 PARK_pscRightParallelSizeY 0;
BA_ "GenSigSNA" SG_ 590 PARK_pscRightParallelSizeY "255";
BA_ "Confidence" SG_ 590 PARK_pscRightCrossVehX 0;
BA_ "GenSigSNA" SG_ 590 PARK_pscRightCrossVehX "2047";
BA_ "Confidence" SG_ 590 PARK_pscRightCrossVehY 0;
BA_ "GenSigSNA" SG_ 590 PARK_pscRightCrossVehY "2047";
BA_ "Confidence" SG_ 590 PARK_pscRightCrossPsi 0;
BA_ "GenSigSNA" SG_ 590 PARK_pscRightCrossPsi "8191";
BA_ "Confidence" SG_ 590 PARK_pscRightCrossSizeX 0;
BA_ "GenSigSNA" SG_ 590 PARK_pscRightCrossSizeX "255";
BA_ "Confidence" SG_ 590 PARK_pscRightCrossSizeY 0;
BA_ "GenSigSNA" SG_ 590 PARK_pscRightCrossSizeY "255";
BA_ "Confidence" SG_ 526 PARK_sdiSensor1RawDistData 0;
BA_ "GenSigSNA" SG_ 526 PARK_sdiSensor1RawDistData "511";
BA_ "Confidence" SG_ 526 PARK_sdiSensor2RawDistData 0;
BA_ "GenSigSNA" SG_ 526 PARK_sdiSensor2RawDistData "511";
BA_ "Confidence" SG_ 526 PARK_sdiSensor3RawDistData 0;
BA_ "GenSigSNA" SG_ 526 PARK_sdiSensor3RawDistData "511";
BA_ "Confidence" SG_ 526 PARK_sdiSensor4RawDistData 0;
BA_ "GenSigSNA" SG_ 526 PARK_sdiSensor4RawDistData "511";
BA_ "Confidence" SG_ 526 PARK_sdiSensor5RawDistData 0;
BA_ "GenSigSNA" SG_ 526 PARK_sdiSensor5RawDistData "511";
BA_ "Confidence" SG_ 526 PARK_sdiSensor6RawDistData 0;
BA_ "GenSigSNA" SG_ 526 PARK_sdiSensor6RawDistData "511";
BA_ "Confidence" SG_ 526 PARK_sdiFrontCounter 0;
BA_ "Confidence" SG_ 526 PARK_sdiFrontChecksum 0;
BA_ "Confidence" SG_ 558 PARK_sdiSensor7RawDistData 0;
BA_ "GenSigSNA" SG_ 558 PARK_sdiSensor7RawDistData "511";
BA_ "Confidence" SG_ 558 PARK_sdiSensor8RawDistData 0;
BA_ "GenSigSNA" SG_ 558 PARK_sdiSensor8RawDistData "511";
BA_ "Confidence" SG_ 558 PARK_sdiSensor9RawDistData 0;
BA_ "GenSigSNA" SG_ 558 PARK_sdiSensor9RawDistData "511";
BA_ "Confidence" SG_ 558 PARK_sdiSensor10RawDistData 0;
BA_ "GenSigSNA" SG_ 558 PARK_sdiSensor10RawDistData "511";
BA_ "Confidence" SG_ 558 PARK_sdiSensor11RawDistData 0;
BA_ "GenSigSNA" SG_ 558 PARK_sdiSensor11RawDistData "511";
BA_ "Confidence" SG_ 558 PARK_sdiSensor12RawDistData 0;
BA_ "GenSigSNA" SG_ 558 PARK_sdiSensor12RawDistData "511";
BA_ "Confidence" SG_ 558 PARK_sdiRearCounter 0;
BA_ "Confidence" SG_ 558 PARK_sdiRearChecksum 0;
BA_ "Confidence" SG_ 814 PARK_frontRightSensorState 0;
BA_ "GenSigSNA" SG_ 814 PARK_frontRightSensorState "3";
BA_ "Confidence" SG_ 814 PARK_frontRightMiddleSensorState 0;
BA_ "GenSigSNA" SG_ 814 PARK_frontRightMiddleSensorState "3";
BA_ "Confidence" SG_ 814 PARK_frontLeftMiddleSensorState 0;
BA_ "GenSigSNA" SG_ 814 PARK_frontLeftMiddleSensorState "3";
BA_ "Confidence" SG_ 814 PARK_frontLeftSensorState 0;
BA_ "GenSigSNA" SG_ 814 PARK_frontLeftSensorState "3";
BA_ "Confidence" SG_ 814 PARK_frontLeftRawDistData 0;
BA_ "GenSigSNA" SG_ 814 PARK_frontLeftRawDistData "255";
BA_ "Confidence" SG_ 814 PARK_frontRightRawDistData 0;
BA_ "GenSigSNA" SG_ 814 PARK_frontRightRawDistData "255";
BA_ "Confidence" SG_ 814 PARK_systemStatusFront 0;
BA_ "GenSigSNA" SG_ 814 PARK_systemStatusFront "3";
BA_ "Confidence" SG_ 814 PARK_frontDtcPresent 0;
BA_ "GenSigSNA" SG_ 814 PARK_frontDtcPresent "3";
BA_ "Confidence" SG_ 814 PARK_sensorStatusFrontCounter 0;
BA_ "Confidence" SG_ 814 PARK_sensorStatusFrontChecksum 0;
BA_ "Confidence" SG_ 830 PARK_rearRightSensorState 0;
BA_ "GenSigSNA" SG_ 830 PARK_rearRightSensorState "3";
BA_ "Confidence" SG_ 830 PARK_rearRightMiddleSensorState 0;
BA_ "GenSigSNA" SG_ 830 PARK_rearRightMiddleSensorState "3";
BA_ "Confidence" SG_ 830 PARK_rearLeftMiddleSensorState 0;
BA_ "GenSigSNA" SG_ 830 PARK_rearLeftMiddleSensorState "3";
BA_ "Confidence" SG_ 830 PARK_rearLeftSensorState 0;
BA_ "GenSigSNA" SG_ 830 PARK_rearLeftSensorState "3";
BA_ "Confidence" SG_ 830 PARK_rearLeftRawDistData 0;
BA_ "GenSigSNA" SG_ 830 PARK_rearLeftRawDistData "255";
BA_ "Confidence" SG_ 830 PARK_rearRightRawDistData 0;
BA_ "GenSigSNA" SG_ 830 PARK_rearRightRawDistData "255";
BA_ "Confidence" SG_ 830 PARK_systemStatusRear 0;
BA_ "GenSigSNA" SG_ 830 PARK_systemStatusRear "3";
BA_ "Confidence" SG_ 830 PARK_rearDtcPresent 0;
BA_ "GenSigSNA" SG_ 830 PARK_rearDtcPresent "3";
BA_ "Confidence" SG_ 830 PARK_sensorStatusRearCounter 0;
BA_ "Confidence" SG_ 830 PARK_sensorStatusRearChecksum 0;
BA_ "Confidence" SG_ 798 PARK_status 0;
BA_ "GenSigSNA" SG_ 798 PARK_status "3";
BA_ "Confidence" SG_ 798 PARK_serviceRequest 0;
BA_ "GenSigSNA" SG_ 798 PARK_serviceRequest "3";
BA_ "Confidence" SG_ 798 PARK_systemDtcPresent 0;
BA_ "GenSigSNA" SG_ 798 PARK_systemDtcPresent "3";
BA_ "Confidence" SG_ 798 PARK_statusCounter 0;
BA_ "Confidence" SG_ 798 PARK_statusChecksum 0;
BA_ "Confidence" SG_ 798 PARK_majorVersion 0;
BA_ "GenSigSNA" SG_ 798 PARK_majorVersion "255";
BA_ "Confidence" SG_ 798 PARK_minorVersion 0;
BA_ "GenSigSNA" SG_ 798 PARK_minorVersion "255";
BA_ "Confidence" SG_ 798 PARK_subMinorVersion 0;
BA_ "GenSigSNA" SG_ 798 PARK_subMinorVersion "255";
BA_ "Confidence" SG_ 782 PARK_frontSVACharID 0;
BA_ "Confidence" SG_ 782 PARK_pscRightCurbType 0;
BA_ "Confidence" SG_ 782 PARK_rearSVACharID 0;
BA_ "Confidence" SG_ 782 PARK_pscLeftCurbType 0;
BA_ "Confidence" SG_ 782 PARK_autoCalComplete 0;
BA_ "Confidence" SG_ 782 PARK_geometryType 0;
BA_ "Confidence" SG_ 782 PARK_tireFitment 0;
BA_ "GenSigSNA" SG_ 782 PARK_tireFitment "3";
BA_ "Confidence" SG_ 782 PARK_rackDetected 0;
BA_ "GenSigSNA" SG_ 782 PARK_rackDetected "3";
BA_ "Confidence" SG_ 782 PARK_sdiActive 0;
BA_ "Confidence" SG_ 782 PARK_sdiNoise 0;
BA_ "GenSigSNA" SG_ 782 PARK_sdiNoise "3";
BA_ "Confidence" SG_ 782 PARK_sdiBlindSpotRight 0;
BA_ "GenSigSNA" SG_ 782 PARK_sdiBlindSpotRight "3";
BA_ "Confidence" SG_ 782 PARK_sdiBlindSpotLeft 0;
BA_ "GenSigSNA" SG_ 782 PARK_sdiBlindSpotLeft "3";
BA_ "Confidence" SG_ 782 PARK_sensorType 0;
BA_ "GenSigSNA" SG_ 782 PARK_sensorType "3";
BA_ "Confidence" SG_ 782 PARK_status2Counter 0;
BA_ "Confidence" SG_ 782 PARK_status2Checksum 0;
BA_ "Confidence" SG_ 1329 RADC_infoIndex 1;
BA_ "Confidence" SG_ 1329 RADC_infoBuildType 0;
BA_ "Confidence" SG_ 1329 RADC_infoBuildConfigID 0;
BA_ "Confidence" SG_ 1329 RADC_infoHardwareID 0;
BA_ "Confidence" SG_ 1329 RADC_infoComponentID 0;
BA_ "Confidence" SG_ 1329 RADC_infoPcbaID 0;
BA_ "Confidence" SG_ 1329 RADC_infoAssemblyID 0;
BA_ "Confidence" SG_ 1329 RADC_infoUsageID 0;
BA_ "Confidence" SG_ 1329 RADC_infoSubUsageID 0;
BA_ "Confidence" SG_ 1329 RADC_infoApplicationCRC 0;
BA_ "Confidence" SG_ 1329 RADC_infoPlatformType 0;
BA_ "Confidence" SG_ 1329 RADC_infoMajorVersion 0;
BA_ "Confidence" SG_ 1329 RADC_infoBranchOrigin 0;
BA_ "Confidence" SG_ 1329 RADC_infoMaturity 0;
BA_ "Confidence" SG_ 1329 RADC_infoHardwareRevision 0;
BA_ "Confidence" SG_ 1329 RADC_infoBootUdsProtoVersion 0;
BA_ "Confidence" SG_ 1329 RADC_infoBootloaderCRC 0;
BA_ "Confidence" SG_ 257 RCM_yawRate 0;
BA_ "GenSigSNA" SG_ 257 RCM_yawRate "32768";
BA_ "Confidence" SG_ 257 RCM_pitchRate 0;
BA_ "GenSigSNA" SG_ 257 RCM_pitchRate "16384";
BA_ "Confidence" SG_ 257 RCM_rollRate 0;
BA_ "GenSigSNA" SG_ 257 RCM_rollRate "16384";
BA_ "Confidence" SG_ 257 RCM_rollRateQF 0;
BA_ "Confidence" SG_ 257 RCM_yawRateQF 0;
BA_ "Confidence" SG_ 257 RCM_pitchRateQF 0;
BA_ "Confidence" SG_ 257 RCM_inertial1Counter 0;
BA_ "Confidence" SG_ 257 RCM_inertial1Checksum 0;
BA_ "Confidence" SG_ 273 RCM_longitudinalAccel 0;
BA_ "GenSigSNA" SG_ 273 RCM_longitudinalAccel "32768";
BA_ "Confidence" SG_ 273 RCM_lateralAccel 0;
BA_ "GenSigSNA" SG_ 273 RCM_lateralAccel "32768";
BA_ "Confidence" SG_ 273 RCM_verticalAccel 0;
BA_ "GenSigSNA" SG_ 273 RCM_verticalAccel "32768";
BA_ "Confidence" SG_ 273 RCM_longitudinalAccelQF 0;
BA_ "Confidence" SG_ 273 RCM_lateralAccelQF 0;
BA_ "Confidence" SG_ 273 RCM_verticalAccelQF 0;
BA_ "Confidence" SG_ 273 RCM_CGTranslationFault 0;
BA_ "Confidence" SG_ 273 RCM_inertial2Counter 0;
BA_ "Confidence" SG_ 273 RCM_inertial2Checksum 0;
BA_ "Confidence" SG_ 849 RCM_infoIndex 1;
BA_ "Confidence" SG_ 849 RCM_infoBuildType 0;
BA_ "Confidence" SG_ 849 RCM_infoComponentID 0;
BA_ "Confidence" SG_ 849 RCM_infoPcbaID 0;
BA_ "Confidence" SG_ 849 RCM_infoAssemblyID 0;
BA_ "Confidence" SG_ 849 RCM_infoUsageID 0;
BA_ "Confidence" SG_ 849 RCM_infoApplicationCRC 0;
BA_ "Confidence" SG_ 849 RCM_infoBootUdsProtoVersion 0;
BA_ "Confidence" SG_ 849 RCM_infoBootloaderCRC 0;
BA_ "Confidence" SG_ 849 RCM_infoAlgoCalID 0;
BA_ "Confidence" SG_ 849 RCM_infoVariantCRC 0;
BA_ "Confidence" SG_ 529 RCM_statusChecksum 0;
BA_ "Confidence" SG_ 529 RCM_statusCounter 0;
BA_ "Confidence" SG_ 529 RCM_armStatus 0;
BA_ "GenSigSNA" SG_ 529 RCM_armStatus "3";
BA_ "Confidence" SG_ 529 RCM_warningIndicatorState 0;
BA_ "GenSigSNA" SG_ 529 RCM_warningIndicatorState "3";
BA_ "Confidence" SG_ 529 RCM_passAirbagIndicatorRequest 0;
BA_ "GenSigSNA" SG_ 529 RCM_passAirbagIndicatorRequest "3";
BA_ "Confidence" SG_ 529 RCM_airbagCutoffStatus 0;
BA_ "GenSigSNA" SG_ 529 RCM_airbagCutoffStatus "3";
BA_ "Confidence" SG_ 529 RCM_alrSwitchStatus 0;
BA_ "GenSigSNA" SG_ 529 RCM_alrSwitchStatus "3";
BA_ "Confidence" SG_ 529 RCM_vinLearnFlag 0;
BA_ "GenSigSNA" SG_ 529 RCM_vinLearnFlag "3";
BA_ "Confidence" SG_ 529 RCM_seatTrackPositionDrvr 0;
BA_ "GenSigSNA" SG_ 529 RCM_seatTrackPositionDrvr "3";
BA_ "Confidence" SG_ 529 RCM_seatTrackPositionPass 0;
BA_ "GenSigSNA" SG_ 529 RCM_seatTrackPositionPass "3";
BA_ "Confidence" SG_ 529 RCM_edr1State 0;
BA_ "Confidence" SG_ 529 RCM_edr2State 0;
BA_ "Confidence" SG_ 529 RCM_keepPowerReason 0;
BA_ "GenSigSNA" SG_ 529 RCM_keepPowerReason "8";
BA_ "Confidence" SG_ 529 RCM_imuOffsetLearnState 0;
BA_ "Confidence" SG_ 529 RCM_edr3State 0;
BA_ "Confidence" SG_ 529 RCM_driverOrientationInitStatus 0;
BA_ "GenSigSNA" SG_ 529 RCM_driverOrientationInitStatus "7";
BA_ "Confidence" SG_ 529 RCM_occupantClassificationSource 0;
BA_ "Confidence" SG_ 529 RCM_pedProEDR1State 0;
BA_ "Confidence" SG_ 529 RCM_pedProEDR2State 0;
BA_ "Confidence" SG_ 879 TPMS_c_globalHardWarning 0;
BA_ "Confidence" SG_ 879 TPMS_c_globalSoftWarning 0;
BA_ "Confidence" SG_ 879 TPMS_systemMalfunction 0;
BA_ "Confidence" SG_ 879 TPMS_WA_version 0;
BA_ "Confidence" SG_ 879 TPMS_globalDeltaPressure 0;
BA_ "Confidence" SG_ 879 TPMS_newSensorLearnt 0;
BA_ "Confidence" SG_ 879 TPMS_softWarningRR 0;
BA_ "Confidence" SG_ 879 TPMS_hardWarningRR 0;
BA_ "Confidence" SG_ 879 TPMS_softWarningRL 0;
BA_ "Confidence" SG_ 879 TPMS_hardWarningRL 0;
BA_ "Confidence" SG_ 879 TPMS_softWarningFR 0;
BA_ "Confidence" SG_ 879 TPMS_hardWarningFR 0;
BA_ "Confidence" SG_ 879 TPMS_softWarningFL 0;
BA_ "Confidence" SG_ 879 TPMS_hardWarningFL 0;
BA_ "Confidence" SG_ 879 TPMS_learningStatus 0;
BA_ "Confidence" SG_ 879 TPMS_localisationStatus 0;
BA_ "Confidence" SG_ 879 TPMS_deltaPressWarningFL 0;
BA_ "Confidence" SG_ 879 TPMS_deltaPressWarningFR 0;
BA_ "Confidence" SG_ 879 TPMS_deltaPressWarningRL 0;
BA_ "Confidence" SG_ 879 TPMS_deltaPressWarningRR 0;
BA_ "Confidence" SG_ 879 TPMS_sensorNoResponseFL 0;
BA_ "Confidence" SG_ 879 TPMS_sensorNoResponseFR 0;
BA_ "Confidence" SG_ 879 TPMS_sensorNoResponseRL 0;
BA_ "Confidence" SG_ 879 TPMS_sensorNoResponseRR 0;
BA_ "Confidence" SG_ 879 TPMS_sensorThermShutdownFL 0;
BA_ "Confidence" SG_ 879 TPMS_sensorThermShutdownFR 0;
BA_ "Confidence" SG_ 879 TPMS_sensorThermShutdownRL 0;
BA_ "Confidence" SG_ 879 TPMS_sensorThermShutdownRR 0;
BA_ "Confidence" SG_ 879 TPMS_sensorBatteryLowFL 0;
BA_ "Confidence" SG_ 879 TPMS_sensorBatteryLowFR 0;
BA_ "Confidence" SG_ 879 TPMS_sensorBatteryLowRL 0;
BA_ "Confidence" SG_ 879 TPMS_sensorBatteryLowRR 0;
BA_ "Confidence" SG_ 879 TPMS_sensorDefectiveFL 0;
BA_ "Confidence" SG_ 879 TPMS_sensorDefectiveFR 0;
BA_ "Confidence" SG_ 879 TPMS_sensorDefectiveRL 0;
BA_ "Confidence" SG_ 879 TPMS_sensorDefectiveRR 0;
BA_ "Confidence" SG_ 879 TPMS_ecuUnderVoltage 0;
BA_ "Confidence" SG_ 879 TPMS_ecuOverVoltage 0;
BA_ "Confidence" SG_ 879 TPMS_ecuRamRomNvMFail 0;
BA_ "Confidence" SG_ 879 TPMS_rfReceiverFail 0;
BA_ "Confidence" SG_ 879 TPMS_wheelPulseMissing 0;
BA_ "Confidence" SG_ 879 TPMS_vehicleSpeedFail 0;
BA_ "Confidence" SG_ 879 TPMS_externalTemperatureFail 0;
BA_ "Confidence" SG_ 879 TPMS_eolNotCompleted 0;
BA_ "Confidence" SG_ 879 TPMS_rcpFront 0;
BA_ "Confidence" SG_ 879 TPMS_rcpRear 0;
BA_ "Confidence" SG_ 799 TPMS_pressureFL 0;
BA_ "GenSigSNA" SG_ 799 TPMS_pressureFL "255";
BA_ "Confidence" SG_ 799 TPMS_temperatureFL 0;
BA_ "GenSigSNA" SG_ 799 TPMS_temperatureFL "255";
BA_ "Confidence" SG_ 799 TPMS_pressureFR 0;
BA_ "GenSigSNA" SG_ 799 TPMS_pressureFR "255";
BA_ "Confidence" SG_ 799 TPMS_temperatureFR 0;
BA_ "GenSigSNA" SG_ 799 TPMS_temperatureFR "255";
BA_ "Confidence" SG_ 799 TPMS_pressureRL 0;
BA_ "GenSigSNA" SG_ 799 TPMS_pressureRL "255";
BA_ "Confidence" SG_ 799 TPMS_temperatureRL 0;
BA_ "GenSigSNA" SG_ 799 TPMS_temperatureRL "255";
BA_ "Confidence" SG_ 799 TPMS_pressureRR 0;
BA_ "GenSigSNA" SG_ 799 TPMS_pressureRR "255";
BA_ "Confidence" SG_ 799 TPMS_temperatureRR 0;
BA_ "GenSigSNA" SG_ 799 TPMS_temperatureRR "255";
BA_ "Confidence" SG_ 1519 TPMS_infoIndex 1;
BA_ "Confidence" SG_ 1519 TPMS_infoComponentID 0;
BA_ "Confidence" SG_ 1519 TPMS_infoPcbaID 0;
BA_ "Confidence" SG_ 1519 TPMS_infoAssemblyID 0;
BA_ "Confidence" SG_ 1519 TPMS_infoUsageID 0;
BA_ "Confidence" SG_ 1519 TPMS_infoApplicationCRC 0;
BA_ "Confidence" SG_ 1519 TPMS_infoBootUdsProtoVersion 0;
BA_ "Confidence" SG_ 1519 TPMS_infoBootloaderCRC 0;
BA_ "Confidence" SG_ 850 TRCM_infoIndex 1;
BA_ "Confidence" SG_ 850 TRCM_infoBuildType 0;
BA_ "Confidence" SG_ 850 TRCM_infoBuildConfigId 0;
BA_ "Confidence" SG_ 850 TRCM_infoHardwareId 0;
BA_ "Confidence" SG_ 850 TRCM_infoComponentId 0;
BA_ "Confidence" SG_ 850 TRCM_infoPcbaId 0;
BA_ "Confidence" SG_ 850 TRCM_infoAssemblyId 0;
BA_ "GenSigSNA" SG_ 850 TRCM_infoAssemblyId "255";
BA_ "Confidence" SG_ 850 TRCM_infoUsageId 0;
BA_ "Confidence" SG_ 850 TRCM_infoSubUsageId 0;
BA_ "Confidence" SG_ 850 TRCM_infoAppCrc 0;
BA_ "Confidence" SG_ 850 TRCM_infoAppGitHash 0;
BA_ "Confidence" SG_ 850 TRCM_infoBootGitHash 0;
BA_ "Confidence" SG_ 850 TRCM_infoBootUdsProtoVersion 0;
BA_ "Confidence" SG_ 850 TRCM_infoBootCrc 0;
BA_ "Confidence" SG_ 1021 UI_autopilotControlIndex 1;
BA_ "Confidence" SG_ 1021 UI_hovEnabled 0;
BA_ "Confidence" SG_ 1021 UI_smartSetSpeedOffset 0;
BA_ "Confidence" SG_ 1021 UI_smartSetSpeedOffsetType 0;
BA_ "Confidence" SG_ 1021 UI_fsdStopsControlEnabled 0;
BA_ "Confidence" SG_ 1021 UI_smartSetSpeed 0;
BA_ "Confidence" SG_ 1021 UI_automaticSetSpeedOffset 0;
BA_ "Confidence" SG_ 1021 UI_enableFullSelfDriving 0;
BA_ "Confidence" SG_ 1021 UI_hasFullSelfDriving 0;
BA_ "Confidence" SG_ 1021 UI_autosteerActivation 0;
BA_ "Confidence" SG_ 1021 UI_fsdBetaRequest 0;
BA_ "Confidence" SG_ 1021 UI_fullSelfDrivingSuspended 0;
BA_ "Confidence" SG_ 1021 UI_disableOptionalLaneChanges 0;
BA_ "Confidence" SG_ 1021 UI_applyADDWWarnings 0;
BA_ "Confidence" SG_ 1021 UI_selectableCameraRequest 0;
BA_ "GenSigSNA" SG_ 1021 UI_selectableCameraRequest "15";
BA_ "Confidence" SG_ 1021 UI_driverMonitorConfirmation 0;
BA_ "Confidence" SG_ 1021 UI_parkAssistUseVision 0;
BA_ "Confidence" SG_ 1021 UI_noStalkConfirmAlertHaptic 0;
BA_ "Confidence" SG_ 1021 UI_noStalkConfirmAlertChime 0;
BA_ "Confidence" SG_ 1021 UI_factorySummonEnable 0;
BA_ "Confidence" SG_ 1021 UI_enableCabinCamera 0;
BA_ "Confidence" SG_ 1021 UI_enableAutopilotStopWarning 0;
BA_ "Confidence" SG_ 1021 UI_enableVisionSpeedControl 0;
BA_ "Confidence" SG_ 1021 UI_enableTeslaAutopark 0;
BA_ "Confidence" SG_ 1021 UI_autoTurnSignalMode 0;
BA_ "Confidence" SG_ 1021 UI_enableCabinAudioRecording 0;
BA_ "Confidence" SG_ 1021 UI_autopilotDrivingProfile 0;
BA_ "Confidence" SG_ 659 UI_steeringTuneRequest 0;
BA_ "Confidence" SG_ 659 UI_tractionControlMode 0;
BA_ "Confidence" SG_ 659 UI_parkBrakeRequest 0;
BA_ "GenSigSNA" SG_ 659 UI_parkBrakeRequest "3";
BA_ "Confidence" SG_ 659 UI_winchModeRequest 0;
BA_ "Confidence" SG_ 659 UI_trailerMode 0;
BA_ "Confidence" SG_ 659 UI_accOvertakeEnable 0;
BA_ "GenSigSNA" SG_ 659 UI_accOvertakeEnable "3";
BA_ "Confidence" SG_ 659 UI_aebEnable 0;
BA_ "GenSigSNA" SG_ 659 UI_aebEnable "3";
BA_ "Confidence" SG_ 659 UI_aesEnable 0;
BA_ "GenSigSNA" SG_ 659 UI_aesEnable "3";
BA_ "Confidence" SG_ 659 UI_ahlbEnable 0;
BA_ "GenSigSNA" SG_ 659 UI_ahlbEnable "3";
BA_ "Confidence" SG_ 659 UI_autoLaneChangeEnable 0;
BA_ "GenSigSNA" SG_ 659 UI_autoLaneChangeEnable "3";
BA_ "Confidence" SG_ 659 UI_winchProxUserOverride 0;
BA_ "Confidence" SG_ 659 UI_autoParkRequest 0;
BA_ "GenSigSNA" SG_ 659 UI_autoParkRequest "15";
BA_ "Confidence" SG_ 659 UI_bsdEnable 0;
BA_ "GenSigSNA" SG_ 659 UI_bsdEnable "3";
BA_ "Confidence" SG_ 659 UI_fcwEnable 0;
BA_ "GenSigSNA" SG_ 659 UI_fcwEnable "3";
BA_ "Confidence" SG_ 659 UI_fcwSensitivity 0;
BA_ "GenSigSNA" SG_ 659 UI_fcwSensitivity "3";
BA_ "Confidence" SG_ 659 UI_latControlEnable 0;
BA_ "GenSigSNA" SG_ 659 UI_latControlEnable "3";
BA_ "Confidence" SG_ 659 UI_ldwEnable 0;
BA_ "GenSigSNA" SG_ 659 UI_ldwEnable "3";
BA_ "Confidence" SG_ 1016 UI_ulcStalkConfirm 0;
BA_ "Confidence" SG_ 1016 UI_lssLkaEnabled 0;
BA_ "Confidence" SG_ 1016 UI_lssLdwEnabled 0;
BA_ "Confidence" SG_ 1016 UI_driveOnMapsEnable 0;
BA_ "Confidence" SG_ 1016 UI_lssElkEnabled 0;
BA_ "Confidence" SG_ 1016 UI_selfParkRequest 0;
BA_ "GenSigSNA" SG_ 1016 UI_selfParkRequest "15";
BA_ "Confidence" SG_ 1016 UI_followNavRouteEnable 0;
BA_ "Confidence" SG_ 1016 UI_ulcSpeedConfig 0;
BA_ "Confidence" SG_ 1016 UI_suppressExitPassingLane 0;
BA_ "Confidence" SG_ 1016 UI_smartSummonType 0;
BA_ "Confidence" SG_ 1016 UI_isaSpeedingChimeMuted 0;
BA_ "Confidence" SG_ 568 UI_roadClass 0;
BA_ "GenSigSNA" SG_ 568 UI_roadClass "0";
BA_ "Confidence" SG_ 568 UI_navRouteActive 0;
BA_ "Confidence" SG_ 568 UI_parallelAutoparkEnabled 0;
BA_ "Confidence" SG_ 568 UI_perpendicularAutoparkEnabled 0;
BA_ "Confidence" SG_ 568 UI_controlledAccess 0;
BA_ "Confidence" SG_ 568 UI_autosteerRestricted 0;
BA_ "Confidence" SG_ 760 UI_mapSpeedLimitUnits 0;
BA_ "Confidence" SG_ 760 UI_mppSpeedLimit 0;
BA_ "Confidence" SG_ 760 UI_gpsNmeaMIA 0;
BA_ "Confidence" SG_ 760 UI_gpsAntennaDisconnected 0;
BA_ "Confidence" SG_ 760 UI_conditionalLimitActive 0;
BA_ "Confidence" SG_ 760 UI_conditionalSpeedLimit 0;
BA_ "GenSigSNA" SG_ 760 UI_conditionalSpeedLimit "31";
BA_ "Confidence" SG_ 1011 UI_odometer 0;
BA_ "GenSigSNA" SG_ 1011 UI_odometer "16777215";
BA_ "Confidence" SG_ 820 UI_pedalMap 0;
BA_ "Confidence" SG_ 820 UI_enableRegenBackfill 0;
BA_ "Confidence" SG_ 820 UI_regenTorqueMax 0;
BA_ "Confidence" SG_ 820 UI_limitMode 0;
BA_ "Confidence" SG_ 820 UI_motorOnMode 0;
BA_ "Confidence" SG_ 820 UI_stoppingMode 0;
BA_ "Confidence" SG_ 820 UI_speedLimit 0;
BA_ "GenSigSNA" SG_ 820 UI_speedLimit "511";
BA_ "Confidence" SG_ 820 UI_enableSmartShift 0;
BA_ "Confidence" SG_ 820 UI_navVehParallelToRdCanContinue 0;
BA_ "GenSigSNA" SG_ 820 UI_navVehParallelToRdCanContinue "0";
BA_ "Confidence" SG_ 723 UI_isSunUp 0;
BA_ "GenSigSNA" SG_ 723 UI_isSunUp "3";
BA_ "Confidence" SG_ 723 UI_solarElevationAngle 0;
BA_ "GenSigSNA" SG_ 723 UI_solarElevationAngle "127";
BA_ "Confidence" SG_ 723 UI_screenPCBTemperature 0;
BA_ "Confidence" SG_ 723 UI_minsToSunset 0;
BA_ "Confidence" SG_ 723 UI_minsToSunrise 0;
BA_ "Confidence" SG_ 851 UI_touchActive 0;
BA_ "Confidence" SG_ 851 UI_audioActive 0;
BA_ "Confidence" SG_ 851 UI_cellActive 0;
BA_ "Confidence" SG_ 851 UI_displayReady 0;
BA_ "Confidence" SG_ 851 UI_displayOn 0;
BA_ "Confidence" SG_ 851 UI_wifiActive 0;
BA_ "Confidence" SG_ 851 UI_wifiConnected 0;
BA_ "Confidence" SG_ 851 UI_readyForDrive 0;
BA_ "Confidence" SG_ 851 UI_cellConnected 0;
BA_ "Confidence" SG_ 851 UI_vpnActive 0;
BA_ "Confidence" SG_ 851 UI_factoryReset 0;
BA_ "GenSigSNA" SG_ 851 UI_factoryReset "0";
BA_ "Confidence" SG_ 851 UI_gpsActive 0;
BA_ "Confidence" SG_ 851 UI_cellNetworkTechnology 0;
BA_ "GenSigSNA" SG_ 851 UI_cellNetworkTechnology "15";
BA_ "Confidence" SG_ 851 UI_falseTouchCounter 0;
BA_ "Confidence" SG_ 851 UI_cellSignalBars 0;
BA_ "GenSigSNA" SG_ 851 UI_cellSignalBars "7";
BA_ "Confidence" SG_ 851 UI_trailerModeTelltale 0;
BA_ "Confidence" SG_ 851 UI_pcbTemperature 0;
BA_ "Confidence" SG_ 851 UI_cpuTemperature 0;
BA_ "Confidence" SG_ 991 UI_userActivity 0;
BA_ "Confidence" SG_ 991 UI_activeTouchPoints 0;
BA_ "Confidence" SG_ 991 UI_linkState 0;
BA_ "Confidence" SG_ 991 UI_autopilotSentryRequest 0;
BA_ "Confidence" SG_ 991 UI_mobileAppConnected 0;
BA_ "Confidence" SG_ 991 UI_phoneLeftInCabin 0;
BA_ "Confidence" SG_ 991 UI_autoshiftDRState 0;
BA_ "Confidence" SG_ 991 UI_wifiBtModuleType 0;
BA_ "Confidence" SG_ 991 UI_selfParkState 0;
BA_ "GenSigSNA" SG_ 991 UI_selfParkState "255";
BA_ "Confidence" SG_ 991 UI_summonDeviceIndex 0;
BA_ "Confidence" SG_ 991 UI_fullScreenMode 0;
BA_ "Confidence" SG_ 952 UI_sendCalibrateTireRequest 0;
BA_ "Confidence" SG_ 852 UI_centerDisplayRunning 0;
BA_ "Confidence" SG_ 852 UI_centerDisplayPowerOn 0;
BA_ "Confidence" SG_ 852 UI_rearDisplayRunning 0;
BA_ "Confidence" SG_ 852 UI_rearDisplayPowerOn 0;
BA_ "Confidence" SG_ 947 UI_gloveboxRequest 0;
BA_ "Confidence" SG_ 947 UI_trunkRequest 0;
BA_ "Confidence" SG_ 947 UI_PINToDriveEnabled 0;
BA_ "Confidence" SG_ 947 UI_PINToDrivePassed 0;
BA_ "Confidence" SG_ 947 UI_disableMirrorAutoDim 0;
BA_ "Confidence" SG_ 947 UI_lightSwitch 0;
BA_ "GenSigSNA" SG_ 947 UI_lightSwitch "4";
BA_ "Confidence" SG_ 947 UI_readyToAddKey 0;
BA_ "Confidence" SG_ 947 UI_alarmTriggerRequest 0;
BA_ "Confidence" SG_ 947 UI_displayOnForUser 0;
BA_ "Confidence" SG_ 947 UI_BLEPushNotificationRequest 0;
BA_ "Confidence" SG_ 947 UI_keepAutopilotAwake 0;
BA_ "Confidence" SG_ 947 UI_batteryPreconditioningRequest 0;
BA_ "Confidence" SG_ 947 UI_autopilotPowerStateRequest 0;
BA_ "Confidence" SG_ 947 UI_autoRollWindowsOnLockEnable 0;
BA_ "Confidence" SG_ 947 UI_steeringWheelHeatReq 0;
BA_ "Confidence" SG_ 947 UI_disableHorn 0;
BA_ "Confidence" SG_ 947 UI_frontLeftSeatFanReq 0;
BA_ "Confidence" SG_ 947 UI_frontRightSeatAutoClimateReq 0;
BA_ "Confidence" SG_ 947 UI_frontRightSeatFanReq 0;
BA_ "Confidence" SG_ 947 UI_frontLeftSeatAutoClimateReq 0;
BA_ "Confidence" SG_ 947 UI_wiperHeaterReq 0;
BA_ "Confidence" SG_ 947 UI_silentAlarm 0;
BA_ "Confidence" SG_ 644 UI_transportMode 0;
BA_ "Confidence" SG_ 644 UI_showroomMode 0;
BA_ "Confidence" SG_ 644 UI_serviceMode 0;
BA_ "Confidence" SG_ 644 UI_carWashMode 0;
BA_ "Confidence" SG_ 644 UI_gameMode 0;
BA_ "Confidence" SG_ 644 UI_serviceModePlus 0;
BA_ "Confidence" SG_ 644 UI_premiumAmpPowerOff 0;
BA_ "Confidence" SG_ 644 UI_lightShowType 0;
BA_ "Confidence" SG_ 644 UI_upkeepMode 0;
BA_ "Confidence" SG_ 807 USM_infoIndex 1;
BA_ "Confidence" SG_ 807 USM_infoBuildType 0;
BA_ "Confidence" SG_ 807 USM_infoBuildConfigId 0;
BA_ "Confidence" SG_ 807 USM_infoHardwareId 0;
BA_ "Confidence" SG_ 807 USM_infoComponentId 0;
BA_ "Confidence" SG_ 807 USM_infoPcbaId 0;
BA_ "Confidence" SG_ 807 USM_infoAssemblyId 0;
BA_ "GenSigSNA" SG_ 807 USM_infoAssemblyId "255";
BA_ "Confidence" SG_ 807 USM_infoUsageId 0;
BA_ "Confidence" SG_ 807 USM_infoSubUsageId 0;
BA_ "Confidence" SG_ 807 USM_infoAppCrc 0;
VAL_ 921 DAS_autopilotState 15 "SNA" 14 "FAULT" 9 "ABORTED" 8 "ABORTING" 6 "ACTIVE_FSD" 5 "ACTIVE_NAV" 4 "ACTIVE_RESTRICTED" 3 "ACTIVE_NOMINAL" 2 "AVAILABLE" 1 "UNAVAILABLE" 0 "DISABLED" ;
VAL_ 921 DAS_blindSpotRearLeft 3 "SNA" 2 "WARNING_LEVEL_2" 1 "WARNING_LEVEL_1" 0 "NO_WARNING" ;
VAL_ 921 DAS_blindSpotRearRight 3 "SNA" 2 "WARNING_LEVEL_2" 1 "WARNING_LEVEL_1" 0 "NO_WARNING" ;
VAL_ 921 DAS_fusedSpeedLimit 31 "NONE" 0 "UNKNOWN_SNA" ;
VAL_ 921 DAS_suppressSpeedWarning 1 "Suppress_Speed_Warning" 0 "Do_Not_Suppress" ;
VAL_ 921 DAS_visionOnlySpeedLimit 31 "NONE" 0 "UNKNOWN_SNA" ;
VAL_ 921 DAS_heaterState 1 "HEATER_ON" 0 "HEATER_OFF_SNA" ;
VAL_ 921 DAS_forwardCollisionWarning 3 "SNA" 1 "FORWARD_COLLISION_WARNING" 0 "NONE" ;
VAL_ 921 DAS_autoparkReady 1 "AUTOPARK_READY" 0 "AUTOPARK_UNAVAILABLE" ;
VAL_ 921 DAS_lssState 7 "LSS_STATE_OFF" 6 "LSS_STATE_ABORT" 5 "LSS_STATE_BLINDSPOT" 4 "LSS_STATE_MONITOR" 3 "LSS_STATE_ELK" 2 "LSS_STATE_LKA" 1 "LSS_STATE_LDW" 0 "LSS_STATE_FAULT" ;
VAL_ 921 DAS_sideCollisionAvoid 3 "SNA" 2 "AVOID_RIGHT" 1 "AVOID_LEFT" 0 "NONE" ;
VAL_ 921 DAS_sideCollisionWarning 3 "WARN_LEFT_RIGHT" 2 "WARN_RIGHT" 1 "WARN_LEFT" 0 "NONE" ;
VAL_ 921 DAS_sideCollisionInhibit 1 "INHIBIT" 0 "NO_INHIBIT" ;
VAL_ 921 DAS_laneDepartureWarning 5 "SNA" 4 "RIGHT_WARNING_SEVERE" 3 "LEFT_WARNING_SEVERE" 2 "RIGHT_WARNING" 1 "LEFT_WARNING" 0 "NONE" ;
VAL_ 921 DAS_fleetSpeedState 3 "FLEETSPEED_HOLD" 2 "FLEETSPEED_ACTIVE" 1 "FLEETSPEED_AVAILABLE" 0 "FLEETSPEED_UNAVAILABLE" ;
VAL_ 921 DAS_autopilotHandsOnState 15 "LC_HANDS_ON_SNA" 10 "LC_HANDS_ON_REQD_ESCALATED_CHIME_2" 9 "LC_HANDS_ON_REQD_ESCALATED_CHIME_1" 8 "LC_HANDS_ON_SUSPENDED" 7 "LC_HANDS_ON_REQD_STRUCK_OUT" 6 "LC_HANDS_ON_REQD_SLOWING" 5 "LC_HANDS_ON_REQD_CHIME_2" 4 "LC_HANDS_ON_REQD_CHIME_1" 3 "LC_HANDS_ON_REQD_VISUAL" 2 "LC_HANDS_ON_REQD_NOT_DETECTED" 1 "LC_HANDS_ON_REQD_DETECTED" 0 "LC_HANDS_ON_NOT_REQD" ;
VAL_ 921 DAS_autoLaneChangeState 31 "ALC_SNA" 30 "ALC_ABORT_MISSION_PLAN_INVALID" 29 "ALC_ABORT_TIMEOUT" 28 "ALC_WAITING_HANDS_ON" 27 "ALC_BLOCKED_LANE_TYPE_R" 26 "ALC_BLOCKED_LANE_TYPE_L" 25 "ALC_BLOCKED_VEH_TTC_AND_USS_R" 24 "ALC_BLOCKED_VEH_TTC_R" 23 "ALC_BLOCKED_VEH_TTC_AND_USS_L" 22 "ALC_BLOCKED_VEH_TTC_L" 21 "ALC_UNAVAILABLE_SOLID_LANE_LINE" 20 "ALC_ABORT_OTHER_REASON" 19 "ALC_ABORT_BLINKER_TURNED_OFF" 18 "ALC_ABORT_LC_HEALTH_BAD" 17 "ALC_ABORT_POOR_VIEW_RANGE" 16 "ALC_ABORT_SIDE_OBSTACLE_PRESENT_R" 15 "ALC_ABORT_SIDE_OBSTACLE_PRESENT_L" 14 "ALC_WAITING_FOR_FWD_OBST_TO_PASS_R" 13 "ALC_WAITING_FOR_FWD_OBST_TO_PASS_L" 12 "ALC_WAITING_FOR_SIDE_OBST_TO_PASS_R" 11 "ALC_WAITING_FOR_SIDE_OBST_TO_PASS_L" 10 "ALC_IN_PROGRESS_R" 9 "ALC_IN_PROGRESS_L" 8 "ALC_AVAILABLE_BOTH" 7 "ALC_AVAILABLE_ONLY_R" 6 "ALC_AVAILABLE_ONLY_L" 5 "ALC_UNAVAILABLE_VEHICLE_SPEED" 4 "ALC_UNAVAILABLE_EXITING_HIGHWAY" 3 "ALC_UNAVAILABLE_TP_FOLLOW" 2 "ALC_UNAVAILABLE_SONICS_INVALID" 1 "ALC_UNAVAILABLE_NO_LANES" 0 "ALC_UNAVAILABLE_DISABLED" ;
VAL_ 905 DAS_accSpeedLimit 511 "SNA" 0 "NONE" ;
VAL_ 905 DAS_pmmObstacleSeverity 7 "PMM_SNA" 6 "PMM_ACCEL_LIMIT" 5 "PMM_CRASH_FRONT" 4 "PMM_CRASH_REAR" 3 "PMM_BRAKE_REQUEST" 2 "PMM_IMMINENT_FRONT" 1 "PMM_IMMINENT_REAR" 0 "PMM_NONE" ;
VAL_ 905 DAS_pmmLoggingRequest 1 "TRUE" 0 "FALSE" ;
VAL_ 905 DAS_activationFailureStatus 2 "LC_ACTIVATION_FAILED_2" 1 "LC_ACTIVATION_FAILED_1" 0 "LC_ACTIVATION_IDLE" ;
VAL_ 905 DAS_pmmUltrasonicsFaultReason 4 "PMM_ULTRASONICS_INVALID_MIA" 3 "PMM_ULTRASONICS_BLOCKED_BOTH" 2 "PMM_ULTRASONICS_BLOCKED_REAR" 1 "PMM_ULTRASONICS_BLOCKED_FRONT" 0 "PMM_ULTRASONICS_NO_FAULT" ;
VAL_ 905 DAS_pmmRadarFaultReason 2 "PMM_RADAR_INVALID_MIA" 1 "PMM_RADAR_BLOCKED_FRONT" 0 "PMM_RADAR_NO_FAULT" ;
VAL_ 905 DAS_pmmSysFaultReason 7 "PMM_FAULT_BRAKE_PEDAL_INHIBIT" 6 "PMM_FAULT_ROAD_TYPE" 5 "PMM_FAULT_DISABLED_BY_USER" 4 "PMM_FAULT_STEERING_ANGLE_RATE" 3 "PMM_FAULT_DI_FAULT" 2 "PMM_FAULT_SPEED" 1 "PMM_FAULT_DAS_DISABLED" 0 "PMM_FAULT_NONE" ;
VAL_ 905 DAS_pmmCameraFaultReason 2 "PMM_CAMERA_INVALID_MIA" 1 "PMM_CAMERA_BLOCKED_FRONT" 0 "PMM_CAMERA_NO_FAULT" ;
VAL_ 905 DAS_ACC_report 24 "ACC_REPORT_BEHAVIOR_REPORT" 23 "ACC_REPORT_CAMERA_ONLY" 22 "ACC_REPORT_RADAR_OBJ_FIVE" 21 "ACC_REPORT_CIPV_CUTTING_OUT" 20 "ACC_REPORT_MCVLR_IN_PATH" 19 "ACC_REPORT_MCVLR_DPP" 18 "ACC_REPORT_FLEET_SPEEDS" 17 "ACC_REPORT_TARGET_MCP" 16 "ACC_REPORT_RADAR_OBJ_TWO" 15 "ACC_REPORT_RADAR_OBJ_ONE" 14 "ACC_REPORT_LC_EXTERNAL_STATE_ACTIVE_RESTRICTED" 13 "ACC_REPORT_LC_EXTERNAL_STATE_ABORTED" 12 "ACC_REPORT_LC_EXTERNAL_STATE_ABORTING" 11 "ACC_REPORT_LC_HANDS_ON_REQD_STRUCK_OUT" 10 "ACC_REPORT_CSA" 9 "ACC_REPORT_TARGET_TYPE_FAULT" 8 "ACC_REPORT_TARGET_TYPE_IPSO" 7 "ACC_REPORT_TARGET_TYPE_TRAFFIC_LIGHT" 6 "ACC_REPORT_TARGET_TYPE_STOP_SIGN" 5 "ACC_REPORT_TARGET_CUTIN" 4 "ACC_REPORT_TARGET_MCVR" 3 "ACC_REPORT_TARGET_MCVL" 2 "ACC_REPORT_TARGET_IN_FRONT_OF_CIPV" 1 "ACC_REPORT_TARGET_CIPV" 0 "ACC_REPORT_TARGET_NONE" ;
VAL_ 905 DAS_csaState 3 "CSA_EXTERNAL_STATE_HOLD" 2 "CSA_EXTERNAL_STATE_ENABLE" 1 "CSA_EXTERNAL_STATE_AVAILABLE" 0 "CSA_EXTERNAL_STATE_UNAVAILABLE" ;
VAL_ 905 DAS_radarTelemetry 2 "RADAR_TELEMETRY_URGENT" 1 "RADAR_TELEMETRY_NORMAL" 0 "RADAR_TELEMETRY_IDLE" ;
VAL_ 905 DAS_robState 3 "ROB_STATE_MAPLESS" 2 "ROB_STATE_ACTIVE" 1 "ROB_STATE_MEASURE" 0 "ROB_STATE_INHIBITED" ;
VAL_ 905 DAS_driverInteractionLevel 2 "CONTINUED_DRIVER_NOT_INTERACTING" 1 "DRIVER_NOT_INTERACTING" 0 "DRIVER_INTERACTING" ;
VAL_ 905 DAS_ppOffsetDesiredRamp 128 "PP_NO_OFFSET" ;
VAL_ 905 DAS_longCollisionWarning 15 "FCM_LONG_COLLISION_WARNING_SNA" 12 "FCM_LONG_COLLISION_WARNING_VEHICLE_CIPV2" 11 "FCM_LONG_COLLISION_WARNING_VEHICLE_MCVR2" 10 "FCM_LONG_COLLISION_WARNING_VEHICLE_MCVR" 9 "FCM_LONG_COLLISION_WARNING_VEHICLE_MCVL2" 8 "FCM_LONG_COLLISION_WARNING_VEHICLE_MCVL" 7 "FCM_LONG_COLLISION_WARNING_VEHICLE_CUTIN" 6 "FCM_LONG_COLLISION_WARNING_VEHICLE_CIPV" 5 "FCM_LONG_COLLISION_WARNING_TFL_STOPLINE" 4 "FCM_LONG_COLLISION_WARNING_STOPSIGN_STOPLINE" 3 "FCM_LONG_COLLISION_WARNING_IPSO" 2 "FCM_LONG_COLLISION_WARNING_PEDESTRIAN" 1 "FCM_LONG_COLLISION_WARNING_VEHICLE_UNKNOWN" 0 "FCM_LONG_COLLISION_WARNING_NONE" ;
VAL_ 586 DAS_autosteerVehiclesUsage 3 "BLACKLISTED" 2 "FUSED" 1 "AVAILABLE" 0 "REJECTED_UNAVAILABLE" ;
VAL_ 586 DAS_autosteerHPPUsage 3 "BLACKLISTED" 2 "FUSED" 1 "AVAILABLE" 0 "REJECTED_UNAVAILABLE" ;
VAL_ 586 DAS_autosteerNavigationUsage 3 "BLACKLISTED" 2 "FUSED" 1 "AVAILABLE" 0 "REJECTED_UNAVAILABLE" ;
VAL_ 586 DAS_autosteerModelUsage 3 "BLACKLISTED" 2 "FUSED" 1 "AVAILABLE" 0 "REJECTED_UNAVAILABLE" ;
VAL_ 586 DAS_autosteerBottsDotsUsage 3 "BLACKLISTED" 2 "FUSED" 1 "AVAILABLE" 0 "REJECTED_UNAVAILABLE" ;
VAL_ 586 DAS_offsetSide 3 "OFFSET_BOTH_OBJECTS" 2 "OFFSET_LEFT_OBJECT" 1 "OFFSET_RIGHT_OBJECT" 0 "NO_OFFSET" ;
VAL_ 586 DAS_roadSurfaceType 2 "ROAD_SURFACE_ENHANCED" 1 "ROAD_SURFACE_NORMAL" 0 "ROAD_SURFACE_SNA" ;
VAL_ 586 DAS_autosteerHealthState 5 "HEALTH_FAULT" 4 "HEALTH_ABORTING" 3 "HEALTH_SEVERELY_DEGRADED" 2 "HEALTH_DEGRADED" 1 "HEALTH_NOMINAL" 0 "HEALTH_UNAVAILABLE" ;
VAL_ 586 DAS_lastLinePreferenceReason 15 "NONE" 5 "COUNTRY_DRIVING_SIDE" 4 "AVOID_ONCOMING_LANES" 3 "NAVIGATION_BRANCH" 2 "NEIGHBOR_LANE_PROBABILIY" 1 "AGREEMENT_WITH_NEIGHBOR_LANES" 0 "OTHER_LANE_DISAGREES_WITH_MODEL" ;
VAL_ 586 DAS_plannerState 7 "TP_EXTSTATE_LANECHANGE_ABORT" 6 "TP_EXTSTATE_LANECHANGE_WAIT_FOR_FWD_OBSTACLE" 5 "TP_EXTSTATE_LANECHANGE_WAIT_FOR_SIDE_OBSTACLE" 4 "TP_EXTSTATE_LANECHANGE_IN_PROGRESS" 3 "TP_EXTSTATE_LANECHANGE_REQUESTED" 2 "TP_EXTSTATE_FOLLOW" 1 "TP_EXTSTATE_VL" 0 "TP_EXTSTATE_DISABLED" ;
VAL_ 586 DAS_lastAutosteerAbortReason 36 "UI_ABORT_REASON_AHB_MANUAL_OVERRIDE" 35 "UI_ABORT_REASON_DRIVER_NOT_PRESENT" 34 "UI_ABORT_REASON_USER_OVERRIDE_STRIKEOUT" 33 "UI_ABORT_REASON_SEATBELT_UNBUCKLED" 32 "UI_ABORT_REASON_AEB" 31 "UI_ABORT_REASON_NO_ABORT" 30 "UI_ABORT_REASON_CAMERA_FAILSAFES" 29 "UI_ABORT_REASON_ACC_CANCEL" 28 "UI_ABORT_REASON_EPAS_ERROR_CODE" 27 "UI_ABORT_REASON_PLANNER_OUTPUT_INVALID" 26 "UI_ABORT_REASON_FOLLOWER_OUTPUT_INVALID" 25 "UI_ABORT_REASON_VEHICLE_SPEED_ABOVE_MAX" 24 "UI_ABORT_REASON_DRIVING_OFF_NAV" 23 "UI_ABORT_REASON_CID_SWITCH_DISABLED" 22 "UI_ABORT_REASON_CRUISE_FAULT" 21 "UI_ABORT_REASON_COMPONENT_MIA" 20 "UI_ABORT_REASON_EPAS_EAC_DENIED" 19 "UI_ABORT_REASON_SIDE_COLLISION_IMMINENT" 18 "UI_ABORT_REASON_TRAILER_MODE" 17 "UI_ABORT_REASON_CAM_WATCHDOG" 16 "UI_ABORT_REASON_CAM_MSG_MIA" 15 "UI_ABORT_REASON_ME_MAIN_STATE_NOT_VISION" 14 "UI_ABORT_REASON_APP_ME_STATE_NOT_VISION" 2 "UI_ABORT_REASON_HM_STEERING_ERROR" 1 "UI_ABORT_REASON_HM_VIRTUAL_LANE_NO_INPUTS" 0 "UI_ABORT_REASON_HM_LANE_VIEW_RANGE" ;
VAL_ 586 DAS_navAvailable 1 "DAS_NAV_AVAILABLE" 0 "DAS_NAV_UNAVAILABLE" ;
VAL_ 586 DAS_accSmartSpeedState 7 "SNA" 5 "OFFRAMP_DELAY" 4 "SET_SPEED_SET_REQUESTED" 3 "ACTIVE_ONRAMP" 2 "ACTIVE_INTEGRATING" 1 "ACTIVE_OFFRAMP" 0 "NOT_ACTIVE" ;
VAL_ 586 DAS_ulcInProgress 1 "ULC_ACTIVE" 0 "ULC_INACTIVE" ;
VAL_ 586 DAS_isaSystemState 3 "ISA_UNAVAILABLE" 2 "ISA_INVALID" 1 "ISA_ASSUMED_LIMITS" 0 "ISA_NOMINAL" ;
VAL_ 586 DAS_behaviorType 3 "DAS_BEHAVIOR_LANE_CHANGE_RIGHT" 2 "DAS_BEHAVIOR_LANE_CHANGE_LEFT" 1 "DAS_BEHAVIOR_IN_LANE" 0 "DAS_BEHAVIOR_INVALID" ;
VAL_ 586 DAS_ulcType 2 "ULC_TYPE_SPEED" 1 "ULC_TYPE_NAV" 0 "ULC_TYPE_NONE" ;
VAL_ 586 DAS_rearVehDetectedThisCycle 1 "VEHICLE_DETECTED" 0 "VEHICLE_NOT_DETECTED" ;
VAL_ 586 DAS_rearLeftVehDetectedCurrent 1 "VEHICLE_DETECTED" 0 "VEHICLE_NOT_DETECTED" ;
VAL_ 586 DAS_rearRightVehDetectedTrip 1 "VEHICLE_DETECTED" 0 "VEHICLE_NOT_DETECTED" ;
VAL_ 586 DAS_rearLeftVehDetectedTrip 1 "VEHICLE_DETECTED" 0 "VEHICLE_NOT_DETECTED" ;
VAL_ 977 EPAS3S_resyncStatus 1 "RESYNC_COMPLETE" 0 "RESYNC_PENDING" ;
VAL_ 785 EPAS3S_infoIndex 255 "END" 31 "SUBCOMPONENT_GITHASH" 30 "PACKAGE_SN_8_14" 29 "PACKAGE_SN_1_7" 27 "PACKAGE_PN_15_20" 26 "PACKAGE_PN_8_14" 25 "PACKAGE_PN_1_7" 23 "SUBCOMPONENT2" 22 "VARIANTCRC" 20 "UDS_PROTOCOL_BOOTCRC" 19 "VERSION_DEPRECATED" 18 "BOOTLOADER_GITHASH" 17 "APP_GITHASH" 16 "SUBCOMPONENT" 15 "BOOTLOADER_CRC" 14 "BOOTLOADER_SVN" 13 "APP_CRC" 11 "PCBAID_ASSYID_USAGEID" 10 "BUILD_HWID_COMPONENTID" 9 "DEPRECATED_9" 8 "DEPRECATED_8" 7 "DEPRECATED_7" 6 "DEPRECATED_6" 5 "DEPRECATED_5" 4 "DEPRECATED_4" 3 "DEPRECATED_3" 2 "DEPRECATED_2" 1 "DEPRECATED_1" 0 "DEPRECATED_0" ;
VAL_ 785 EPAS3S_infoBuildType 4 "INFO_MFG_BUILD" 3 "INFO_TRACEABLE_CI_BUILD" 2 "INFO_LOCAL_BUILD" 1 "INFO_PLATFORM_BUILD" 0 "INFO_UNKNOWN_BUILD" ;
VAL_ 880 EPAS3S_steeringRackForce 1023 "SNA" 1022 "NOT_IN_SPEC" ;
VAL_ 880 EPAS3S_steeringFault 1 "FAULT" 0 "NO_FAULT" ;
VAL_ 880 EPAS3S_steeringReduced 1 "REDUCED_ASSIST" 0 "NORMAL_ASSIST" ;
VAL_ 880 EPAS3S_internalSASQF 1 "IN_SPEC" 0 "UNDEFINABLE_ACCURACY" ;
VAL_ 880 EPAS3S_currentTuneMode 5 "STEERING_TUNE_RWD_SPORT" 4 "STEERING_TUNE_RWD_STANDARD" 3 "STEERING_TUNE_RWD_COMFORT" 2 "STEERING_TUNE_DM_SPORT" 1 "STEERING_TUNE_DM_STANDARD" 0 "STEERING_TUNE_DM_COMFORT" ;
VAL_ 880 EPAS3S_torsionBarTorque 4095 "SNA" 4094 "UNDEFINABLE_DATA" ;
VAL_ 880 EPAS3S_eacErrorCode 15 "SNA" 14 "EAC_EXTERNAL_MONITOR_INHIBIT" 13 "EAC_ERROR_PINION_VEL_DIFF" 12 "EAC_ERROR_LOW_ASSIST" 11 "EAC_ERROR_HIGH_TORSION_SAFETY" 10 "EAC_ERROR_HIGH_MMOT_SAFETY" 9 "EAC_ERROR_HIGH_ANGLE_RATE_SAFETY" 8 "EAC_ERROR_HIGH_ANGLE_SAFETY" 7 "EAC_ERROR_HIGH_ANGLE_RATE_REQ" 6 "EAC_ERROR_HIGH_ANGLE_REQ" 5 "EAR_ERROR_MAX_STEER_DELTA" 4 "EAC_ERROR_TMP_FAULT" 3 "EAC_ERROR_HANDS_ON" 2 "EAC_ERROR_MAX_SPEED" 1 "EAC_ERROR_MIN_SPEED" 0 "EAC_ERROR_IDLE" ;
VAL_ 880 EPAS3S_handsOnLevel 3 "LEVEL_3" 2 "LEVEL_2" 1 "LEVEL_1" 0 "LEVEL_0" ;
VAL_ 880 EPAS3S_driverlessState 1 "EAC_DRIVERLESS_ACTIVE" 0 "EAC_DRIVERLESS_INACTIVE" ;
VAL_ 880 EPAS3S_eacStatus 7 "EAC_ELK_ACTIVE" 6 "EAC_ELK_AVAILABLE" 5 "EAC_LKA_ACTIVE" 4 "EAC_LKA_ELK_AVAILABLE" 3 "EAC_FAULT" 2 "EAC_ACTIVE" 1 "EAC_AVAILABLE" 0 "EAC_INHIBITED" ;
VAL_ 805 ESP_infoIndex 255 "END" 31 "SUBCOMPONENT_GITHASH" 30 "PACKAGE_SN_8_14" 29 "PACKAGE_SN_1_7" 27 "PACKAGE_PN_15_20" 26 "PACKAGE_PN_8_14" 25 "PACKAGE_PN_1_7" 23 "SUBCOMPONENT2" 22 "VARIANTCRC" 20 "UDS_PROTOCOL_BOOTCRC" 19 "VERSION_DEPRECATED" 18 "BOOTLOADER_GITHASH" 17 "APP_GITHASH" 16 "SUBCOMPONENT" 15 "BOOTLOADER_CRC" 14 "BOOTLOADER_SVN" 13 "APP_CRC" 11 "PCBAID_ASSYID_USAGEID" 10 "BUILD_HWID_COMPONENTID" 9 "DEPRECATED_9" 8 "DEPRECATED_8" 7 "DEPRECATED_7" 6 "DEPRECATED_6" 5 "DEPRECATED_5" 4 "DEPRECATED_4" 3 "DEPRECATED_3" 2 "DEPRECATED_2" 1 "DEPRECATED_1" 0 "DEPRECATED_0" ;
VAL_ 805 ESP_infoBuildType 4 "INFO_MFG_BUILD" 3 "INFO_TRACEABLE_CI_BUILD" 2 "INFO_LOCAL_BUILD" 1 "INFO_PLATFORM_BUILD" 0 "INFO_UNKNOWN_BUILD" ;
VAL_ 805 ESP_infoSubUsageID 16 "XCP_Dfive_ESP_CP_CB" 8 "nonXCP_Dfour_ESP_CP_CB" 4 "XCP_Gladiator_ESP" 2 "nonXCP_Rev_C_ESP_Cappella" 0 "nonXCP_Rev_B_ESP_Cappella" ;
VAL_ 805 ESP_infoVehicleVariant 9 "MODEL_3_VARIANT_09" 8 "MODEL_3_VARIANT_08" 7 "MODEL_3_VARIANT_07" 6 "MODEL_3_VARIANT_06" 5 "MODEL_3_VARIANT_05" 4 "MODEL_3_VARIANT_04" 3 "MODEL_3_VARIANT_03" 2 "MODEL_3_VARIANT_02" 1 "MODEL_3_VARIANT_01" ;
VAL_ 813 IBST_infoIndex 255 "END" 31 "SUBCOMPONENT_GITHASH" 30 "PACKAGE_SN_8_14" 29 "PACKAGE_SN_1_7" 27 "PACKAGE_PN_15_20" 26 "PACKAGE_PN_8_14" 25 "PACKAGE_PN_1_7" 23 "SUBCOMPONENT2" 22 "VARIANTCRC" 20 "UDS_PROTOCOL_BOOTCRC" 19 "VERSION_DEPRECATED" 18 "BOOTLOADER_GITHASH" 17 "APP_GITHASH" 16 "SUBCOMPONENT" 15 "BOOTLOADER_CRC" 14 "BOOTLOADER_SVN" 13 "APP_CRC" 11 "PCBAID_ASSYID_USAGEID" 10 "BUILD_HWID_COMPONENTID" 9 "DEPRECATED_9" 8 "DEPRECATED_8" 7 "DEPRECATED_7" 6 "DEPRECATED_6" 5 "DEPRECATED_5" 4 "DEPRECATED_4" 3 "DEPRECATED_3" 2 "DEPRECATED_2" 1 "DEPRECATED_1" 0 "DEPRECATED_0" ;
VAL_ 813 IBST_infoBuildType 4 "INFO_MFG_BUILD" 3 "INFO_TRACEABLE_CI_BUILD" 2 "INFO_LOCAL_BUILD" 1 "INFO_PLATFORM_BUILD" 0 "INFO_UNKNOWN_BUILD" ;
VAL_ 806 PARK_infoIndex 255 "END" 31 "SUBCOMPONENT_GITHASH" 30 "PACKAGE_SN_8_14" 29 "PACKAGE_SN_1_7" 27 "PACKAGE_PN_15_20" 26 "PACKAGE_PN_8_14" 25 "PACKAGE_PN_1_7" 23 "SUBCOMPONENT2" 22 "VARIANTCRC" 20 "UDS_PROTOCOL_BOOTCRC" 19 "VERSION_DEPRECATED" 18 "BOOTLOADER_GITHASH" 17 "APP_GITHASH" 16 "SUBCOMPONENT" 15 "BOOTLOADER_CRC" 14 "BOOTLOADER_SVN" 13 "APP_CRC" 11 "PCBAID_ASSYID_USAGEID" 10 "BUILD_HWID_COMPONENTID" 9 "DEPRECATED_9" 8 "DEPRECATED_8" 7 "DEPRECATED_7" 6 "DEPRECATED_6" 5 "DEPRECATED_5" 4 "DEPRECATED_4" 3 "DEPRECATED_3" 2 "DEPRECATED_2" 1 "DEPRECATED_1" 0 "DEPRECATED_0" ;
VAL_ 806 PARK_infoBuildType 4 "INFO_MFG_BUILD" 3 "INFO_TRACEABLE_CI_BUILD" 2 "INFO_LOCAL_BUILD" 1 "INFO_PLATFORM_BUILD" 0 "INFO_UNKNOWN_BUILD" ;
VAL_ 846 PARK_frontLeftMiddleRawDistData 255 "SNA" ;
VAL_ 846 PARK_frontMiddleRawDistData 255 "SNA" ;
VAL_ 846 PARK_frontRightMiddleRawDistData 255 "SNA" ;
VAL_ 926 PARK_rightSideFrontRawDistData 255 "SNA" ;
VAL_ 926 PARK_rightSideRearRawDistData 255 "SNA" ;
VAL_ 926 PARK_leftSideFrontRawDistData 255 "SNA" ;
VAL_ 926 PARK_leftSideRearRawDistData 255 "SNA" ;
VAL_ 606 PARK_pscEnvSlotType 3 "RIGHT_CROSS" 2 "RIGHT_PARALLEL" 1 "LEFT_CROSS" 0 "LEFT_PARALLEL" ;
VAL_ 606 PARK_pscLeftParallelObj1X 2047 "SNA" 2046 "NO_SPACE" ;
VAL_ 606 PARK_pscLeftParallelObj1Y 2047 "SNA" 2046 "NO_SPACE" ;
VAL_ 606 PARK_pscLeftParallelObj1Alpha 127 "SNA" 126 "NO_SPACE" ;
VAL_ 606 PARK_pscLeftParallelObj2Y 2047 "SNA" 2046 "NO_SPACE" ;
VAL_ 606 PARK_pscLeftParallelObj2X 2047 "SNA" 2046 "NO_SPACE" ;
VAL_ 606 PARK_pscLeftParallelObj2Alpha 127 "SNA" 126 "NO_SPACE" ;
VAL_ 606 PARK_pscLeftCrossObj1X 2047 "SNA" 2046 "NO_SPACE" ;
VAL_ 606 PARK_pscLeftCrossObj1Y 2047 "SNA" 2046 "NO_SPACE" ;
VAL_ 606 PARK_pscLeftCrossObj1Alpha 127 "SNA" 126 "NO_SPACE" ;
VAL_ 606 PARK_pscLeftCrossObj2Y 2047 "SNA" 2046 "NO_SPACE" ;
VAL_ 606 PARK_pscLeftCrossObj2X 2047 "SNA" 2046 "NO_SPACE" ;
VAL_ 606 PARK_pscLeftCrossObj2Alpha 127 "SNA" 126 "NO_SPACE" ;
VAL_ 606 PARK_pscRightParallelObj1X 2047 "SNA" 2046 "NO_SPACE" ;
VAL_ 606 PARK_pscRightParallelObj1Y 2047 "SNA" 2046 "NO_SPACE" ;
VAL_ 606 PARK_pscRightParallelObj1Alpha 127 "SNA" 126 "NO_SPACE" ;
VAL_ 606 PARK_pscRightParallelObj2Y 2047 "SNA" 2046 "NO_SPACE" ;
VAL_ 606 PARK_pscRightParallelObj2X 2047 "SNA" 2046 "NO_SPACE" ;
VAL_ 606 PARK_pscRightParallelObj2Alpha 127 "SNA" 126 "NO_SPACE" ;
VAL_ 606 PARK_pscRightCrossObj1X 2047 "SNA" 2046 "NO_SPACE" ;
VAL_ 606 PARK_pscRightCrossObj1Y 2047 "SNA" 2046 "NO_SPACE" ;
VAL_ 606 PARK_pscRightCrossObj1Alpha 127 "SNA" 126 "NO_SPACE" ;
VAL_ 606 PARK_pscRightCrossObj2Y 2047 "SNA" 2046 "NO_SPACE" ;
VAL_ 606 PARK_pscRightCrossObj2X 2047 "SNA" 2046 "NO_SPACE" ;
VAL_ 606 PARK_pscRightCrossObj2Alpha 127 "SNA" 126 "NO_SPACE" ;
VAL_ 542 PARK_pscParkStatus 7 "SNA" 6 "FAULT" 5 "GUIDANCE_FINISHED" 4 "PRE_GUIDANCE" 3 "GUIDANCE_RIGHT" 2 "GUIDANCE_LEFT" 1 "SEARCHING" 0 "NOT_AVAILABLE" ;
VAL_ 542 PARK_pscParkAbortReason 31 "SNA" 25 "PSC_MOVEMENT_AT_ACTIVATION" 24 "PSC_MAX_WAY_BEHIND_HINT" 23 "PSC_PARK_STC_FAILED" 22 "PSC_PARK_PONR_NOT_REACHED" 21 "PSC_VCTL_GENERAL_ABORT" 20 "PSC_HIGH_TORQUE" 19 "PSC_ASYNC_CTRL_SYSTEM" 18 "ERROR" 17 "SYSTEM_SERVICE" 16 "SYSTEM_FAULT" 15 "ECU_INTERNAL_FAULT" 14 "DAS_ABORT" 13 "EPAS_FAULT" 12 "VEHICLE_DYNAMICS_INTERVENTION" 11 "HANDS_ON_DETECTED" 10 "FULL_WARNING_ON_BOTH_SIDES" 9 "PARK_SPACE_TOO_SMALL" 8 "OBSTACLE_ON_PATH" 7 "MAX_YAW_ANGLE_REACHED" 6 "MAX_SWA_DEV_EXCEEDED" 5 "OFF_TRACK" 4 "UNCONTROLLED_TRAVEL_DIST_REACHED" 3 "NO_VALID_PATH" 2 "MAX_NUM_OF_MOVES" 1 "VELOCITY_TOO_HIGH" 0 "NONE" ;
VAL_ 542 PARK_pscParallelSpace 3 "BOTH_AVAILABLE" 2 "LEFT_AVAILABLE" 1 "RIGHT_AVAILABLE" 0 "NONE_AVAILABLE" ;
VAL_ 542 PARK_pscCrossSpace 3 "BOTH_AVAILABLE" 2 "LEFT_AVAILABLE" 1 "RIGHT_AVAILABLE" 0 "NONE_AVAILABLE" ;
VAL_ 542 PARK_pscParallelRightParkable 3 "SNA" 2 "PARKING_SLOT_OK_POSITION_OK" 1 "PARKING_SLOT_OK" 0 "NONE" ;
VAL_ 542 PARK_pscParallelLeftParkable 3 "SNA" 2 "PARKING_SLOT_OK_POSITION_OK" 1 "PARKING_SLOT_OK" 0 "NONE" ;
VAL_ 542 PARK_pscCrossRightParkable 3 "SNA" 2 "PARKING_SLOT_OK_POSITION_OK" 1 "PARKING_SLOT_OK" 0 "NONE" ;
VAL_ 542 PARK_pscMaxVelocity 63 "SNA" ;
VAL_ 542 PARK_pscCrossLeftParkable 3 "SNA" 2 "PARKING_SLOT_OK_POSITION_OK" 1 "PARKING_SLOT_OK" 0 "NONE" ;
VAL_ 542 PARK_pscParkInstruction 7 "SNA" 5 "EXPLORATION" 4 "ABORTED" 3 "DRIVE_BACKWARD" 2 "DRIVE_FORWARD" 1 "STOP" 0 "NO_MESSAGE" ;
VAL_ 542 PARK_pscManeuverDistance 2047 "SNA" ;
VAL_ 542 PARK_pscAngleActive 1 "REQUEST_CONTROL" 0 "INACTIVE" ;
VAL_ 590 PARK_pscVehSlotType 3 "RIGHT_CROSS" 2 "RIGHT_PARALLEL" 1 "LEFT_CROSS" 0 "LEFT_PARALLEL" ;
VAL_ 590 PARK_pscLeftParallelVehX 2047 "SNA" 2046 "NO_SPACE" ;
VAL_ 590 PARK_pscLeftParallelVehY 2047 "SNA" 2046 "NO_SPACE" ;
VAL_ 590 PARK_pscLeftParallelPsi 8191 "SNA" 8190 "NO_SPACE" ;
VAL_ 590 PARK_pscLeftParallelSizeX 255 "SNA" 254 "NO_SPACE" ;
VAL_ 590 PARK_pscLeftParallelSizeY 255 "SNA" 254 "NO_SPACE" ;
VAL_ 590 PARK_pscLeftCrossVehX 2047 "SNA" 2046 "NO_SPACE" ;
VAL_ 590 PARK_pscLeftCrossVehY 2047 "SNA" 2046 "NO_SPACE" ;
VAL_ 590 PARK_pscLeftCrossPsi 8191 "SNA" 8190 "NO_SPACE" ;
VAL_ 590 PARK_pscLeftCrossSizeX 255 "SNA" 254 "NO_SPACE" ;
VAL_ 590 PARK_pscLeftCrossSizeY 255 "SNA" 254 "NO_SPACE" ;
VAL_ 590 PARK_pscRightParallelVehX 2047 "SNA" 2046 "NO_SPACE" ;
VAL_ 590 PARK_pscRightParallelVehY 2047 "SNA" 2046 "NO_SPACE" ;
VAL_ 590 PARK_pscRightParallelPsi 8191 "SNA" 8190 "NO_SPACE" ;
VAL_ 590 PARK_pscRightParallelSizeX 255 "SNA" 254 "NO_SPACE" ;
VAL_ 590 PARK_pscRightParallelSizeY 255 "SNA" 254 "NO_SPACE" ;
VAL_ 590 PARK_pscRightCrossVehX 2047 "SNA" 2046 "NO_SPACE" ;
VAL_ 590 PARK_pscRightCrossVehY 2047 "SNA" 2046 "NO_SPACE" ;
VAL_ 590 PARK_pscRightCrossPsi 8191 "SNA" 8190 "NO_SPACE" ;
VAL_ 590 PARK_pscRightCrossSizeX 255 "SNA" 254 "NO_SPACE" ;
VAL_ 590 PARK_pscRightCrossSizeY 255 "SNA" 254 "NO_SPACE" ;
VAL_ 526 PARK_sdiSensor1RawDistData 511 "SNA" 500 "NO_OBJECT_DETECTED" 1 "NEAR_DETECTION" 0 "BLOCKED" ;
VAL_ 526 PARK_sdiSensor2RawDistData 511 "SNA" 500 "NO_OBJECT_DETECTED" 1 "NEAR_DETECTION" 0 "BLOCKED" ;
VAL_ 526 PARK_sdiSensor3RawDistData 511 "SNA" 500 "NO_OBJECT_DETECTED" 1 "NEAR_DETECTION" 0 "BLOCKED" ;
VAL_ 526 PARK_sdiSensor4RawDistData 511 "SNA" 500 "NO_OBJECT_DETECTED" 1 "NEAR_DETECTION" 0 "BLOCKED" ;
VAL_ 526 PARK_sdiSensor5RawDistData 511 "SNA" 500 "NO_OBJECT_DETECTED" 1 "NEAR_DETECTION" 0 "BLOCKED" ;
VAL_ 526 PARK_sdiSensor6RawDistData 511 "SNA" 500 "NO_OBJECT_DETECTED" 1 "NEAR_DETECTION" 0 "BLOCKED" ;
VAL_ 558 PARK_sdiSensor7RawDistData 511 "SNA" 500 "NO_OBJECT_DETECTED" 1 "NEAR_DETECTION" 0 "BLOCKED" ;
VAL_ 558 PARK_sdiSensor8RawDistData 511 "SNA" 500 "NO_OBJECT_DETECTED" 1 "NEAR_DETECTION" 0 "BLOCKED" ;
VAL_ 558 PARK_sdiSensor9RawDistData 511 "SNA" 500 "NO_OBJECT_DETECTED" 1 "NEAR_DETECTION" 0 "BLOCKED" ;
VAL_ 558 PARK_sdiSensor10RawDistData 511 "SNA" 500 "NO_OBJECT_DETECTED" 1 "NEAR_DETECTION" 0 "BLOCKED" ;
VAL_ 558 PARK_sdiSensor11RawDistData 511 "SNA" 500 "NO_OBJECT_DETECTED" 1 "NEAR_DETECTION" 0 "BLOCKED" ;
VAL_ 558 PARK_sdiSensor12RawDistData 511 "SNA" 500 "NO_OBJECT_DETECTED" 1 "NEAR_DETECTION" 0 "BLOCKED" ;
VAL_ 814 PARK_frontRightSensorState 3 "SNA" 2 "TEMPORARY_FAILURE" 1 "PERMANENT_FAILURE" 0 "NO_FAILURE" ;
VAL_ 814 PARK_frontRightMiddleSensorState 3 "SNA" 2 "TEMPORARY_FAILURE" 1 "PERMANENT_FAILURE" 0 "NO_FAILURE" ;
VAL_ 814 PARK_frontLeftMiddleSensorState 3 "SNA" 2 "TEMPORARY_FAILURE" 1 "PERMANENT_FAILURE" 0 "NO_FAILURE" ;
VAL_ 814 PARK_frontLeftSensorState 3 "SNA" 2 "TEMPORARY_FAILURE" 1 "PERMANENT_FAILURE" 0 "NO_FAILURE" ;
VAL_ 814 PARK_frontLeftRawDistData 255 "SNA" ;
VAL_ 814 PARK_frontRightRawDistData 255 "SNA" ;
VAL_ 814 PARK_systemStatusFront 3 "SNA" 2 "UNUSED" 1 "ENABLED" 0 "DISABLED" ;
VAL_ 814 PARK_frontDtcPresent 3 "SNA" 2 "UNUSED" 1 "TRUE" 0 "FALSE" ;
VAL_ 830 PARK_rearRightSensorState 3 "SNA" 2 "TEMPORARY_FAILURE" 1 "PERMANENT_FAILURE" 0 "NO_FAILURE" ;
VAL_ 830 PARK_rearRightMiddleSensorState 3 "SNA" 2 "TEMPORARY_FAILURE" 1 "PERMANENT_FAILURE" 0 "NO_FAILURE" ;
VAL_ 830 PARK_rearLeftMiddleSensorState 3 "SNA" 2 "TEMPORARY_FAILURE" 1 "PERMANENT_FAILURE" 0 "NO_FAILURE" ;
VAL_ 830 PARK_rearLeftSensorState 3 "SNA" 2 "TEMPORARY_FAILURE" 1 "PERMANENT_FAILURE" 0 "NO_FAILURE" ;
VAL_ 830 PARK_rearLeftRawDistData 255 "SNA" ;
VAL_ 830 PARK_rearRightRawDistData 255 "SNA" ;
VAL_ 830 PARK_systemStatusRear 3 "SNA" 2 "UNUSED" 1 "ENABLED" 0 "DISABLED" ;
VAL_ 830 PARK_rearDtcPresent 3 "SNA" 2 "UNUSED" 1 "TRUE" 0 "FALSE" ;
VAL_ 798 PARK_status 3 "SNA" 2 "TEMPORARY_FAILURE" 1 "ENABLED" 0 "DISABLED" ;
VAL_ 798 PARK_serviceRequest 3 "SNA" 2 "UNUSED" 1 "FAILURE" 0 "NO_FAILURE" ;
VAL_ 798 PARK_systemDtcPresent 3 "SNA" 2 "UNUSED" 1 "TRUE" 0 "FALSE" ;
VAL_ 798 PARK_majorVersion 255 "SNA" ;
VAL_ 798 PARK_minorVersion 255 "SNA" ;
VAL_ 798 PARK_subMinorVersion 255 "SNA" ;
VAL_ 782 PARK_pscRightCurbType 2 "HIGH_CURB" 1 "LOW_CURB" 0 "VIRTUAL_CURB" ;
VAL_ 782 PARK_pscLeftCurbType 2 "HIGH_CURB" 1 "LOW_CURB" 0 "VIRTUAL_CURB" ;
VAL_ 782 PARK_autoCalComplete 1 "COMPLETE" 0 "INCOMPLETE" ;
VAL_ 782 PARK_geometryType 3 "MODELY" 2 "MODEL3" 1 "MODELX" 0 "MODELS" ;
VAL_ 782 PARK_tireFitment 3 "SNA" 2 "NOT_USED" 1 "STAGGERED" 0 "SQUARE" ;
VAL_ 782 PARK_rackDetected 3 "SNA" 2 "RACK_DETECTED" 1 "NO_RACK" 0 "UNKNOWN" ;
VAL_ 782 PARK_sdiActive 1 "SDI_ENABLED" 0 "SDI_DISABLED" ;
VAL_ 782 PARK_sdiNoise 3 "SDI_NOISE_SNA" 2 "SDI_NOISE_RAIN" 1 "SDI_NOISE_HIGH" 0 "SDI_NOISE_NOMINAL" ;
VAL_ 782 PARK_sdiBlindSpotRight 3 "SNA" 2 "UNUSED" 1 "WARNING" 0 "NO_WARNING" ;
VAL_ 782 PARK_sdiBlindSpotLeft 3 "SNA" 2 "UNUSED" 1 "WARNING" 0 "NO_WARNING" ;
VAL_ 782 PARK_sensorType 3 "SNA" 2 "VALEO_HP" 1 "VALEO_HPFL" 0 "NONE" ;
VAL_ 1329 RADC_infoIndex 20 "Mux20" 19 "Mux19" 13 "Mux13" 11 "Mux11" 10 "Mux10" ;
VAL_ 1329 RADC_infoBuildType 4 "INFO_MFG_BUILD" 3 "INFO_TRACEABLE_CI_BUILD" 2 "INFO_LOCAL_BUILD" 1 "INFO_PLATFORM_BUILD" 0 "INFO_UNKNOWN_BUILD" ;
VAL_ 257 RCM_yawRate -32768 "SNA" ;
VAL_ 257 RCM_pitchRate -16384 "SNA" ;
VAL_ 257 RCM_rollRate -16384 "SNA" ;
VAL_ 257 RCM_rollRateQF 3 "FAULTED" 2 "TEMP_INVALID" 1 "VALID" 0 "INIT" ;
VAL_ 257 RCM_yawRateQF 1 "NOT_FAULTED" 0 "FAULTED" ;
VAL_ 257 RCM_pitchRateQF 3 "FAULTED" 2 "TEMP_INVALID" 1 "VALID" 0 "INIT" ;
VAL_ 273 RCM_longitudinalAccel -32768 "SNA" ;
VAL_ 273 RCM_lateralAccel -32768 "SNA" ;
VAL_ 273 RCM_verticalAccel -32768 "SNA" ;
VAL_ 273 RCM_longitudinalAccelQF 1 "NOT_FAULTED" 0 "FAULTED" ;
VAL_ 273 RCM_lateralAccelQF 1 "NOT_FAULTED" 0 "FAULTED" ;
VAL_ 273 RCM_verticalAccelQF 1 "NOT_FAULTED" 0 "FAULTED" ;
VAL_ 273 RCM_CGTranslationFault 1 "RCM_COG_TRANSLATION_FAULTED" 0 "RCM_COG_TRANSLATION_NOT_FAULTED" ;
VAL_ 849 RCM_infoIndex 255 "END" 31 "SUBCOMPONENT_GITHASH" 30 "PACKAGE_SN_8_14" 29 "PACKAGE_SN_1_7" 27 "PACKAGE_PN_15_20" 26 "PACKAGE_PN_8_14" 25 "PACKAGE_PN_1_7" 23 "SUBCOMPONENT2" 22 "VARIANTCRC" 20 "UDS_PROTOCOL_BOOTCRC" 19 "VERSION_DEPRECATED" 18 "BOOTLOADER_GITHASH" 17 "APP_GITHASH" 16 "SUBCOMPONENT" 15 "BOOTLOADER_CRC" 14 "BOOTLOADER_SVN" 13 "APP_CRC" 11 "PCBAID_ASSYID_USAGEID" 10 "BUILD_HWID_COMPONENTID" 9 "DEPRECATED_9" 8 "DEPRECATED_8" 7 "DEPRECATED_7" 6 "DEPRECATED_6" 5 "DEPRECATED_5" 4 "DEPRECATED_4" 3 "DEPRECATED_3" 2 "DEPRECATED_2" 1 "DEPRECATED_1" 0 "DEPRECATED_0" ;
VAL_ 849 RCM_infoBuildType 4 "INFO_MFG_BUILD" 3 "INFO_TRACEABLE_CI_BUILD" 2 "INFO_LOCAL_BUILD" 1 "INFO_PLATFORM_BUILD" 0 "INFO_UNKNOWN_BUILD" ;
VAL_ 529 RCM_armStatus 3 "SNA" 2 "ARMED_WITH_NOFIRE_CAL" 1 "RCM_ARMED" 0 "RCM_UNARMED" ;
VAL_ 529 RCM_warningIndicatorState 3 "SNA" 1 "RCM_WARNING_INDICATOR_ON" 0 "RCM_WARNING_INDICATOR_OFF" ;
VAL_ 529 RCM_passAirbagIndicatorRequest 3 "SNA" 1 "RCM_PASSENGER_AIRBAG_INDICATOR_OFF" 0 "RCM_PASSENGER_AIRBAG_INDICATOR_ON" ;
VAL_ 529 RCM_airbagCutoffStatus 3 "SNA" 1 "RCM_PASSENGER_AIRBAG_DISABLED" 0 "RCM_PASSENGER_AIRBAG_ENABLED" ;
VAL_ 529 RCM_alrSwitchStatus 3 "SNA" 2 "RCM_ALR_FAULTED" 1 "RCM_ALR_ENGAGED" 0 "RCM_ALR_NOT_ENGAGED" ;
VAL_ 529 RCM_vinLearnFlag 3 "SNA" 2 "RCM_VIN_STORED_MISMATCH" 1 "RCM_VIN_STORED" 0 "RCM_VIN_NOT_STORED" ;
VAL_ 529 RCM_seatTrackPositionDrvr 3 "SNA" 2 "RCM_SEAT_POSITION_FAULTED" 1 "RCM_SEAT_POSITION_FAR" 0 "RCM_SEAT_POSITION_NEAR" ;
VAL_ 529 RCM_seatTrackPositionPass 3 "SNA" 2 "RCM_SEAT_POSITION_FAULTED" 1 "RCM_SEAT_POSITION_FAR" 0 "RCM_SEAT_POSITION_NEAR" ;
VAL_ 529 RCM_edr1State 3 "RCM_EDR_UNAVAILABLE" 2 "RCM_EDR_LOCKED" 1 "RCM_EDR_STORED" 0 "RCM_EDR_EMPTY" ;
VAL_ 529 RCM_edr2State 3 "RCM_EDR_UNAVAILABLE" 2 "RCM_EDR_LOCKED" 1 "RCM_EDR_STORED" 0 "RCM_EDR_EMPTY" ;
VAL_ 529 RCM_keepPowerReason 8 "RCM_KEEP_POWER_REASON_SNA" 7 "RCM_INVALID_POWER_OFF_REQUEST" 6 "RCM_INITIALIZATION_PHASE" 5 "RCM_CANNOT_POWER_DOWN" 4 "RCM_EDR_UPLOADING" 3 "RCM_EDR_STORING_TO_EEPROM" 2 "RCM_CRASH_ALGO_ACTIVE" 1 "RCM_IN_IDLE_MODE" 0 "RCM_NO_KEEP_POWER_REQUEST" ;
VAL_ 529 RCM_imuOffsetLearnState 3 "IMU_OFFSETS_UNABLE_TO_LEARN" 2 "IMU_FAST_LEARNING_TIME" 1 "IMU_SLOW_LEARNING_DISTANCE" 0 "IMU_OFFSET_LEARNING_OFF" ;
VAL_ 529 RCM_edr3State 3 "RCM_EDR_UNAVAILABLE" 2 "RCM_EDR_LOCKED" 1 "RCM_EDR_STORED" 0 "RCM_EDR_EMPTY" ;
VAL_ 529 RCM_driverOrientationInitStatus 7 "SNA" 4 "RCM_DRIVER_ORIENTATION_MISMATCH_DEFAULT_RHD" 3 "RCM_DRIVER_ORIENTATION_MISMATCH_DEFAULT_LHD" 2 "RCM_DRIVER_ORIENTATION_MATCHED_RHD" 1 "RCM_DRIVER_ORIENTATION_MATCHED_LHD" 0 "RCM_DRIVER_ORIENTATION_INIT_NOT_COMPLETE" ;
VAL_ 529 RCM_occupantClassificationSource 1 "VCRIGHT_CLASSIFICATION_SOURCE" 0 "OCS1P_CLASSIFICATION_SOURCE" ;
VAL_ 529 RCM_pedProEDR1State 3 "RCM_EDR_UNAVAILABLE" 2 "RCM_EDR_LOCKED" 1 "RCM_EDR_STORED" 0 "RCM_EDR_EMPTY" ;
VAL_ 529 RCM_pedProEDR2State 3 "RCM_EDR_UNAVAILABLE" 2 "RCM_EDR_LOCKED" 1 "RCM_EDR_STORED" 0 "RCM_EDR_EMPTY" ;
VAL_ 879 TPMS_learningStatus 3 "PASSED" 2 "STOPPED" 1 "ONGOING" 0 "FAILED" ;
VAL_ 879 TPMS_localisationStatus 3 "PASSED" 2 "STOPPED" 1 "ONGOING" 0 "FAILED" ;
VAL_ 799 TPMS_pressureFL 255 "SNA" 254 "OVER_RANGE" ;
VAL_ 799 TPMS_temperatureFL 255 "TPMS_TEMPERATURE_SNA" ;
VAL_ 799 TPMS_pressureFR 255 "SNA" 254 "OVER_RANGE" ;
VAL_ 799 TPMS_temperatureFR 255 "TPMS_TEMPERATURE_SNA" ;
VAL_ 799 TPMS_pressureRL 255 "SNA" 254 "OVER_RANGE" ;
VAL_ 799 TPMS_temperatureRL 255 "TPMS_TEMPERATURE_SNA" ;
VAL_ 799 TPMS_pressureRR 255 "SNA" 254 "OVER_RANGE" ;
VAL_ 799 TPMS_temperatureRR 255 "TPMS_TEMPERATURE_SNA" ;
VAL_ 1519 TPMS_infoIndex 255 "END" 31 "SUBCOMPONENT_GITHASH" 30 "PACKAGE_SN_8_14" 29 "PACKAGE_SN_1_7" 27 "PACKAGE_PN_15_20" 26 "PACKAGE_PN_8_14" 25 "PACKAGE_PN_1_7" 23 "SUBCOMPONENT2" 22 "VARIANTCRC" 20 "UDS_PROTOCOL_BOOTCRC" 19 "VERSION_DEPRECATED" 18 "BOOTLOADER_GITHASH" 17 "APP_GITHASH" 16 "SUBCOMPONENT" 15 "BOOTLOADER_CRC" 14 "BOOTLOADER_SVN" 13 "APP_CRC" 11 "PCBAID_ASSYID_USAGEID" 10 "BUILD_HWID_COMPONENTID" 9 "DEPRECATED_9" 8 "DEPRECATED_8" 7 "DEPRECATED_7" 6 "DEPRECATED_6" 5 "DEPRECATED_5" 4 "DEPRECATED_4" 3 "DEPRECATED_3" 2 "DEPRECATED_2" 1 "DEPRECATED_1" 0 "DEPRECATED_0" ;
VAL_ 850 TRCM_infoIndex 255 "END" 41 "SUBCOMPONENT14" 40 "SUBCOMPONENT13" 39 "SUBCOMPONENT12" 38 "SUBCOMPONENT11" 37 "SUBCOMPONENT10" 36 "SUBCOMPONENT9" 35 "SUBCOMPONENT8" 34 "SUBCOMPONENT7" 33 "SUBCOMPONENT6" 32 "SUBCOMPONENT5" 31 "SUBCOMPONENT4" 24 "SUBCOMPONENT3" 23 "SUBCOMPONENT2" 20 "UDS_PROTOCOL_BOOTCRC" 19 "VERSION_DEPRECATED" 18 "BOOTLOADER_GITHASH" 17 "APP_GITHASH" 16 "SUBCOMPONENT1" 15 "BOOTLOADER_CRC" 14 "BOOTLOADER_SVN" 13 "APP_CRC" 11 "PCBAID_ASSYID_USAGEID" 10 "BUILD_HWID_COMPONENTID" 9 "DEPRECATED_9" 8 "DEPRECATED_8" 7 "DEPRECATED_7" 6 "DEPRECATED_6" 5 "DEPRECATED_5" 4 "DEPRECATED_4" 3 "DEPRECATED_3" 2 "DEPRECATED_2" 1 "DEPRECATED_1" 0 "DEPRECATED_0" ;
VAL_ 850 TRCM_infoBuildType 4 "INFO_MFG_BUILD" 3 "INFO_TRACEABLE_CI_BUILD" 2 "INFO_LOCAL_BUILD" 1 "INFO_PLATFORM_BUILD" 0 "INFO_UNKNOWN_BUILD" ;
VAL_ 850 TRCM_infoAssemblyId 255 "ASSEMBLY_SNA" 1 "ASSEMBLY1" ;
VAL_ 1021 UI_autopilotControlIndex 7 "7" 6 "6" 5 "5" 4 "4" 3 "3" 2 "2" 1 "1" 0 "0" ;
VAL_ 1021 UI_hovEnabled 1 "HOV_ON" 0 "HOV_OFF" ;
VAL_ 1021 UI_smartSetSpeedOffsetType 1 "PERCENTAGE_OFFSET" 0 "FIXED_OFFSET" ;
VAL_ 1021 UI_autosteerActivation 1 "DOUBLE_CLICK" 0 "SINGLE_CLICK" ;
VAL_ 1021 UI_fsdBetaRequest 1 "FSD_REQUEST_ACTIVE" 0 "FSD_REQUEST_NOT_ACTIVE" ;
VAL_ 1021 UI_selectableCameraRequest 15 "SNA" 13 "REPEATERS_BACKUP" 12 "FASCIA" 11 "GRID_VIEW" 10 "OCTA" 9 "BACKUP" 8 "RIGHT_REPEATER" 7 "RIGHT_PILLAR" 6 "LEFT_REPEATER" 5 "LEFT_PILLAR" 4 "FRONT_NARROW" 3 "FRONT_FISHEYE" 2 "FRONT_MAIN" 1 "SELFIE" 0 "NONE" ;
VAL_ 1021 UI_autoTurnSignalMode 1 "UI_AUTO_TURN_SIGNAL_MODE_AUTO_CANCEL" 0 "UI_AUTO_TURN_SIGNAL_MODE_OFF" ;
VAL_ 1021 UI_autopilotDrivingProfile 4 "CONSERVATIVE" 3 "MAD_MAX" 2 "ASSERTIVE" 1 "NORMAL" 0 "CHILL" ;
VAL_ 659 UI_steeringTuneRequest 2 "STEERING_TUNE_SPORT" 1 "STEERING_TUNE_STANDARD" 0 "STEERING_TUNE_COMFORT" ;
VAL_ 659 UI_tractionControlMode 7 "TC_SLIPPERY_SURFACE_SELECTED" 6 "TC_OFFROAD_ASSIST_SELECTED" 5 "TC_DYNO_MODE_SELECTED" 4 "TC_ROLLS_MODE_SELECTED" 3 "TC_DEV_MODE_2_SELECTED" 2 "TC_DEV_MODE_1_SELECTED" 1 "TC_SLIP_START_SELECTED" 0 "TC_NORMAL_SELECTED" ;
VAL_ 659 UI_parkBrakeRequest 3 "PARK_BRAKE_REQUEST_SNA" 1 "PARK_BRAKE_REQUEST_PRESSED" 0 "PARK_BRAKE_REQUEST_IDLE" ;
VAL_ 659 UI_winchModeRequest 3 "WINCH_MODE_DIALOGUE_OPEN" 2 "WINCH_MODE_EXIT" 1 "WINCH_MODE_ENTER" 0 "WINCH_MODE_IDLE" ;
VAL_ 659 UI_trailerMode 1 "TRAILER_MODE_ON" 0 "TRAILER_MODE_OFF" ;
VAL_ 659 UI_accOvertakeEnable 3 "SNA" 1 "ACC_OVERTAKE_ON" 0 "ACC_OVERTAKE_OFF" ;
VAL_ 659 UI_aebEnable 3 "SNA" 1 "AEB_ON" 0 "AEB_OFF" ;
VAL_ 659 UI_aesEnable 3 "SNA" 1 "AES_ON" 0 "AES_OFF" ;
VAL_ 659 UI_ahlbEnable 3 "SNA" 1 "AHLB_ON" 0 "AHLB_OFF" ;
VAL_ 659 UI_autoLaneChangeEnable 3 "SNA" 1 "ON" 0 "OFF" ;
VAL_ 659 UI_autoParkRequest 15 "SNA" 12 "BEGIN_PARKING" 11 "RESUME" 10 "PAUSE" 9 "SEARCH" 8 "COMPLETE" 7 "ABORT" 6 "PARALLEL_PULL_OUT_TO_RIGHT" 5 "PARALLEL_PULL_OUT_TO_LEFT" 4 "PARK_RIGHT_CROSS" 3 "PARK_RIGHT_PARALLEL" 2 "PARK_LEFT_CROSS" 1 "PARK_LEFT_PARALLEL" 0 "NONE" ;
VAL_ 659 UI_bsdEnable 3 "SNA" 1 "BSD_ON" 0 "BSD_OFF" ;
VAL_ 659 UI_fcwEnable 3 "SNA" 1 "FCW_ON" 0 "FCW_OFF" ;
VAL_ 659 UI_fcwSensitivity 3 "SNA" 2 "AEB_SENSITIVITY_LATE" 1 "AEB_SENSITIVITY_AVERAGE" 0 "AEB_SENSITIVITY_EARLY" ;
VAL_ 659 UI_latControlEnable 3 "LATERAL_CONTROL_SNA" 2 "LATERAL_CONTROL_UNAVAILABLE" 1 "LATERAL_CONTROL_ON" 0 "LATERAL_CONTROL_OFF" ;
VAL_ 659 UI_ldwEnable 3 "SNA" 1 "LDW_TRIGGERS_HAPTIC" 0 "NO_HAPTIC" ;
VAL_ 1016 UI_lssLkaEnabled 1 "LKA_ON" 0 "LKA_OFF" ;
VAL_ 1016 UI_lssLdwEnabled 1 "LDW_ON" 0 "LDW_OFF" ;
VAL_ 1016 UI_driveOnMapsEnable 1 "DOM_ON" 0 "DOM_OFF" ;
VAL_ 1016 UI_lssElkEnabled 1 "ELK_ON" 0 "ELK_OFF" ;
VAL_ 1016 UI_selfParkRequest 15 "SNA" 12 "SMART_SUMMON_NO_OP" 11 "SMART_SUMMON" 10 "AUTO_SUMMON_PRIMED" 9 "AUTO_SUMMON_CANCEL" 8 "AUTO_SUMMON_REVERSE" 7 "AUTO_SUMMON_FORWARD" 6 "RESUME" 5 "PAUSE" 4 "PRIME" 3 "ABORT" 2 "SELF_PARK_REVERSE" 1 "SELF_PARK_FORWARD" 0 "NONE" ;
VAL_ 1016 UI_followNavRouteEnable 1 "NAV_ROUTE_ON" 0 "NAV_ROUTE_OFF" ;
VAL_ 1016 UI_ulcSpeedConfig 3 "SPEED_BASED_ULC_MAD_MAX" 2 "SPEED_BASED_ULC_AVERAGE" 1 "SPEED_BASED_ULC_MILD" 0 "SPEED_BASED_ULC_DISABLED" ;
VAL_ 1016 UI_smartSummonType 2 "SMART_AUTOPARK" 1 "FIND_ME" 0 "PIN_DROP" ;
VAL_ 568 UI_roadClass 6 "CLASS_6_MINOR" 5 "CLASS_5" 4 "CLASS_4" 3 "CLASS_3" 2 "CLASS_2" 1 "CLASS_1_MAJOR" 0 "UNKNOWN_INVALID_SNA" ;
VAL_ 760 UI_mapSpeedLimitUnits 1 "KPH" 0 "MPH" ;
VAL_ 760 UI_conditionalSpeedLimit 31 "SNA" ;
VAL_ 1011 UI_odometer 16777215 "SNA" ;
VAL_ 820 UI_pedalMap 2 "PERFORMANCE" 1 "SPORT" 0 "CHILL" ;
VAL_ 820 UI_limitMode 3 "LIMIT_SERVICE" 2 "LIMIT_FACTORY" 1 "LIMIT_VALET" 0 "LIMIT_NORMAL" ;
VAL_ 820 UI_motorOnMode 2 "MOTORONMODE_REAR_ONLY" 1 "MOTORONMODE_FRONT_ONLY" 0 "MOTORONMODE_NORMAL" ;
VAL_ 820 UI_stoppingMode 2 "HOLD" 1 "CREEP" 0 "STANDARD" ;
VAL_ 820 UI_speedLimit 511 "SNA" ;
VAL_ 820 UI_enableSmartShift 2 "ENABLED_P_R_D" 1 "ENABLED_P" 0 "OFF" ;
VAL_ 820 UI_navVehParallelToRdCanContinue 2 "TRUE" 1 "FALSE" 0 "SNA" ;
VAL_ 723 UI_isSunUp 3 "SUN_SNA" 1 "SUN_UP" 0 "SUN_DOWN" ;
VAL_ 723 UI_solarElevationAngle 127 "SNA" ;
VAL_ 851 UI_factoryReset 3 "CUSTOMER" 2 "DIAGNOSTIC" 1 "DEVELOPER" 0 "NONE_SNA" ;
VAL_ 851 UI_cellNetworkTechnology 15 "CELL_NETWORK_SNA" 14 "CELL_NETWORK_NGRAN" 13 "CELL_NETWORK_5GSA" 12 "CELL_NETWORK_5GNSA" 11 "CELL_NETWORK_LTE5GCN" 10 "CELL_NETWORK_WCDMA" 9 "CELL_NETWORK_CDMA" 8 "CELL_NETWORK_GSM" 7 "CELL_NETWORK_LTE" 6 "CELL_NETWORK_HSPA" 5 "CELL_NETWORK_HSUPA" 4 "CELL_NETWORK_HSDPA" 3 "CELL_NETWORK_UMTS" 2 "CELL_NETWORK_EDGE" 1 "CELL_NETWORK_GPRS" 0 "CELL_NETWORK_NONE" ;
VAL_ 851 UI_cellSignalBars 7 "SNA" 5 "FIVE" 4 "FOUR" 3 "THREE" 2 "TWO" 1 "ONE" 0 "ZERO" ;
VAL_ 851 UI_trailerModeTelltale 3 "TRAILER_MODE_TELLTALE_RED" 2 "TRAILER_MODE_TELLTALE_YELLOW" 1 "TRAILER_MODE_TELLTALE_BLUE" 0 "TRAILER_MODE_TELLTALE_OFF" ;
VAL_ 991 UI_userActivity 1 "USER_ACTIVE" 0 "USER_IDLE" ;
VAL_ 991 UI_linkState 2 "LINK_STATE_WIFI" 1 "LINK_STATE_CELL" 0 "LINK_STATE_NONE" ;
VAL_ 991 UI_mobileAppConnected 1 "CONNECTED" 0 "NOT_CONNECTED" ;
VAL_ 991 UI_autoshiftDRState 6 "AUTOSHIFT_DR_STATE_BRAKE_GEAR_SHIFT_CONFIRMED_D" 5 "AUTOSHIFT_DR_STATE_BRAKE_GEAR_SHIFT_CONFIRMED_R" 4 "AUTOSHIFT_DR_STATE_BRAKE_STEERING_AND_BRAKE_CONFIRMED" 3 "AUTOSHIFT_DR_STATE_ONLY_STEERING_CONFIRMED" 2 "AUTOSHIFT_DR_STATE_ONLY_BRAKE_CONFIRMED" 1 "AUTOSHIFT_DR_STATE_PROMPT_SHOWING_UNCONFIRMED" 0 "AUTOSHIFT_DR_STATE_INACTIVE" ;
VAL_ 991 UI_wifiBtModuleType 4 "ELEKTRA" 3 "TCU4G" 2 "BCM4359" 1 "QCA6595" 0 "UNKNOWN" ;
VAL_ 991 UI_selfParkState 255 "SNA" 52 "SELF_PARK_USER_PAUSED" 51 "SELF_PARK_REMOTE_PRE_ABORT" 50 "SELF_PARK_RESUME" 49 "SELF_PARK_PAUSE" 48 "SELF_PARK_DV_MISMATCH" 47 "SELF_PARK_DI_PANIC" 46 "SELF_PARK_POST_ACTIVE_FAILURE" 45 "SELF_PARK_POST_ACTIVE_SUCCESS" 44 "SELF_PARK_CANCEL_AUTO_SUMMON" 43 "SELF_PARK_REMOTE_ABORT" 42 "SELF_PARK_OBSTACLE_NOT_CLEARED" 41 "SELF_PARK_OBSTACLE_CLEARED" 40 "SELF_PARK_OPEN_GATE" 39 "SELF_PARK_ACTIVE" 38 "SELF_PARK_STARTED_REVERSE" 37 "SELF_PARK_STARTED_FORWARD" 36 "SELF_PARK_NOT_STARTED_TIMEOUT" 35 "SELF_PARK_PRIMED" 34 "SELF_PARK_PREPRIMED" 33 "SELF_PARK_TURN_ON_DRIVE_RAIL" 32 "SELF_PARK_DETECT_KEY_FOB" 31 "SELF_PARK_WAKE_UP_BUSES" 30 "SELF_PARK_CONNECTING_BLUETOOTH" 29 "SELF_PARK_UNAVAILABLE_CAR_WASH_MODE" 28 "SELF_PARK_UNAVAILABLE_CAR_ALARM" 27 "SELF_PARK_UNAVAILABLE_CRASH_STATE" 26 "SELF_PARK_UNAVAILABLE_DRAG_STRIP_MODE" 25 "SELF_PARK_UNAVAILABLE_TRACK_MODE" 24 "SELF_PARK_UNAVAILABLE_SERVICE_MODE" 23 "SELF_PARK_UNAVAILABLE_DOG_MODE" 22 "SELF_PARK_UNAVAILABLE_GAME_MODE" 21 "SELF_PARK_UNAVAILABLE_BLUETOOTH_CONNECT_TIMEOUT" 20 "SELF_PARK_UNAVAILABLE_WAKEUP_TIMEOUT" 19 "SELF_PARK_UNAVAILABLE_NO_BLUETOOTH_DEVICES_PAIRED" 18 "SELF_PARK_UNAVAILABLE_BRAKE_PRESSED" 17 "SELF_PARK_UNAVAILABLE_ROAD_GRADE" 16 "SELF_PARK_UNAVAILABLE_TRAILER_MODE" 15 "SELF_PARK_UNAVAILABLE_KEY_FOB_BATTERY_LOW" 14 "SELF_PARK_UNAVAILABLE_KEY_FOB_NOT_DETECTED" 13 "SELF_PARK_UNAVAILABLE_PARK_SENSOR_ISSUE" 12 "SELF_PARK_UNAVAILABLE_AUTOSTEER_NOT_ENABLED" 11 "SELF_PARK_UNAVAILABLE_LV_BUS_SUPPORT_ISSUE" 10 "SELF_PARK_UNAVAILABLE_ON_PUBLIC_ROAD" 9 "SELF_PARK_UNAVAILABLE_PARKED_TOO_LONG" 8 "SELF_PARK_UNAVAILABLE_DOOR_OPEN" 7 "SELF_PARK_UNAVAILABLE_TRUNK_OPEN" 6 "SELF_PARK_UNAVAILABLE_FRUNK_OPEN" 5 "SELF_PARK_UNAVAILABLE_PLUGGED_IN" 4 "SELF_PARK_UNAVAILABLE_NOT_PARKED" 3 "SELF_PARK_UNAVAILABLE" 2 "SELF_PARK_IDLE" 1 "SELF_PARK_DRIVING" 0 "SELF_PARK_DISABLED" ;
VAL_ 991 UI_summonDeviceIndex 3 "UNKNOWN" 2 "DEVICE_2" 1 "DEVICE_1" 0 "DEVICE_0" ;
VAL_ 947 UI_lightSwitch 4 "LIGHT_SWITCH_SNA" 3 "LIGHT_SWITCH_OFF" 2 "LIGHT_SWITCH_PARKING" 1 "LIGHT_SWITCH_ON" 0 "LIGHT_SWITCH_AUTO" ;
VAL_ 947 UI_autopilotPowerStateRequest 2 "AUTOPILOT_SUSPEND" 1 "AUTOPILOT_SENTRY" 0 "AUTOPILOT_NOMINAL" ;
VAL_ 947 UI_frontLeftSeatFanReq 3 "FAN_REQUEST_LEVEL3" 2 "FAN_REQUEST_LEVEL2" 1 "FAN_REQUEST_LEVEL1" 0 "FAN_REQUEST_OFF" ;
VAL_ 947 UI_frontRightSeatFanReq 3 "FAN_REQUEST_LEVEL3" 2 "FAN_REQUEST_LEVEL2" 1 "FAN_REQUEST_LEVEL1" 0 "FAN_REQUEST_OFF" ;
VAL_ 644 UI_transportMode 1 "TRANSPORT_MODE_ENABLED" 0 "TRANSPORT_MODE_DISABLED" ;
VAL_ 644 UI_showroomMode 1 "SHOWROOM_MODE_ENABLED" 0 "SHOWROOM_MODE_DISABLED" ;
VAL_ 644 UI_serviceMode 1 "SERVICE_MODE_ENABLED" 0 "SERVICE_MODE_DISABLED" ;
VAL_ 644 UI_serviceModePlus 1 "SERVICE_MODE_PLUS_ENABLED" 0 "SERVICE_MODE_PLUS_DISABLED" ;
VAL_ 644 UI_lightShowType 5 "LIGHT_SHOW_TYPE_STANDARD_CNY24" 4 "LIGHT_SHOW_TYPE_STANDARD_THE_ARRIVAL" 3 "LIGHT_SHOW_TYPE_STANDARD_CNY23" 2 "LIGHT_SHOW_TYPE_STANDARD_AULD_LANG_SYNE" 1 "LIGHT_SHOW_TYPE_STANDARD_CAROL_OF_THE_BELLS" 0 "LIGHT_SHOW_TYPE_CUSTOM_USB" ;
VAL_ 644 UI_upkeepMode 1 "UI_UPKEEPMODE_ENABLED" 0 "UI_UPKEEPMODE_DISABLED" ;
VAL_ 807 USM_infoIndex 255 "END" 41 "SUBCOMPONENT14" 40 "SUBCOMPONENT13" 39 "SUBCOMPONENT12" 38 "SUBCOMPONENT11" 37 "SUBCOMPONENT10" 36 "SUBCOMPONENT9" 35 "SUBCOMPONENT8" 34 "SUBCOMPONENT7" 33 "SUBCOMPONENT6" 32 "SUBCOMPONENT5" 31 "SUBCOMPONENT4" 24 "SUBCOMPONENT3" 23 "SUBCOMPONENT2" 20 "UDS_PROTOCOL_BOOTCRC" 19 "VERSION_DEPRECATED" 18 "BOOTLOADER_GITHASH" 17 "APP_GITHASH" 16 "SUBCOMPONENT1" 15 "BOOTLOADER_CRC" 14 "BOOTLOADER_SVN" 13 "APP_CRC" 11 "PCBAID_ASSYID_USAGEID" 10 "BUILD_HWID_COMPONENTID" 9 "DEPRECATED_9" 8 "DEPRECATED_8" 7 "DEPRECATED_7" 6 "DEPRECATED_6" 5 "DEPRECATED_5" 4 "DEPRECATED_4" 3 "DEPRECATED_3" 2 "DEPRECATED_2" 1 "DEPRECATED_1" 0 "DEPRECATED_0" ;
VAL_ 807 USM_infoBuildType 4 "INFO_MFG_BUILD" 3 "INFO_TRACEABLE_CI_BUILD" 2 "INFO_LOCAL_BUILD" 1 "INFO_PLATFORM_BUILD" 0 "INFO_UNKNOWN_BUILD" ;
VAL_ 807 USM_infoAssemblyId 255 "ASSEMBLY_SNA" 1 "ASSEMBLY1" ;
